VERSION ""

NS_ :

BS_:

BU_: PowertrainControlModule AtmosphericSensor SafetyRestraintSystem2 Aftertreatment_2_GasOutlet Aftertreatment_2_GasIntake DieselParticulateFilterControl Turbocharger SafetyRestraintSystem1 CabDisplay2 Aftertreatment_1_GasOutlet Aftertreatment_1_GasIntake OnBoardDataLogger OffBoardDiagnosticTool2 OffBoardDiagnosticTool1 FileServer ParkingBrakeController SeatController2 FanDriveController SteeringColumnUnit CommunicationUnitRadio CommunicationUnitSatellite CommunicationUnitCellular PropulsionBatteryCharger ChassisController2 ChassisController1 EngineValveControl AuxiliaryHeater2 AuxiliaryHeater1 ClutchUnit RampControl InformationSystem1 SuspensionSystemController2 OilSensor VehicleDynamicStability ExhaustEmissionController TransmissionDisplay2 TransmissionDisplay1 ClimateControl2 WaterPumpController RearAxleSteeringController LightingOperatorControl SeatController1 IgnitionController2 IgnitionController1 TirePressureController CabController2 CabController1 PneumaticSystemController SuspensionSystemController1 HydraulicPumpController EnduranceBrakingSystem RetarderExhaustEngine2 OnBoardDiagnosticUnit HeadwayController RetarderExhaustEngine1 CabDisplay1 ManagementComputer VirtualTerminal OffVehicleGateway PowerTakeOffFront HitchControl AuxiliaryValveControl BodyController TractorTrailerBridge1 StarterSystem ElectricalSystem VehicleSecurity VehicleNavigation AerodynamicControl ElectricalChargingSystem ClimateControl1 TripRecorder InstrumentCluster SuspensionDriveAxle2 SuspensionDriveAxle1 SuspensionSteerAxle SteeringController FuelSystem CruiseControl RetarderDriveline RetarderEngine BrakesDriveAxle2 BrakesDriveAxle1 BrakesSystemController BrakesSteerAxle AxleDrive2 AxleDrive1 AxleSteering PowerTakeOff ShiftConsoleSecondary ShiftConsolePrimary Transmission2 Transmission1 Engine2 Engine1

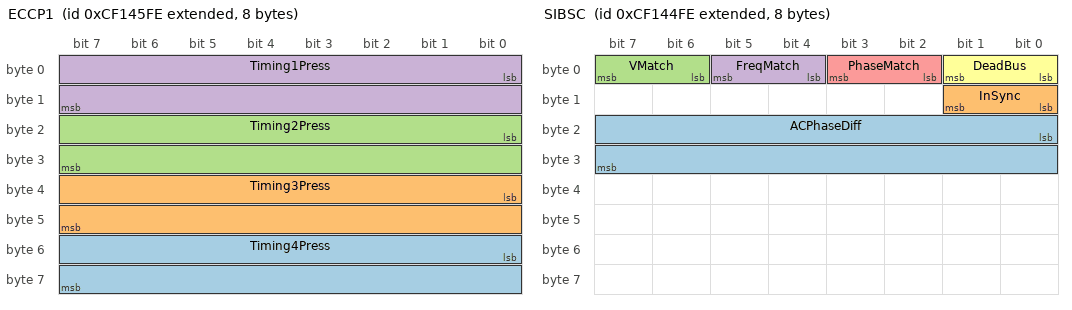
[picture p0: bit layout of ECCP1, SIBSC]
BO_ 2364622334 ECCP1: 8 Vector__XXX
 SG_ Timing4Press : 48|16@1+ (0.0009765625,0) [0|62.7490234375] "MPa" Vector__XXX
 SG_ Timing3Press : 32|16@1+ (0.0009765625,0) [0|62.7490234375] "MPa" Vector__XXX
 SG_ Timing2Press : 16|16@1+ (0.0009765625,0) [0|62.7490234375] "MPa" Vector__XXX
 SG_ Timing1Press : 0|16@1+ (0.0009765625,0) [0|62.7490234375] "MPa" Vector__XXX

BO_ 2364622078 SIBSC: 8 Vector__XXX
 SG_ ACPhaseDiff : 16|16@1+ (0.0078125,-200) [-200|301.9921875] "deg" Vector__XXX
 SG_ InSync : 8|2@1+ (1,0) [0|3] "" Vector__XXX
 SG_ VMatch : 6|2@1+ (1,0) [0|3] "" Vector__XXX
 SG_ FreqMatch : 4|2@1+ (1,0) [0|3] "" Vector__XXX
 SG_ PhaseMatch : 2|2@1+ (1,0) [0|3] "" Vector__XXX
 SG_ DeadBus : 0|2@1+ (1,0) [0|3] "" Vector__XXX

BO_ 2364621822 SIC: 8 Vector__XXX
 SG_ AuxShutdownSw : 2|2@1+ (1,0) [0|3] "" Vector__XXX
 SG_ NotReadyToAutoParallelSt : 0|2@1+ (1,0) [0|3] "" Vector__XXX

BO_ 2364621566 SITACP: 8 Vector__XXX
 SG_ ApparentPwr : 32|32@1+ (1,-2000000000) [-2000000000|2211081215] "VA" Vector__XXX
 SG_ RealPwr : 0|32@1+ (1,-2000000000) [-2000000000|2211081215] "W" Vector__XXX

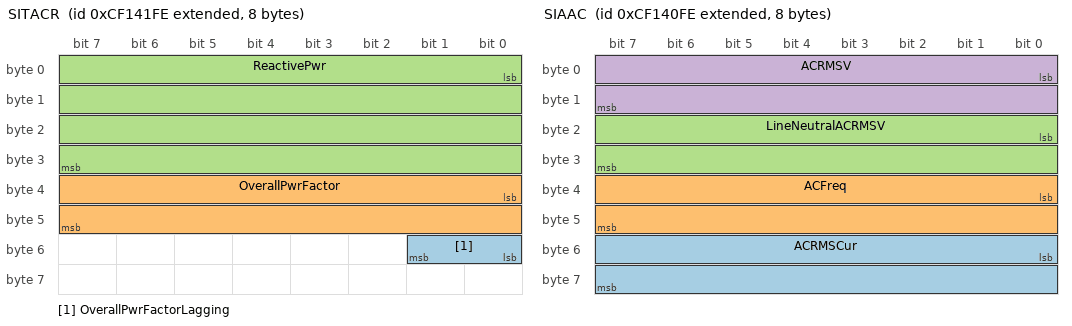
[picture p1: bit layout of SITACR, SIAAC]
BO_ 2364621310 SITACR: 8 Vector__XXX
 SG_ OverallPwrFactorLagging : 48|2@1+ (1,0) [0|3] "" Vector__XXX
 SG_ OverallPwrFactor : 32|16@1+ (6.103515625E-005,-1) [-1|2.92181396484375] "" Vector__XXX
 SG_ ReactivePwr : 0|32@1+ (1,-2000000000) [-2000000000|2211081215] "VAr" Vector__XXX

BO_ 2364621054 SIAAC: 8 Vector__XXX
 SG_ ACRMSCur : 48|16@1+ (1,0) [0|64255] "A" Vector__XXX
 SG_ ACFreq : 32|16@1+ (0.0078125,0) [0|501.9921875] "Hz" Vector__XXX
 SG_ LineNeutralACRMSV : 16|16@1+ (1,0) [0|64255] "V" Vector__XXX
 SG_ ACRMSV : 0|16@1+ (1,0) [0|64255] "V" Vector__XXX

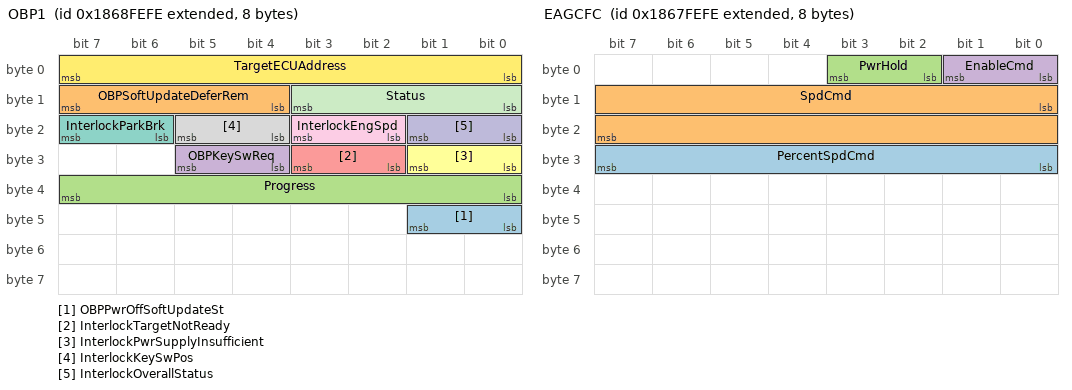
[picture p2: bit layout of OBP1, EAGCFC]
BO_ 2557017854 OBP1: 8 Vector__XXX
 SG_ OBPPwrOffSoftUpdateSt : 40|2@1+ (1,0) [0|3] "" Vector__XXX
 SG_ OBPSoftUpdateDeferRem : 12|4@1+ (1,0) [0|15] "" Vector__XXX
 SG_ Progress : 32|8@1+ (0.5,0) [0|100] "%" Vector__XXX
 SG_ OBPKeySwReq : 28|2@1+ (1,0) [0|3] "" Vector__XXX
 SG_ InterlockTargetNotReady : 26|2@1+ (1,0) [0|3] "" Vector__XXX
 SG_ InterlockPwrSupplyInsufficient : 24|2@1+ (1,0) [0|3] "" Vector__XXX
 SG_ InterlockParkBrk : 22|2@1+ (1,0) [0|3] "" Vector__XXX
 SG_ InterlockKeySwPos : 20|2@1+ (1,0) [0|3] "" Vector__XXX
 SG_ InterlockEngSpd : 18|2@1+ (1,0) [0|3] "" Vector__XXX
 SG_ InterlockOverallStatus : 16|2@1+ (1,0) [0|3] "" Vector__XXX
 SG_ Status : 8|4@1+ (1,0) [0|15] "" Vector__XXX
 SG_ TargetECUAddress : 0|8@1+ (1,0) [0|255] "" Vector__XXX

BO_ 2556952318 EAGCFC: 8 Vector__XXX
 SG_ PercentSpdCmd : 24|8@1+ (0.5,0) [0|100] "%" Vector__XXX
 SG_ SpdCmd : 8|16@1+ (0.5,0) [0|32127.5] "rpm" Vector__XXX
 SG_ PwrHold : 2|2@1+ (1,0) [0|3] "" Vector__XXX
 SG_ EnableCmd : 0|2@1+ (1,0) [0|3] "" Vector__XXX

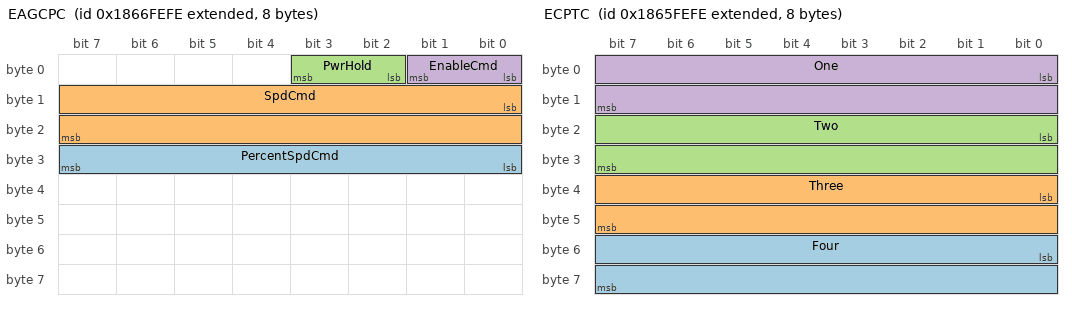
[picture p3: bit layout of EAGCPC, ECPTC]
BO_ 2556886782 EAGCPC: 8 Vector__XXX
 SG_ PercentSpdCmd : 24|8@1+ (0.5,0) [0|100] "%" Vector__XXX
 SG_ SpdCmd : 8|16@1+ (0.5,0) [0|32127.5] "rpm" Vector__XXX
 SG_ PwrHold : 2|2@1+ (1,0) [0|3] "" Vector__XXX
 SG_ EnableCmd : 0|2@1+ (1,0) [0|3] "" Vector__XXX

BO_ 2556821246 ECPTC: 8 Vector__XXX
 SG_ Four : 48|16@1+ (0.0125,-360) [-360|360] "deg" Vector__XXX
 SG_ Three : 32|16@1+ (0.0125,-360) [-360|360] "deg" Vector__XXX
 SG_ Two : 16|16@1+ (0.0125,-360) [-360|360] "deg" Vector__XXX
 SG_ One : 0|16@1+ (0.0125,-360) [-360|360] "deg" Vector__XXX

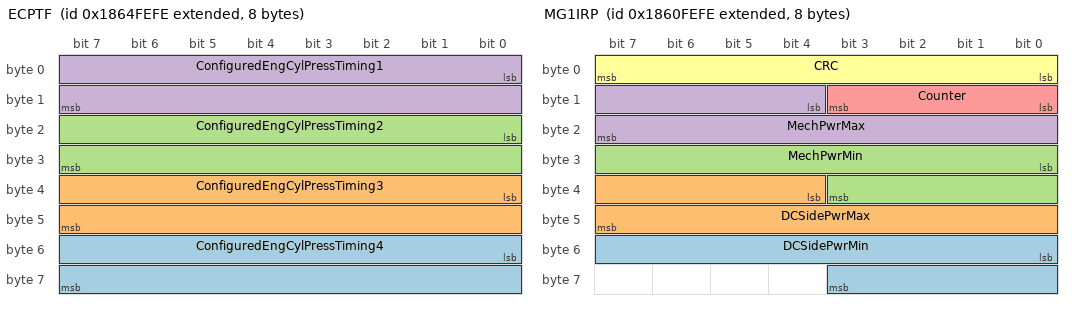
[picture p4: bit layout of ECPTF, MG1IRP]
BO_ 2556755710 ECPTF: 8 Vector__XXX
 SG_ ConfiguredEngCylPressTiming4 : 48|16@1+ (0.0125,-360) [-360|360] "deg" Vector__XXX
 SG_ ConfiguredEngCylPressTiming3 : 32|16@1+ (0.0125,-360) [-360|360] "deg" Vector__XXX
 SG_ ConfiguredEngCylPressTiming2 : 16|16@1+ (0.0125,-360) [-360|360] "deg" Vector__XXX
 SG_ ConfiguredEngCylPressTiming1 : 0|16@1+ (0.0125,-360) [-360|360] "deg" Vector__XXX

BO_ 2556690174 ECCC: 8 Vector__XXX
 SG_ MassFractionBurnedLocation2 : 8|8@1+ (0.4,0) [0|100] "%" Vector__XXX
 SG_ MassFractionBurnedLocation1 : 0|8@1+ (0.4,0) [0|100] "%" Vector__XXX

BO_ 2556624638 ECCCF: 8 Vector__XXX
 SG_ ConfMassFractionBurnedLocation2 : 8|8@1+ (0.4,0) [0|100] "%" Vector__XXX
 SG_ ConfMassFractionBurnedLocation1 : 0|8@1+ (0.4,0) [0|100] "%" Vector__XXX

BO_ 2556559102 PDI: 8 Vector__XXX
 SG_ SequenceCounterEcho : 8|8@1+ (1,0) [0|255] "" Vector__XXX
 SG_ AlarmReceiveStatus : 0|3@1+ (1,0) [0|7] "" Vector__XXX

BO_ 2556493566 MG1IRP: 8 Vector__XXX
 SG_ DCSidePwrMin : 48|12@1+ (0.0625,-125) [-125|125.9375] "%" Vector__XXX
 SG_ DCSidePwrMax : 36|12@1+ (0.0625,-125) [-125|125.9375] "%" Vector__XXX
 SG_ MechPwrMin : 24|12@1+ (0.0625,-125) [-125|125.9375] "%" Vector__XXX
 SG_ MechPwrMax : 12|12@1+ (0.0625,-125) [-125|125.9375] "%" Vector__XXX
 SG_ Counter : 8|4@1+ (1,0) [0|15] "" Vector__XXX
 SG_ CRC : 0|8@1+ (1,0) [0|255] "" Vector__XXX

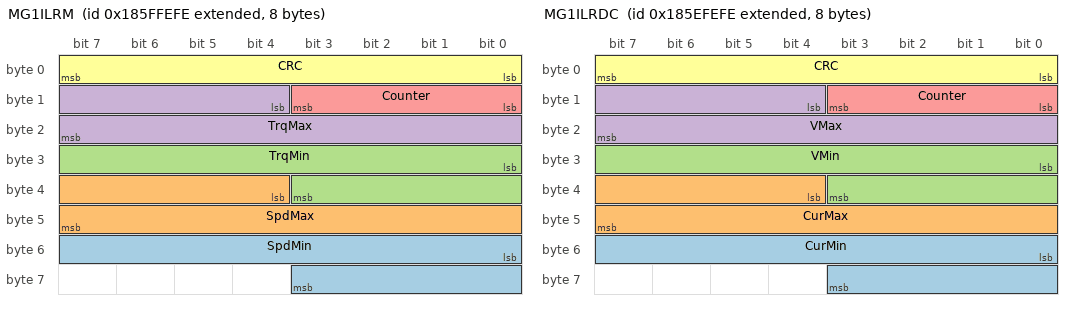
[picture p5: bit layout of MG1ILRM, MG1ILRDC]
BO_ 2556428030 MG1ILRM: 8 Vector__XXX
 SG_ SpdMin : 48|12@1+ (0.0625,-125) [-125|125.9375] "%" Vector__XXX
 SG_ SpdMax : 36|12@1+ (0.0625,-125) [-125|125.9375] "%" Vector__XXX
 SG_ TrqMin : 24|12@1+ (0.0625,-125) [-125|125.9375] "%" Vector__XXX
 SG_ TrqMax : 12|12@1+ (0.0625,-125) [-125|125.9375] "%" Vector__XXX
 SG_ Counter : 8|4@1+ (1,0) [0|15] "" Vector__XXX
 SG_ CRC : 0|8@1+ (1,0) [0|255] "" Vector__XXX

BO_ 2556362494 MG1ILRDC: 8 Vector__XXX
 SG_ CurMin : 48|12@1+ (0.0625,-125) [-125|125.9375] "%" Vector__XXX
 SG_ CurMax : 36|12@1+ (0.0625,-125) [-125|125.9375] "%" Vector__XXX
 SG_ VMin : 24|12@1+ (0.0625,-125) [-125|125.9375] "%" Vector__XXX
 SG_ VMax : 12|12@1+ (0.0625,-125) [-125|125.9375] "%" Vector__XXX
 SG_ Counter : 8|4@1+ (1,0) [0|15] "" Vector__XXX
 SG_ CRC : 0|8@1+ (1,0) [0|255] "" Vector__XXX

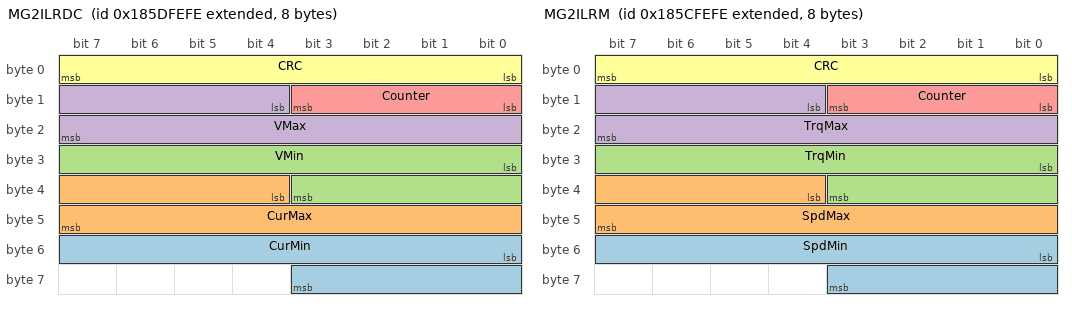
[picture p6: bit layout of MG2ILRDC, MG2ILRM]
BO_ 2556296958 MG2ILRDC: 8 Vector__XXX
 SG_ CurMin : 48|12@1+ (0.0625,-125) [-125|125.9375] "%" Vector__XXX
 SG_ CurMax : 36|12@1+ (0.0625,-125) [-125|125.9375] "%" Vector__XXX
 SG_ VMin : 24|12@1+ (0.0625,-125) [-125|125.9375] "%" Vector__XXX
 SG_ VMax : 12|12@1+ (0.0625,-125) [-125|125.9375] "%" Vector__XXX
 SG_ Counter : 8|4@1+ (1,0) [0|15] "" Vector__XXX
 SG_ CRC : 0|8@1+ (1,0) [0|255] "" Vector__XXX

BO_ 2556231422 MG2ILRM: 8 Vector__XXX
 SG_ SpdMin : 48|12@1+ (0.0625,-125) [-125|125.9375] "%" Vector__XXX
 SG_ SpdMax : 36|12@1+ (0.0625,-125) [-125|125.9375] "%" Vector__XXX
 SG_ TrqMin : 24|12@1+ (0.0625,-125) [-125|125.9375] "%" Vector__XXX
 SG_ TrqMax : 12|12@1+ (0.0625,-125) [-125|125.9375] "%" Vector__XXX
 SG_ Counter : 8|4@1+ (1,0) [0|15] "" Vector__XXX
 SG_ CRC : 0|8@1+ (1,0) [0|255] "" Vector__XXX

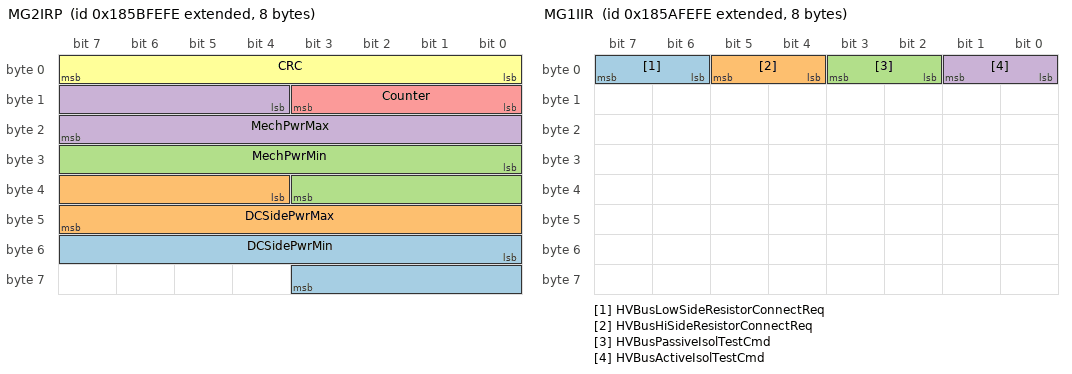
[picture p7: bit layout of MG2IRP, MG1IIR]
BO_ 2556165886 MG2IRP: 8 Vector__XXX
 SG_ DCSidePwrMin : 48|12@1+ (0.0625,-125) [-125|125.9375] "%" Vector__XXX
 SG_ DCSidePwrMax : 36|12@1+ (0.0625,-125) [-125|125.9375] "%" Vector__XXX
 SG_ MechPwrMin : 24|12@1+ (0.0625,-125) [-125|125.9375] "%" Vector__XXX
 SG_ MechPwrMax : 12|12@1+ (0.0625,-125) [-125|125.9375] "%" Vector__XXX
 SG_ Counter : 8|4@1+ (1,0) [0|15] "" Vector__XXX
 SG_ CRC : 0|8@1+ (1,0) [0|255] "" Vector__XXX

BO_ 2556100350 MG1IIR: 8 Vector__XXX
 SG_ HVBusLowSideResistorConnectReq : 6|2@1+ (1,0) [0|3] "" Vector__XXX
 SG_ HVBusHiSideResistorConnectReq : 4|2@1+ (1,0) [0|3] "" Vector__XXX
 SG_ HVBusPassiveIsolTestCmd : 2|2@1+ (1,0) [0|3] "" Vector__XXX
 SG_ HVBusActiveIsolTestCmd : 0|2@1+ (1,0) [0|3] "" Vector__XXX

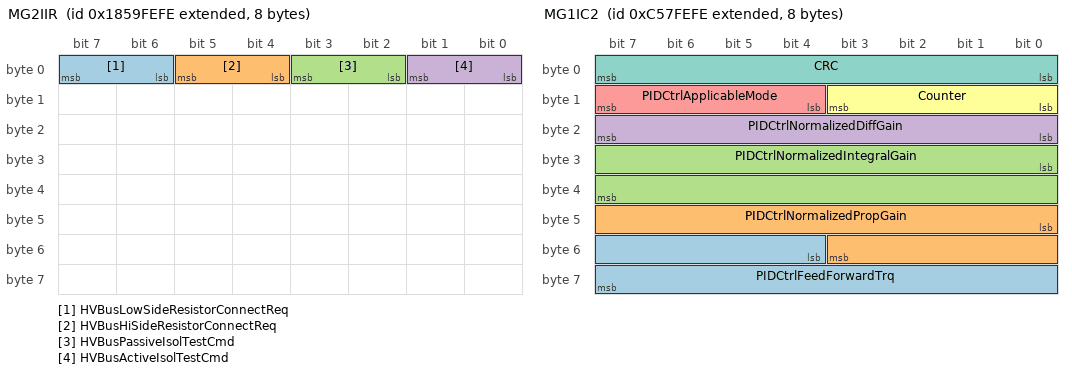
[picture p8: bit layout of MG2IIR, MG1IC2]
BO_ 2556034814 MG2IIR: 8 Vector__XXX
 SG_ HVBusLowSideResistorConnectReq : 6|2@1+ (1,0) [0|3] "" Vector__XXX
 SG_ HVBusHiSideResistorConnectReq : 4|2@1+ (1,0) [0|3] "" Vector__XXX
 SG_ HVBusPassiveIsolTestCmd : 2|2@1+ (1,0) [0|3] "" Vector__XXX
 SG_ HVBusActiveIsolTestCmd : 0|2@1+ (1,0) [0|3] "" Vector__XXX

BO_ 2488860414 HCI2: 8 Vector__XXX
 SG_ DetentStatus : 16|2@1+ (1,0) [0|3] "" Vector__XXX
 SG_ HoistCmd : 0|16@1+ (0.005,-150) [-100|100] "%" Vector__XXX

BO_ 2354577150 MG1IC2: 8 Vector__XXX
 SG_ PIDCtrlFeedForwardTrq : 52|12@1+ (0.0625,-125) [-125|125.9375] "%" Vector__XXX
 SG_ PIDCtrlNormalizedPropGain : 40|12@1+ (0.0625,0) [0|250.9375] "%/%" Vector__XXX
 SG_ PIDCtrlNormalizedIntegralGain : 24|16@1+ (0.015625,0) [0|1003.984375] "%/(%*s)" Vector__XXX
 SG_ PIDCtrlNormalizedDiffGain : 16|8@1+ (0.03125,0) [0|7.8125] "%/(%/s)" Vector__XXX
 SG_ PIDCtrlApplicableMode : 12|4@1+ (1,0) [0|15] "" Vector__XXX
 SG_ Counter : 8|4@1+ (1,0) [0|15] "" Vector__XXX
 SG_ CRC : 0|8@1+ (1,0) [0|255] "" Vector__XXX

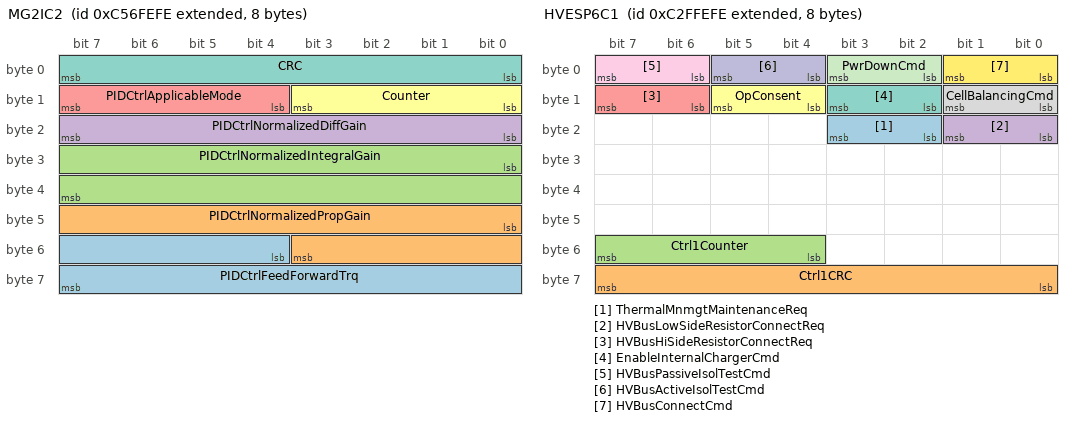
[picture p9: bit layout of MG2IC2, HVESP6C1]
BO_ 2354511614 MG2IC2: 8 Vector__XXX
 SG_ PIDCtrlFeedForwardTrq : 52|12@1+ (0.0625,-125) [-125|125.9375] "%" Vector__XXX
 SG_ PIDCtrlNormalizedPropGain : 40|12@1+ (0.0625,0) [0|250.9375] "%/%" Vector__XXX
 SG_ PIDCtrlNormalizedIntegralGain : 24|16@1+ (0.015625,0) [0|1003.984375] "%/(%*s)" Vector__XXX
 SG_ PIDCtrlNormalizedDiffGain : 16|8@1+ (0.03125,0) [0|7.8125] "%/(%/s)" Vector__XXX
 SG_ PIDCtrlApplicableMode : 12|4@1+ (1,0) [0|15] "" Vector__XXX
 SG_ Counter : 8|4@1+ (1,0) [0|15] "" Vector__XXX
 SG_ CRC : 0|8@1+ (1,0) [0|255] "" Vector__XXX

BO_ 2354446078 ASC8: 8 Vector__XXX
 SG_ LiftAxle3PosCmd : 0|2@1+ (1,0) [0|3] "" Vector__XXX

BO_ 2555707134 WINCH3: 8 Vector__XXX
 SG_ PosReset : 0|2@1+ (1,0) [0|3] "" Vector__XXX

BO_ 2351955710 HVESP6C1: 8 Vector__XXX
 SG_ ThermalMnmgtMaintenanceReq : 18|2@1+ (1,0) [0|3] "" Vector__XXX
 SG_ Ctrl1CRC : 56|8@1+ (1,0) [0|255] "" Vector__XXX
 SG_ Ctrl1Counter : 52|4@1+ (1,0) [0|15] "" Vector__XXX
 SG_ HVBusLowSideResistorConnectReq : 16|2@1+ (1,0) [0|3] "" Vector__XXX
 SG_ HVBusHiSideResistorConnectReq : 14|2@1+ (1,0) [0|3] "" Vector__XXX
 SG_ OpConsent : 12|2@1+ (1,0) [0|3] "" Vector__XXX
 SG_ EnableInternalChargerCmd : 10|2@1+ (1,0) [0|3] "" Vector__XXX
 SG_ CellBalancingCmd : 8|2@1+ (1,0) [0|3] "" Vector__XXX
 SG_ HVBusPassiveIsolTestCmd : 6|2@1+ (1,0) [0|3] "" Vector__XXX
 SG_ HVBusActiveIsolTestCmd : 4|2@1+ (1,0) [0|3] "" Vector__XXX
 SG_ PwrDownCmd : 2|2@1+ (1,0) [0|3] "" Vector__XXX
 SG_ HVBusConnectCmd : 0|2@1+ (1,0) [0|3] "" Vector__XXX

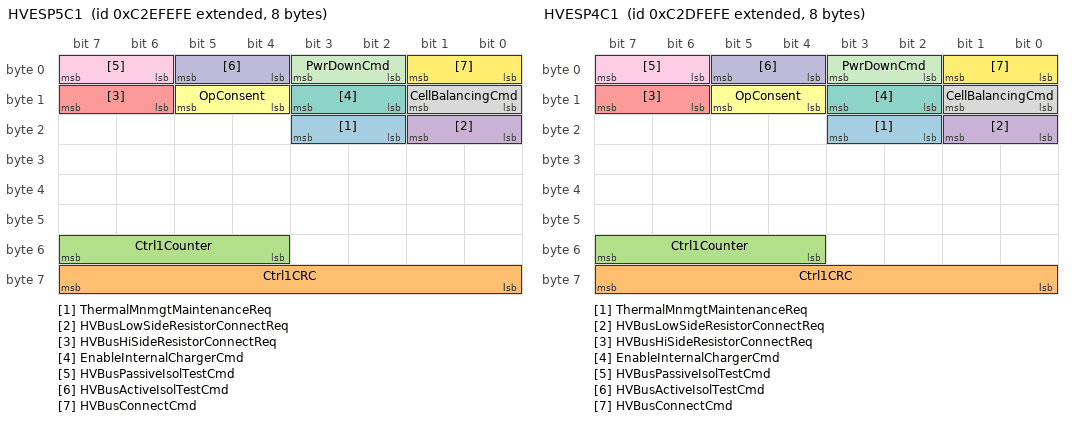
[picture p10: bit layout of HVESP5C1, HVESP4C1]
BO_ 2351890174 HVESP5C1: 8 Vector__XXX
 SG_ ThermalMnmgtMaintenanceReq : 18|2@1+ (1,0) [0|3] "" Vector__XXX
 SG_ Ctrl1CRC : 56|8@1+ (1,0) [0|255] "" Vector__XXX
 SG_ Ctrl1Counter : 52|4@1+ (1,0) [0|15] "" Vector__XXX
 SG_ HVBusLowSideResistorConnectReq : 16|2@1+ (1,0) [0|3] "" Vector__XXX
 SG_ HVBusHiSideResistorConnectReq : 14|2@1+ (1,0) [0|3] "" Vector__XXX
 SG_ OpConsent : 12|2@1+ (1,0) [0|3] "" Vector__XXX
 SG_ EnableInternalChargerCmd : 10|2@1+ (1,0) [0|3] "" Vector__XXX
 SG_ CellBalancingCmd : 8|2@1+ (1,0) [0|3] "" Vector__XXX
 SG_ HVBusPassiveIsolTestCmd : 6|2@1+ (1,0) [0|3] "" Vector__XXX
 SG_ HVBusActiveIsolTestCmd : 4|2@1+ (1,0) [0|3] "" Vector__XXX
 SG_ PwrDownCmd : 2|2@1+ (1,0) [0|3] "" Vector__XXX
 SG_ HVBusConnectCmd : 0|2@1+ (1,0) [0|3] "" Vector__XXX

BO_ 2351824638 HVESP4C1: 8 Vector__XXX
 SG_ ThermalMnmgtMaintenanceReq : 18|2@1+ (1,0) [0|3] "" Vector__XXX
 SG_ Ctrl1CRC : 56|8@1+ (1,0) [0|255] "" Vector__XXX
 SG_ Ctrl1Counter : 52|4@1+ (1,0) [0|15] "" Vector__XXX
 SG_ HVBusLowSideResistorConnectReq : 16|2@1+ (1,0) [0|3] "" Vector__XXX
 SG_ HVBusHiSideResistorConnectReq : 14|2@1+ (1,0) [0|3] "" Vector__XXX
 SG_ OpConsent : 12|2@1+ (1,0) [0|3] "" Vector__XXX
 SG_ EnableInternalChargerCmd : 10|2@1+ (1,0) [0|3] "" Vector__XXX
 SG_ CellBalancingCmd : 8|2@1+ (1,0) [0|3] "" Vector__XXX
 SG_ HVBusPassiveIsolTestCmd : 6|2@1+ (1,0) [0|3] "" Vector__XXX
 SG_ HVBusActiveIsolTestCmd : 4|2@1+ (1,0) [0|3] "" Vector__XXX
 SG_ PwrDownCmd : 2|2@1+ (1,0) [0|3] "" Vector__XXX
 SG_ HVBusConnectCmd : 0|2@1+ (1,0) [0|3] "" Vector__XXX

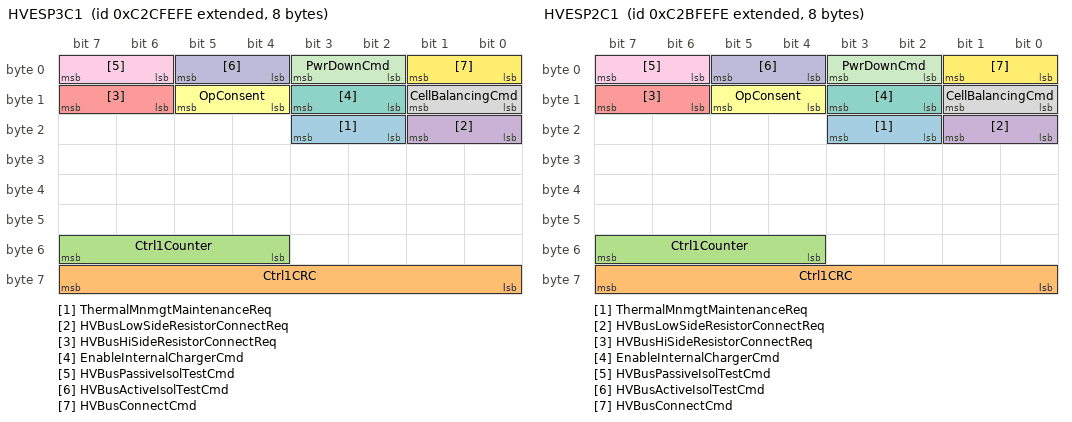
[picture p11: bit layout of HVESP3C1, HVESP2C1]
BO_ 2351759102 HVESP3C1: 8 Vector__XXX
 SG_ ThermalMnmgtMaintenanceReq : 18|2@1+ (1,0) [0|3] "" Vector__XXX
 SG_ Ctrl1CRC : 56|8@1+ (1,0) [0|255] "" Vector__XXX
 SG_ Ctrl1Counter : 52|4@1+ (1,0) [0|15] "" Vector__XXX
 SG_ HVBusLowSideResistorConnectReq : 16|2@1+ (1,0) [0|3] "" Vector__XXX
 SG_ HVBusHiSideResistorConnectReq : 14|2@1+ (1,0) [0|3] "" Vector__XXX
 SG_ OpConsent : 12|2@1+ (1,0) [0|3] "" Vector__XXX
 SG_ EnableInternalChargerCmd : 10|2@1+ (1,0) [0|3] "" Vector__XXX
 SG_ CellBalancingCmd : 8|2@1+ (1,0) [0|3] "" Vector__XXX
 SG_ HVBusPassiveIsolTestCmd : 6|2@1+ (1,0) [0|3] "" Vector__XXX
 SG_ HVBusActiveIsolTestCmd : 4|2@1+ (1,0) [0|3] "" Vector__XXX
 SG_ PwrDownCmd : 2|2@1+ (1,0) [0|3] "" Vector__XXX
 SG_ HVBusConnectCmd : 0|2@1+ (1,0) [0|3] "" Vector__XXX

BO_ 2351693566 HVESP2C1: 8 Vector__XXX
 SG_ ThermalMnmgtMaintenanceReq : 18|2@1+ (1,0) [0|3] "" Vector__XXX
 SG_ Ctrl1CRC : 56|8@1+ (1,0) [0|255] "" Vector__XXX
 SG_ Ctrl1Counter : 52|4@1+ (1,0) [0|15] "" Vector__XXX
 SG_ HVBusLowSideResistorConnectReq : 16|2@1+ (1,0) [0|3] "" Vector__XXX
 SG_ HVBusHiSideResistorConnectReq : 14|2@1+ (1,0) [0|3] "" Vector__XXX
 SG_ OpConsent : 12|2@1+ (1,0) [0|3] "" Vector__XXX
 SG_ EnableInternalChargerCmd : 10|2@1+ (1,0) [0|3] "" Vector__XXX
 SG_ CellBalancingCmd : 8|2@1+ (1,0) [0|3] "" Vector__XXX
 SG_ HVBusPassiveIsolTestCmd : 6|2@1+ (1,0) [0|3] "" Vector__XXX
 SG_ HVBusActiveIsolTestCmd : 4|2@1+ (1,0) [0|3] "" Vector__XXX
 SG_ PwrDownCmd : 2|2@1+ (1,0) [0|3] "" Vector__XXX
 SG_ HVBusConnectCmd : 0|2@1+ (1,0) [0|3] "" Vector__XXX

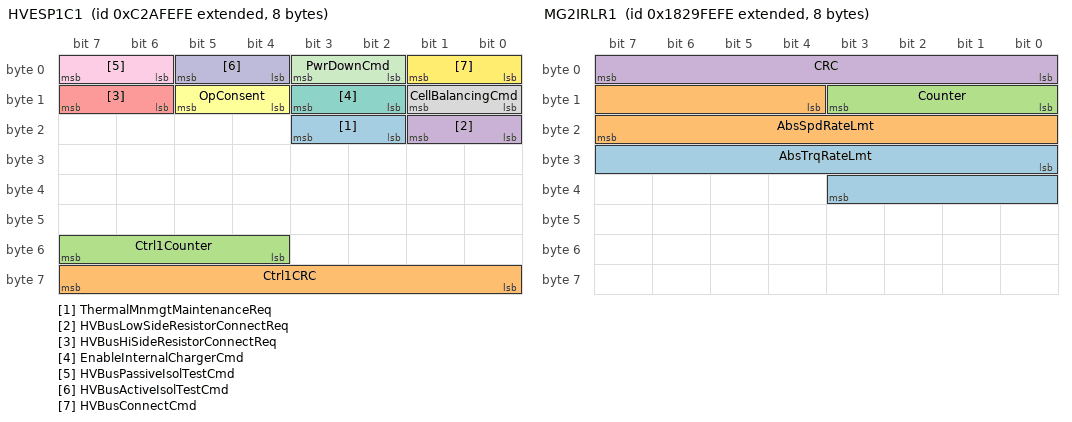
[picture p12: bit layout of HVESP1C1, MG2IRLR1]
BO_ 2351628030 HVESP1C1: 8 Vector__XXX
 SG_ ThermalMnmgtMaintenanceReq : 18|2@1+ (1,0) [0|3] "" Vector__XXX
 SG_ Ctrl1CRC : 56|8@1+ (1,0) [0|255] "" Vector__XXX
 SG_ Ctrl1Counter : 52|4@1+ (1,0) [0|15] "" Vector__XXX
 SG_ HVBusLowSideResistorConnectReq : 16|2@1+ (1,0) [0|3] "" Vector__XXX
 SG_ HVBusHiSideResistorConnectReq : 14|2@1+ (1,0) [0|3] "" Vector__XXX
 SG_ OpConsent : 12|2@1+ (1,0) [0|3] "" Vector__XXX
 SG_ EnableInternalChargerCmd : 10|2@1+ (1,0) [0|3] "" Vector__XXX
 SG_ CellBalancingCmd : 8|2@1+ (1,0) [0|3] "" Vector__XXX
 SG_ HVBusPassiveIsolTestCmd : 6|2@1+ (1,0) [0|3] "" Vector__XXX
 SG_ HVBusActiveIsolTestCmd : 4|2@1+ (1,0) [0|3] "" Vector__XXX
 SG_ PwrDownCmd : 2|2@1+ (1,0) [0|3] "" Vector__XXX
 SG_ HVBusConnectCmd : 0|2@1+ (1,0) [0|3] "" Vector__XXX

BO_ 2552889086 MG2IRLR1: 8 Vector__XXX
 SG_ AbsTrqRateLmt : 24|12@1+ (2,0) [0|8030] "%/s" Vector__XXX
 SG_ AbsSpdRateLmt : 12|12@1+ (0.25,0) [0|1003.75] "%/s" Vector__XXX
 SG_ Counter : 8|4@1+ (1,0) [0|15] "" Vector__XXX
 SG_ CRC : 0|8@1+ (1,0) [0|255] "" Vector__XXX

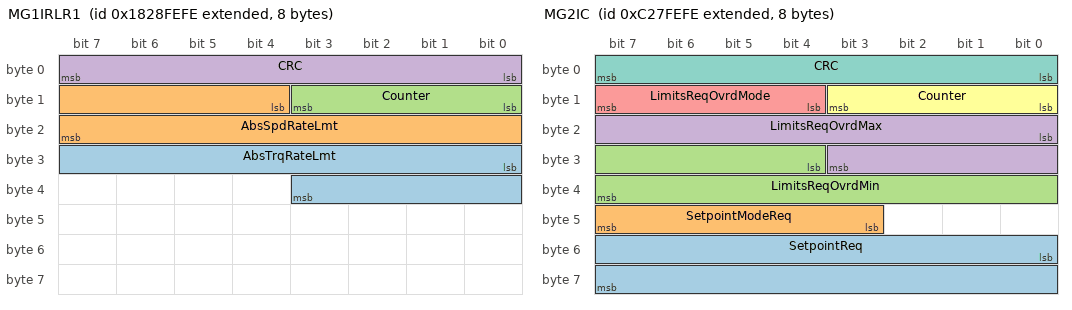
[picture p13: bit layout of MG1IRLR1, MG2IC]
BO_ 2552823550 MG1IRLR1: 8 Vector__XXX
 SG_ AbsTrqRateLmt : 24|12@1+ (2,0) [0|8030] "%/s" Vector__XXX
 SG_ AbsSpdRateLmt : 12|12@1+ (0.25,0) [0|1003.75] "%/s" Vector__XXX
 SG_ Counter : 8|4@1+ (1,0) [0|15] "" Vector__XXX
 SG_ CRC : 0|8@1+ (1,0) [0|255] "" Vector__XXX

BO_ 2351431422 MG2IC: 8 Vector__XXX
 SG_ SetpointReq : 48|16@1+ (0.00390625,-125) [-125|125.99609375] "%" Vector__XXX
 SG_ SetpointModeReq : 43|5@1+ (1,0) [0|31] "" Vector__XXX
 SG_ LimitsReqOvrdMin : 28|12@1+ (0.0625,-125) [-125|125.9375] "%" Vector__XXX
 SG_ LimitsReqOvrdMax : 16|12@1+ (0.0625,-125) [-125|125.9375] "%" Vector__XXX
 SG_ LimitsReqOvrdMode : 12|4@1+ (1,0) [0|15] "" Vector__XXX
 SG_ Counter : 8|4@1+ (1,0) [0|15] "" Vector__XXX
 SG_ CRC : 0|8@1+ (1,0) [0|255] "" Vector__XXX

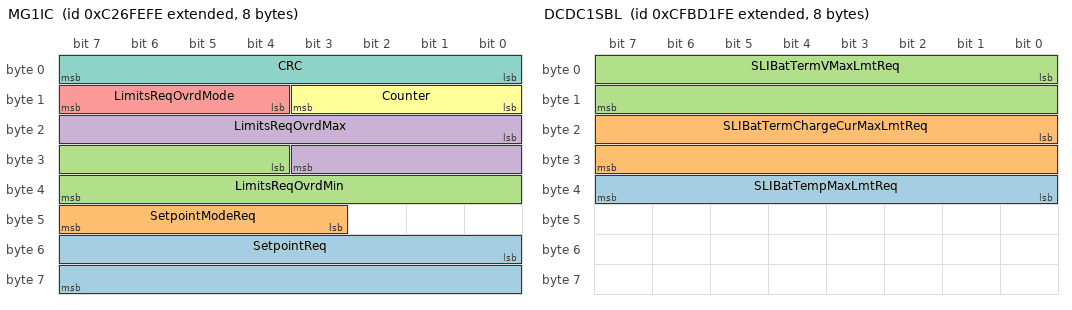
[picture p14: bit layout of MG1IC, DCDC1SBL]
BO_ 2351365886 MG1IC: 8 Vector__XXX
 SG_ SetpointReq : 48|16@1+ (0.00390625,-125) [-125|125.99609375] "%" Vector__XXX
 SG_ SetpointModeReq : 43|5@1+ (1,0) [0|31] "" Vector__XXX
 SG_ LimitsReqOvrdMin : 28|12@1+ (0.0625,-125) [-125|125.9375] "%" Vector__XXX
 SG_ LimitsReqOvrdMax : 16|12@1+ (0.0625,-125) [-125|125.9375] "%" Vector__XXX
 SG_ LimitsReqOvrdMode : 12|4@1+ (1,0) [0|15] "" Vector__XXX
 SG_ Counter : 8|4@1+ (1,0) [0|15] "" Vector__XXX
 SG_ CRC : 0|8@1+ (1,0) [0|255] "" Vector__XXX

BO_ 2365313534 DCDC1SBL: 8 Vector__XXX
 SG_ SLIBatTempMaxLmtReq : 32|8@1+ (1,-40) [-40|210] "°C" Vector__XXX
 SG_ SLIBatTermChargeCurMaxLmtReq : 16|16@1+ (0.05,0) [0|3212.75] "A" Vector__XXX
 SG_ SLIBatTermVMaxLmtReq : 0|16@1+ (0.01,0) [0|642.55] "V" Vector__XXX

BO_ 2566639870 DCDC1CFG1: 19 Vector__XXX
 SG_ OneLowSideVBuckDefaultSetting : 136|16@1+ (0.01,0) [0|642.55] "V" Vector__XXX
 SG_ SLIBatTempMaxLmtSetting : 128|8@1+ (1,-40) [-40|210] "°C" Vector__XXX
 SG_ SLIBatTermChargeCurMaxLmtSetting : 112|16@1+ (0.05,0) [0|3212.75] "A" Vector__XXX
 SG_ SLIBatTermVMaxLmtSetting : 96|16@1+ (0.01,0) [0|642.55] "V" Vector__XXX
 SG_ OneLowSideCurMaxLmtSetting : 80|16@1+ (0.05,0) [0|3212.75] "A" Vector__XXX
 SG_ OneLowSideVMaxLmtSetting : 64|16@1+ (0.01,0) [0|642.55] "V" Vector__XXX
 SG_ OneLowSideVMinLmtSetting : 48|16@1+ (0.01,0) [0|642.55] "V" Vector__XXX
 SG_ OneHiSideCurMaxLmtSetting : 32|16@1+ (0.05,0) [0|3212.75] "A" Vector__XXX
 SG_ OneHiSideVMaxLmtSetting : 16|16@1+ (0.05,0) [0|3212.75] "V" Vector__XXX
 SG_ OneHiSideVMinLmtSetting : 0|16@1+ (0.05,0) [0|3212.75] "V" Vector__XXX

BO_ 2566639614 DCDC1LD: 16 Vector__XXX
 SG_ OneTotalLowSideCharge : 96|32@1+ (100,0) [0|421108121500] "Ah" Vector__XXX
 SG_ OneTotalHiSideCharge : 64|32@1+ (100,0) [0|421108121500] "Ah" Vector__XXX
 SG_ OneTotalLowSideEnergy : 32|32@1+ (100,0) [0|421108121500] "Wh" Vector__XXX
 SG_ OneTotalHiSideEnergy : 0|32@1+ (100,0) [0|421108121500] "Wh" Vector__XXX

BO_ 2633748222 CRSS: 8 Vector__XXX
 SG_ SPNModifiedStatus : 48|2@1+ (1,0) [0|3] "" Vector__XXX
 SG_ SPNSA : 40|8@1+ (1,0) [0|255] "" Vector__XXX
 SG_ SPNDetailedStatus : 32|5@1+ (1,0) [0|31] "" Vector__XXX
 SG_ SPN : 16|19@1+ (1,0) [0|524287] "" Vector__XXX
 SG_ PortCmdStatus : 5|3@1+ (1,0) [0|7] "" Vector__XXX
 SG_ PortPendingChangesStatus : 4|1@1+ (1,0) [0|1] "" Vector__XXX
 SG_ Port : 0|4@1+ (1,0) [0|15] "" Vector__XXX

BO_ 2566639102 WSPT2: 19 Vector__XXX
 SG_ PlungerFiringOrderSetting : 144|4@1+ (1,0) [0|15] "" Vector__XXX
 SG_ RodLoadHiThreshold : 128|16@1+ (5,0) [0|321275] "kN" Vector__XXX
 SG_ CrankshaftSpdHiThreshold : 112|16@1+ (0.125,0) [0|8031.875] "rpm" Vector__XXX
 SG_ CrankshaftSpdLowThreshold : 96|16@1+ (0.125,0) [0|8031.875] "rpm" Vector__XXX
 SG_ DisPressHiThreshold : 80|16@1+ (5,0) [0|321275] "kPa" Vector__XXX
 SG_ SuctionPressHiThreshold : 64|16@1+ (0.1,-3212.7) [-3212.7|3212.8] "kPa" Vector__XXX
 SG_ SuctionPressLowThreshold : 48|16@1+ (0.1,-3212.7) [-3212.7|3212.8] "kPa" Vector__XXX
 SG_ GearBoxOilTempHiThreshold : 40|8@1+ (1,-40) [-40|210] "°C" Vector__XXX
 SG_ GearBoxOilTempLowThreshold : 32|8@1+ (1,-40) [-40|210] "°C" Vector__XXX
 SG_ GearBoxOilPressHiThreshold : 16|16@1+ (0.1,0) [0|6425.5] "kPa" Vector__XXX
 SG_ GearBoxOilPressLowThreshold : 0|16@1+ (0.1,0) [0|6425.5] "kPa" Vector__XXX

BO_ 2566638846 WSPH: 16 Vector__XXX
 SG_ VlvSeatOpHours : 96|32@1+ (1,0) [0|4211081215] "s" Vector__XXX
 SG_ PackingOpHours : 64|32@1+ (1,0) [0|4211081215] "s" Vector__XXX
 SG_ VlvOpHours : 32|32@1+ (1,0) [0|4211081215] "s" Vector__XXX
 SG_ MaintenanceIntervalHours : 0|32@1+ (1,0) [0|4211081215] "s" Vector__XXX

BO_ 2566638590 EEPCSI: 8 Vector__XXX
 SG_ DiagCount : 32|32@1+ (1,0) [0|4211081215] "" Vector__XXX
 SG_ DiagTime : 0|32@1+ (1,0) [0|4211081215] "s" Vector__XXX

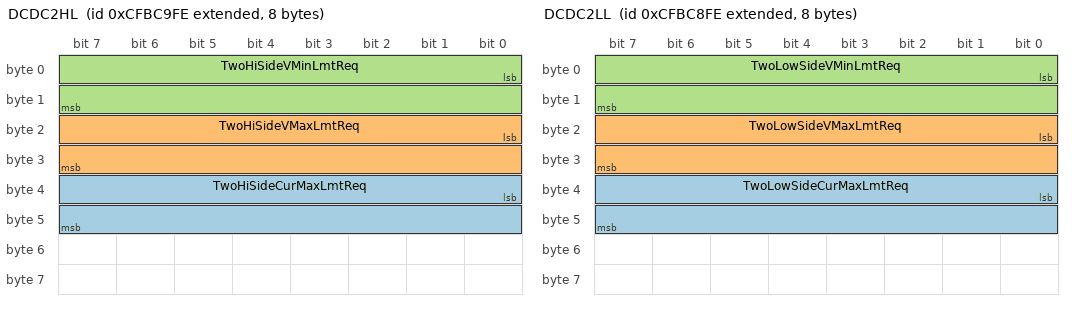
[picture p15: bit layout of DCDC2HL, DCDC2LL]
BO_ 2365311486 DCDC2HL: 8 Vector__XXX
 SG_ TwoHiSideCurMaxLmtReq : 32|16@1+ (0.05,0) [0|3212.75] "A" Vector__XXX
 SG_ TwoHiSideVMaxLmtReq : 16|16@1+ (0.05,0) [0|3212.75] "V" Vector__XXX
 SG_ TwoHiSideVMinLmtReq : 0|16@1+ (0.05,0) [0|3212.75] "V" Vector__XXX

BO_ 2365311230 DCDC2LL: 8 Vector__XXX
 SG_ TwoLowSideCurMaxLmtReq : 32|16@1+ (0.05,0) [0|3212.75] "A" Vector__XXX
 SG_ TwoLowSideVMaxLmtReq : 16|16@1+ (0.01,0) [0|642.55] "V" Vector__XXX
 SG_ TwoLowSideVMinLmtReq : 0|16@1+ (0.01,0) [0|642.55] "V" Vector__XXX

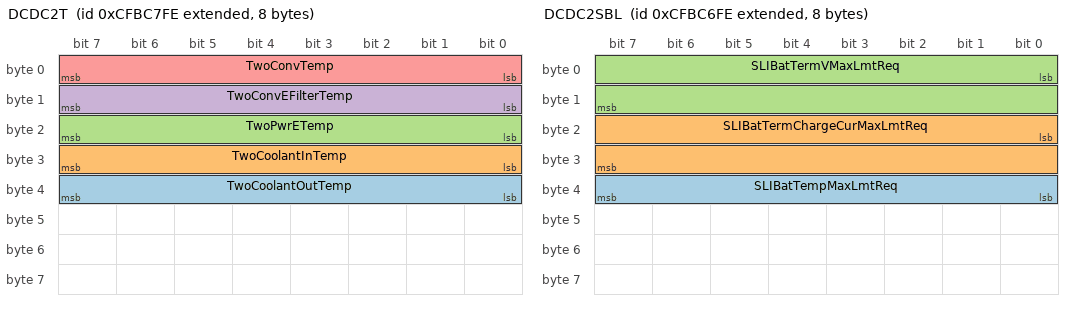
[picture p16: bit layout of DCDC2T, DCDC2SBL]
BO_ 2365310974 DCDC2T: 8 Vector__XXX
 SG_ TwoCoolantOutTemp : 32|8@1+ (1,-40) [-40|210] "°C" Vector__XXX
 SG_ TwoCoolantInTemp : 24|8@1+ (1,-40) [-40|210] "°C" Vector__XXX
 SG_ TwoPwrETemp : 16|8@1+ (1,-40) [-40|210] "°C" Vector__XXX
 SG_ TwoConvEFilterTemp : 8|8@1+ (1,-40) [-40|210] "°C" Vector__XXX
 SG_ TwoConvTemp : 0|8@1+ (1,-40) [-40|210] "°C" Vector__XXX

BO_ 2365310718 DCDC2SBL: 8 Vector__XXX
 SG_ SLIBatTempMaxLmtReq : 32|8@1+ (1,-40) [-40|210] "°C" Vector__XXX
 SG_ SLIBatTermChargeCurMaxLmtReq : 16|16@1+ (0.05,0) [0|3212.75] "A" Vector__XXX
 SG_ SLIBatTermVMaxLmtReq : 0|16@1+ (0.01,0) [0|642.55] "V" Vector__XXX

BO_ 2566637054 DCDC2CFG1: 19 Vector__XXX
 SG_ TwoLowSideVBuckDefaultSetting : 136|16@1+ (0.01,0) [0|642.55] "V" Vector__XXX
 SG_ SLIBatTempMaxLmtSetting : 128|8@1+ (1,-40) [-40|210] "°C" Vector__XXX
 SG_ SLIBatTermChargeCurMaxLmtSetting : 112|16@1+ (0.05,0) [0|3212.75] "A" Vector__XXX
 SG_ SLIBatTermVMaxLmtSetting : 96|16@1+ (0.01,0) [0|642.55] "V" Vector__XXX
 SG_ TwoLowSideCurMaxLmtSetting : 80|16@1+ (0.05,0) [0|3212.75] "A" Vector__XXX
 SG_ TwoLowSideVMaxLmtSetting : 64|16@1+ (0.01,0) [0|642.55] "V" Vector__XXX
 SG_ TwoLowSideVMinLmtSetting : 48|16@1+ (0.01,0) [0|642.55] "V" Vector__XXX
 SG_ TwoHiSideCurMaxLmtSetting : 32|16@1+ (0.05,0) [0|3212.75] "A" Vector__XXX
 SG_ TwoHiSideVMaxLmtSetting : 16|16@1+ (0.05,0) [0|3212.75] "V" Vector__XXX
 SG_ TwoHiSideVMinLmtSetting : 0|16@1+ (0.05,0) [0|3212.75] "V" Vector__XXX

BO_ 2566636798 DCDC2LD: 16 Vector__XXX
 SG_ TwoTotalLowSideCharge : 96|32@1+ (100,0) [0|421108121500] "Ah" Vector__XXX
 SG_ TwoTotalHiSideCharge : 64|32@1+ (100,0) [0|421108121500] "Ah" Vector__XXX
 SG_ TwoTotalLowSideEnergy : 32|32@1+ (100,0) [0|421108121500] "Wh" Vector__XXX
 SG_ TwoTotalHiSideEnergy : 0|32@1+ (100,0) [0|421108121500] "Wh" Vector__XXX

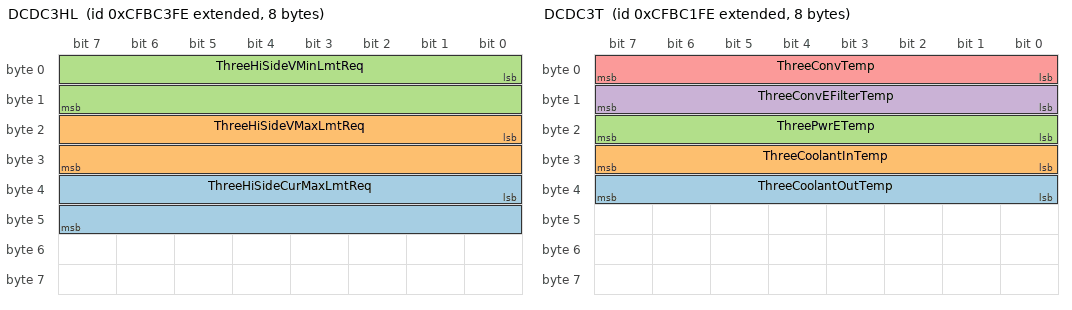
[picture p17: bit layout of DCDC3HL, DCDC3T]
BO_ 2365309950 DCDC3HL: 8 Vector__XXX
 SG_ ThreeHiSideCurMaxLmtReq : 32|16@1+ (0.05,0) [0|3212.75] "A" Vector__XXX
 SG_ ThreeHiSideVMaxLmtReq : 16|16@1+ (0.05,0) [0|3212.75] "V" Vector__XXX
 SG_ ThreeHiSideVMinLmtReq : 0|16@1+ (0.05,0) [0|3212.75] "V" Vector__XXX

BO_ 2365309694 DCDC3LL: 8 Vector__XXX
 SG_ ThreeLowSideCurMaxLmtReq : 32|16@1+ (0.05,0) [0|3212.75] "A" Vector__XXX
 SG_ ThreeLowSideVMaxLmtReq : 16|16@1+ (0.01,0) [0|642.55] "V" Vector__XXX
 SG_ ThreeLowSideVMinLmtReq : 0|16@1+ (0.01,0) [0|642.55] "V" Vector__XXX

BO_ 2365309438 DCDC3T: 8 Vector__XXX
 SG_ ThreeCoolantOutTemp : 32|8@1+ (1,-40) [-40|210] "°C" Vector__XXX
 SG_ ThreeCoolantInTemp : 24|8@1+ (1,-40) [-40|210] "°C" Vector__XXX
 SG_ ThreePwrETemp : 16|8@1+ (1,-40) [-40|210] "°C" Vector__XXX
 SG_ ThreeConvEFilterTemp : 8|8@1+ (1,-40) [-40|210] "°C" Vector__XXX
 SG_ ThreeConvTemp : 0|8@1+ (1,-40) [-40|210] "°C" Vector__XXX

BO_ 2365309182 DCDC3SBL: 8 Vector__XXX
 SG_ SLIBatTempMaxLmtReq : 32|8@1+ (1,-40) [-40|210] "°C" Vector__XXX
 SG_ SLIBatTermChargeCurMaxLmtReq : 16|16@1+ (0.05,0) [0|3212.75] "A" Vector__XXX
 SG_ SLIBatTermVMaxLmtReq : 0|16@1+ (0.01,0) [0|642.55] "V" Vector__XXX

BO_ 2566635518 DCDC3CFG1: 19 Vector__XXX
 SG_ ThreeLowSideVBuckDefaultSetting : 136|16@1+ (0.01,0) [0|642.55] "V" Vector__XXX
 SG_ SLIBatTempMaxLmtSetting : 128|8@1+ (1,-40) [-40|210] "°C" Vector__XXX
 SG_ SLIBatTermChargeCurMaxLmtSetting : 112|16@1+ (0.05,0) [0|3212.75] "A" Vector__XXX
 SG_ SLIBatTermVMaxLmtSetting : 96|16@1+ (0.01,0) [0|642.55] "V" Vector__XXX
 SG_ ThreeLowSideCurMaxLmtSetting : 80|16@1+ (0.05,0) [0|3212.75] "A" Vector__XXX
 SG_ ThreeLowSideVMaxLmtSetting : 64|16@1+ (0.01,0) [0|642.55] "V" Vector__XXX
 SG_ ThreeLowSideVMinLmtSetting : 48|16@1+ (0.01,0) [0|642.55] "V" Vector__XXX
 SG_ ThreeHiSideCurMaxLmtSetting : 32|16@1+ (0.05,0) [0|3212.75] "A" Vector__XXX
 SG_ ThreeHiSideVMaxLmtSetting : 16|16@1+ (0.05,0) [0|3212.75] "V" Vector__XXX
 SG_ ThreeHiSideVMinLmtSetting : 0|16@1+ (0.05,0) [0|3212.75] "V" Vector__XXX

BO_ 2566635262 DCDC3LD: 16 Vector__XXX
 SG_ ThreeTotalLowSideCharge : 96|32@1+ (100,0) [0|421108121500] "Ah" Vector__XXX
 SG_ ThreeTotalHiSideCharge : 64|32@1+ (100,0) [0|421108121500] "Ah" Vector__XXX
 SG_ ThreeTotalLowSideEnergy : 32|32@1+ (100,0) [0|421108121500] "Wh" Vector__XXX
 SG_ ThreeTotalHiSideEnergy : 0|32@1+ (100,0) [0|421108121500] "Wh" Vector__XXX

BO_ 2365308414 DCDC4HL: 8 Vector__XXX
 SG_ FourHiSideCurMaxLmtReq : 32|16@1+ (0.05,0) [0|3212.75] "A" Vector__XXX
 SG_ FourHiSideVMaxLmtReq : 16|16@1+ (0.05,0) [0|3212.75] "V" Vector__XXX
 SG_ FourHiSideVMinLmtReq : 0|16@1+ (0.05,0) [0|3212.75] "V" Vector__XXX

BO_ 2365308158 DCDC4LL: 8 Vector__XXX
 SG_ FourLowSideCurMaxLmtReq : 32|16@1+ (0.05,0) [0|3212.75] "A" Vector__XXX
 SG_ FourLowSideVMaxLmtReq : 16|16@1+ (0.01,0) [0|642.55] "V" Vector__XXX
 SG_ FourLowSideVMinLmtReq : 0|16@1+ (0.01,0) [0|642.55] "V" Vector__XXX

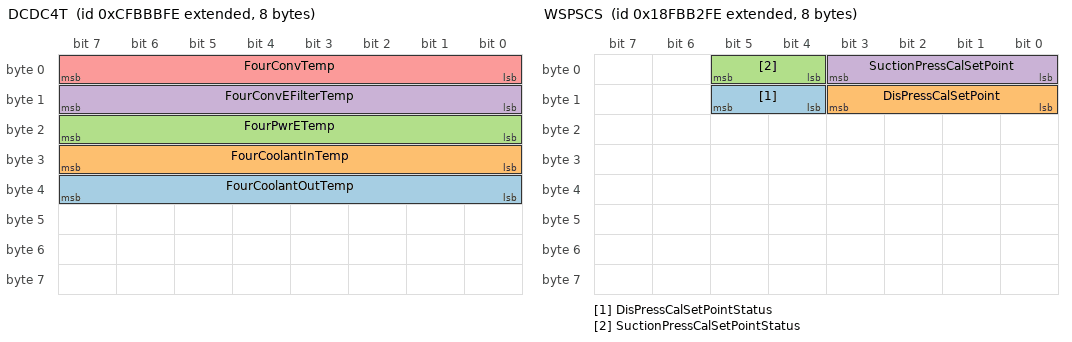
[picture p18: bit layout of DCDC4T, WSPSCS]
BO_ 2365307902 DCDC4T: 8 Vector__XXX
 SG_ FourCoolantOutTemp : 32|8@1+ (1,-40) [-40|210] "°C" Vector__XXX
 SG_ FourCoolantInTemp : 24|8@1+ (1,-40) [-40|210] "°C" Vector__XXX
 SG_ FourPwrETemp : 16|8@1+ (1,-40) [-40|210] "°C" Vector__XXX
 SG_ FourConvEFilterTemp : 8|8@1+ (1,-40) [-40|210] "°C" Vector__XXX
 SG_ FourConvTemp : 0|8@1+ (1,-40) [-40|210] "°C" Vector__XXX

BO_ 2365307646 DCDC4SBL: 8 Vector__XXX
 SG_ SLIBatTempMaxLmtReq : 32|8@1+ (1,-40) [-40|210] "°C" Vector__XXX
 SG_ SLIBatTermChargeCurMaxLmtReq : 16|16@1+ (0.05,0) [0|3212.75] "A" Vector__XXX
 SG_ SLIBatTermVMaxLmtReq : 0|16@1+ (0.01,0) [0|642.55] "V" Vector__XXX

BO_ 2566633982 DCDC4CFG1: 19 Vector__XXX
 SG_ FourLowSideVBuckDefaultSetting : 136|16@1+ (0.01,0) [0|642.55] "V" Vector__XXX
 SG_ SLIBatTempMaxLmtSetting : 128|8@1+ (1,-40) [-40|210] "°C" Vector__XXX
 SG_ SLIBatTermChargeCurMaxLmtSetting : 112|16@1+ (0.05,0) [0|3212.75] "A" Vector__XXX
 SG_ SLIBatTermVMaxLmtSetting : 96|16@1+ (0.01,0) [0|642.55] "V" Vector__XXX
 SG_ FourLowSideCurMaxLmtSetting : 80|16@1+ (0.05,0) [0|3212.75] "A" Vector__XXX
 SG_ FourLowSideVMaxLmtSetting : 64|16@1+ (0.01,0) [0|642.55] "V" Vector__XXX
 SG_ FourLowSideVMinLmtSetting : 48|16@1+ (0.01,0) [0|642.55] "V" Vector__XXX
 SG_ FourHiSideCurMaxLmtSetting : 32|16@1+ (0.05,0) [0|3212.75] "A" Vector__XXX
 SG_ FourHiSideVMaxLmtSetting : 16|16@1+ (0.05,0) [0|3212.75] "V" Vector__XXX
 SG_ FourHiSideVMinLmtSetting : 0|16@1+ (0.05,0) [0|3212.75] "V" Vector__XXX

BO_ 2566633726 DCDC4LD: 16 Vector__XXX
 SG_ FourTotalLowSideCharge : 96|32@1+ (100,0) [0|421108121500] "Ah" Vector__XXX
 SG_ FourTotalHiSideCharge : 64|32@1+ (100,0) [0|421108121500] "Ah" Vector__XXX
 SG_ FourTotalLowSideEnergy : 32|32@1+ (100,0) [0|421108121500] "Wh" Vector__XXX
 SG_ FourTotalHiSideEnergy : 0|32@1+ (100,0) [0|421108121500] "Wh" Vector__XXX

BO_ 2566633470 AT1IG4: 8 Vector__XXX
 SG_ NOxSnsrProtAirPress : 16|16@1+ (0.1,0) [0|6425.5] "kPa" Vector__XXX
 SG_ O2PumpingCur : 0|16@1+ (0.001,-32.127) [-32.127|32.128] "mA" Vector__XXX

BO_ 2566633214 AT1OG4: 8 Vector__XXX
 SG_ NOxSnsrProtAirPress : 16|16@1+ (0.1,0) [0|6425.5] "kPa" Vector__XXX
 SG_ O2PumpingCur : 0|16@1+ (0.001,-32.127) [-32.127|32.128] "mA" Vector__XXX

BO_ 2566632958 WSPH2: 8 Vector__XXX
 SG_ PwrEndTripHours : 32|32@1+ (1,0) [0|4211081215] "s" Vector__XXX
 SG_ FluidEndTripHours : 0|32@1+ (1,0) [0|4211081215] "s" Vector__XXX

BO_ 2566632702 WSPSN: 8 Vector__XXX
 SG_ FluidEndSerialNum : 8|8@1+ (1,0) [0|255] "" Vector__XXX
 SG_ PwrEndSerialNum : 0|8@1+ (1,0) [0|255] "" Vector__XXX

BO_ 2566632446 WSPFV: 8 Vector__XXX
 SG_ TripFluidPumped : 32|32@1+ (0.5,0) [0|2105540607.5] "l" Vector__XXX
 SG_ TotalFluidPumped : 0|32@1+ (0.5,0) [0|2105540607.5] "l" Vector__XXX

BO_ 2566632190 WSPSCS: 8 Vector__XXX
 SG_ DisPressCalSetPointStatus : 12|2@1+ (1,0) [0|3] "" Vector__XXX
 SG_ DisPressCalSetPoint : 8|4@1+ (1,0) [0|15] "" Vector__XXX
 SG_ SuctionPressCalSetPointStatus : 4|2@1+ (1,0) [0|3] "" Vector__XXX
 SG_ SuctionPressCalSetPoint : 0|4@1+ (1,0) [0|15] "" Vector__XXX

BO_ 2566631934 DCAC_AI5_LD: 8 Vector__XXX
 SG_ TotalDCInputEnergy : 32|32@1+ (100,0) [0|421108121500] "Wh" Vector__XXX
 SG_ TotalDCInputCharge : 0|32@1+ (100,0) [0|421108121500] "Ah" Vector__XXX

BO_ 2566631678 DCAC_AI5_CFG1: 13 Vector__XXX
 SG_ ACSideDefaultFreqCmdSetting : 96|8@1+ (1,0) [0|250] "Hz" Vector__XXX
 SG_ DCSideCurMinLmtSetting : 80|16@1+ (0.05,-3212.75) [-3212.75|0] "A" Vector__XXX
 SG_ DCSideVMaxLmtSetting : 64|16@1+ (0.05,0) [0|3212.75] "V" Vector__XXX
 SG_ ACSideRMSCurMaxLmtSetting : 48|16@1+ (0.03125,0) [0|2007.96875] "A" Vector__XXX
 SG_ ACSideRMSVMaxLmtSetting : 32|16@1+ (0.03125,0) [0|2007.96875] "V" Vector__XXX
 SG_ DCSideCurMaxLmtSetting : 16|16@1+ (0.05,0) [0|3212.75] "A" Vector__XXX
 SG_ DCSideVMinLmtSetting : 0|16@1+ (0.05,0) [0|3212.75] "V" Vector__XXX

BO_ 2365304830 DCAC_AI5_ACL: 8 Vector__XXX
 SG_ DefaultFreqReq : 32|8@1+ (1,0) [0|250] "Hz" Vector__XXX
 SG_ RMSCurMaxLmtReq : 16|16@1+ (0.03125,0) [0|2007.96875] "A" Vector__XXX
 SG_ RMSVMaxLmtReq : 0|16@1+ (0.03125,0) [0|2007.96875] "V" Vector__XXX

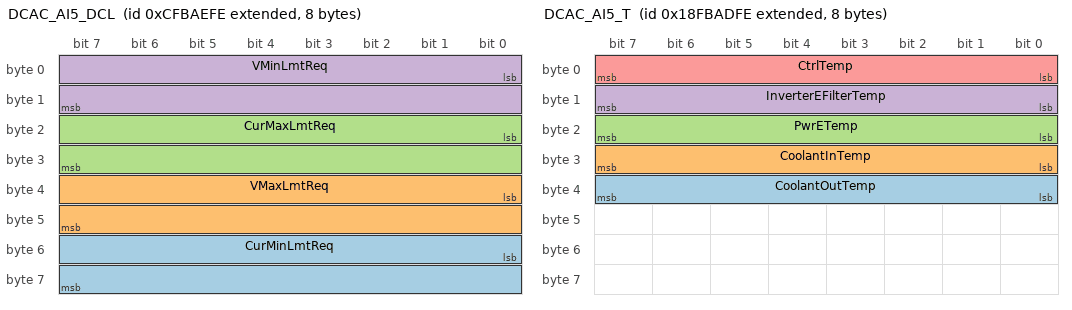
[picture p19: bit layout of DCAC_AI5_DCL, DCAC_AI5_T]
BO_ 2365304574 DCAC_AI5_DCL: 8 Vector__XXX
 SG_ CurMinLmtReq : 48|16@1+ (0.05,-3212.75) [-3212.75|0] "A" Vector__XXX
 SG_ VMaxLmtReq : 32|16@1+ (0.05,0) [0|3212.75] "V" Vector__XXX
 SG_ CurMaxLmtReq : 16|16@1+ (0.05,0) [0|3212.75] "A" Vector__XXX
 SG_ VMinLmtReq : 0|16@1+ (0.05,0) [0|3212.75] "V" Vector__XXX

BO_ 2566630910 DCAC_AI5_T: 8 Vector__XXX
 SG_ CoolantOutTemp : 32|8@1+ (1,-40) [-40|210] "°C" Vector__XXX
 SG_ CoolantInTemp : 24|8@1+ (1,-40) [-40|210] "°C" Vector__XXX
 SG_ PwrETemp : 16|8@1+ (1,-40) [-40|210] "°C" Vector__XXX
 SG_ InverterEFilterTemp : 8|8@1+ (1,-40) [-40|210] "°C" Vector__XXX
 SG_ CtrlTemp : 0|8@1+ (1,-40) [-40|210] "°C" Vector__XXX

CM_ BO_ 2364622334 "Engine Cylinder 1 Combustion Pressures
Used to transmit the combustion pressure at 4 user-defined timing locations for Engine Cylinder 1.";
CM_ SG_ 2364622334 Timing4Press "In-cylinder pressure for Cylinder #1 at user-defined timing location #4 as per SPN 9848.  Will report FB00h (64256) when engine is not running.";
CM_ SG_ 2364622334 Timing3Press "In-cylinder pressure for Cylinder #1 at user-defined timing location #3 as per SPN 9847.  Will report FB00h (64256) when engine is not running.";
CM_ SG_ 2364622334 Timing2Press "In-cylinder pressure for Cylinder #1 at user-defined timing location #2 as per SPN 9846.  Will report FB00h (64256) when engine is not running.";
CM_ SG_ 2364622334 Timing1Press "In-cylinder pressure for Cylinder #1 at user-defined timing location #1 as per SPN 9845.  Will report FB00h (64256) when engine is not running.";
CM_ BO_ 2364622078 "Stationary Inverter to Bus Sync Check Status
Contains parameters allowing a stationary inverter to sync to another bus.
These parameters are intended for stationary Generator/Engine components, not mobile applications.  See \"Motor/Generator\" PGs ...";
CM_ SG_ 2364622078 ACPhaseDiff "The phase difference between the stationary inverter and the bus voltage.  

For stationary non-vehicular applications of inverters.";
CM_ SG_ 2364622078 InSync "Indicator of whether the stationary inverter and the bus are properly synchronized for paralleling.  This indicator will be based on parameters such as Voltage Match, Frequency Match, and Phase Match.
For stationary non-vehicular applications of ...";
CM_ SG_ 2364622078 VMatch "Indicator of whether the voltage difference the stationary inverter and the bus is adequate for paralleling.
For stationary non-vehicular applications of inverters.
00b = Voltages do not match
01b = Voltages match
10b = Error
11b = Not ...";
CM_ SG_ 2364622078 FreqMatch "Indicator of whether the frequency difference between the stationary inverter and the bus is adequate for paralleling.
For stationary non-vehicular applications of inverters.
00b = Frequencies do not match
01b = Frequencies match
10b = Error
 ...";
CM_ SG_ 2364622078 PhaseMatch "Indicator of whether phase difference between the stationary inverter and the bus is adequate for paralleling.
For stationary non-vehicular applications of inverters.
00b = Phases do not match
01b = Phases match
10b = Error
11b = Not Available ...";
CM_ SG_ 2364622078 DeadBus "Indicator of whether the bus is considered dead for closing to the stationary inverter. This indicator will be based on parameters such as bus voltage and dead bus threshold values.
For stationary non-vehicular applications of inverters.
00b = Bus ...";
CM_ BO_ 2364621822 "Stationary Inverter Control
Message for the inverter control to change or report the status of the inverter system.
For stationary non-vehicular applications of inverters.
These parameters are intended for stationary Generator/Engine components, ...";
CM_ SG_ 2364621822 AuxShutdownSw "Switch signal which requests that all inverter functions stop.

For stationary non-vehicular applications of inverters.

00b = Off
01b = On
10b = Error
11b = Not available";
CM_ SG_ 2364621822 NotReadyToAutoParallelSt "This parameter indicates whether or not all systems required to operate the inverter and close to the bus are prepared to operate automatically. If systems are not ready to operate in parallel, the status parameter is reflected as the ACTIVE state.
 ...";
CM_ BO_ 2364621566 "Stationary Inverter Total AC Power
Total Power related Inverter values.
For stationary non-vehicular applications of inverters.
These parameters are intended for stationary Generator/Engine components, not mobile applications.  See ...";
CM_ SG_ 2364621566 ApparentPwr "The total apparent power delivered by the inverter.

For stationary non-vehicular applications of inverters.";
CM_ SG_ 2364621566 RealPwr "Total real power delivered by the inverter.

For stationary non-vehicular applications of inverters.";
CM_ BO_ 2364621310 "Stationary Inverter Total AC Reactive Power
Reactive Power Inverter values.
For stationary non-vehicular applications of inverters.
These parameters are intended for stationary Generator/Engine components, not mobile applications.  See ...";
CM_ SG_ 2364621310 OverallPwrFactorLagging "Lead/lag status for inverter average power factor.

For stationary non-vehicular applications of inverters.

00b = Leading
01b = Lagging
10b = Error
11b = Not Available or Not Installed";
CM_ SG_ 2364621310 OverallPwrFactor "The average power factor of the inverter.

For stationary non-vehicular applications of inverters.";
CM_ SG_ 2364621310 ReactivePwr "The total reactive power delivered by the inverter.

For stationary non-vehicular applications of inverters.";
CM_ BO_ 2364621054 "Stationary Inverter Average Basic AC Quantities
Basic AC quantities.
For stationary non-vehicular applications of inverters.
Note: Not to be used for automotive applications
These parameters are intended for stationary Generator/Engine ...";
CM_ SG_ 2364621054 ACRMSCur "Average AC RMS current measured at the inverter output.

For stationary non-vehicular applications of inverters.";
CM_ SG_ 2364621054 ACFreq "Average AC frequency measured at the inverter output.

For stationary non-vehicular applications of inverters.";
CM_ SG_ 2364621054 LineNeutralACRMSV "Average Line to Neutral AC RMS voltage measured at the inverter output.

For stationary non-vehicular applications of inverters.";
CM_ SG_ 2364621054 ACRMSV "Average Line to Line AC RMS voltage measured at the inverter output.

For stationary non-vehicular applications of inverters.";
CM_ BO_ 2557017854 "On Board Programming 1
Message announcing the availability or status of an over the air software update. If multiple targets are supported, the message will be repeated for each target. In the case that no software updates are available, one ...";
CM_ SG_ 2557017854 OBPPwrOffSoftUpdateSt "Indicates On Board Programming will occur on the next powerdown event when all interlocks indicate it is permitted.

00b - Software will not be updated at power-off
01b - Software will be updated at power-off
10b - Reserved
11b - Not Available";
CM_ SG_ 2557017854 OBPSoftUpdateDeferRem "Indicates the remaining number of times a software update can be deferred. Value is reset to maximum when the software is updated or when new software is available.";
CM_ SG_ 2557017854 Progress "Amount of programming progress completed in relation to the total expected duration of the programming event.";
CM_ SG_ 2557017854 OBPKeySwReq "Request to turn the key switch to the ignition or run position and/or prevent the ignition bus from turning off during on board programming (OBP).
00b = On board programming device is not requesting key switch on.
01b = On board programming device ...";
CM_ SG_ 2557017854 InterlockTargetNotReady "Indicates whether the target is not ready to accept on board programming (OBP).
00b = Off: Target is not inhibiting on board programming
01b = On: Target has indicated that it is currently unable to accept on board programming
10b = Error
11b = ...";
CM_ SG_ 2557017854 InterlockPwrSupplyInsufficient "Power supply (e.g. SLI battery state of charge) is not sufficient to allow initiation of on board programming (OBP).
00b = Off: Power supply is sufficient to permit on board programming
01b = On: On board programming is inhibited due to ...";
CM_ SG_ 2557017854 InterlockParkBrk "Park brake requirement is not met to allow initiation of on board programming (OBP).

00b = Off: Park brake is permitting on board programming
01b = On: On board programming is inhibited due to park brake
10b = Error
11b = Not available";
CM_ SG_ 2557017854 InterlockKeySwPos "Key switch position requirement is not met to allow initiation of on board programming (OBP).
00b = Off: Key switch position is permitting on board programming
01b = On: On board programming is inhibited due to key switch position
10b = Error
 ...";
CM_ SG_ 2557017854 InterlockEngSpd "Engine speed requirement is not met to allow initiation of on board programming (OBP).

00b = Off: Engine speed is permitting on board programming
01b = On: On board programming is inhibited due to engine speed.
10b = Error
11b = Not available";
CM_ SG_ 2557017854 InterlockOverallStatus "Indicates whether all interlocks for on board programming (OBP) have been satisfied. This parameter should be set to On whever any of the other OBP Interlocks are on. This allows a receiving device to know whether programming is permitted without ...";
CM_ SG_ 2557017854 Status "Status of a software update.
0000b = Software Up to Date: no new software is available
0001b = Available for Installation: updated software is available
0010b = In process/Installing: update has been initiated and progressing
0011b = ...";
CM_ SG_ 2557017854 TargetECUAddress "Source address of target device to be programmed, for which the message parameters apply.

When SPN 9767 (On Board Programming Status) parameter indicates no updates are available for all supported targets, this parameter may be set to 255.";
CM_ BO_ 2556952318 "Electrified Accessory Generator Coolant Fan Command 
The command message to the electrified accessory: Generator Coolant Fan.   See PGN 64382 for the corresponding status message.";
CM_ SG_ 2556952318 PercentSpdCmd "Speed command to the Generator Coolant Fan in percentage of maximum speed.
Note: Both Speed Command and Percent Speed Command cannot be used at the same time.  Always set the unused speed command to Not Available.  If both commands are set to Not ...";
CM_ SG_ 2556952318 SpdCmd "Speed command to the Generator Coolant Fan.
Note: Both Speed Command and Percent Speed Command cannot be used at the same time.  Always set the unused speed command to Not Available.  If both commands are set to Not Available, a preprogrammed ...";
CM_ SG_ 2556952318 PwrHold "Command to allow the Generator Coolant Fan to remain alive independently of the electrical enable input to the Accessory Motor.  For example, this could allow continued device operation after the keyswitch has turned off.
00b = Power Hold Disabled
 ...";
CM_ SG_ 2556952318 EnableCmd "Enable and direction command to the Generator Coolant Fan.

00b = Accessory Motor Off
01b = Accessory Motor On Normal/Default Direction
10b = Accessory Motor On Reverse Direction
11b = Don't Care/Take no action";
CM_ BO_ 2556886782 "Electrified Accessory Generator Coolant Pump Command 
The command message to the electrified accessory: Generator Coolant Pump.   See PGN 64381 for the corresponding status message.";
CM_ SG_ 2556886782 PercentSpdCmd "Speed command to the Generator Coolant Pump in percentage of maximum speed.
Note: Both Speed Command and Percent Speed Command cannot be used at the same time.  Always set the unused speed command to Not Available.
If both commands are set to Not ...";
CM_ SG_ 2556886782 SpdCmd "Speed command to the Generator Coolant Pump.
Note: Both Speed Command and Percent Speed Command cannot be used at the same time.  Always set the unused speed command to Not Available.
If both commands are set to Not Available, a preprogrammed ...";
CM_ SG_ 2556886782 PwrHold "Command to allow the Generator Coolant Pump to remain alive independently of the electrical enable input to the Accessory Motor.  For example, this could allow continued device operation after the keyswitch has turned off.
00b = Power Hold Disabled
 ...";
CM_ SG_ 2556886782 EnableCmd "Enable and direction command to the Generator Coolant Pump.

00b = Accessory Motor Off
01b = Accessory Motor On Normal/Default Direction
10b = Accessory Motor On Reverse Direction
11b = Don't Care/Take no action";
CM_ BO_ 2556821246 "Engine Cylinder Pressure Timing Configuration
The values in this PG configure the timing in crank angle degrees used to report engine cylinder pressure in ECCP1-ECCP20";
CM_ SG_ 2556821246 Four "Commanded timing location #4 for in-cylinder pressure reports in ECCP1-20. When the combustion happens after the TDC (Top Dead Center) of this cylinder, the timing is referred in terms of positive angle and if combustion happens before TDC, the ...";
CM_ SG_ 2556821246 Three "Commanded timing location #3 for in-cylinder pressure reports in ECCP1-20. When the combustion happens after the TDC (Top Dead Center) of this cylinder, the timing is referred in terms of positive angle and if combustion happens before TDC, the ...";
CM_ SG_ 2556821246 Two "Commanded timing location #2 for in-cylinder pressure reports in ECCP1-20. When the combustion happens after the TDC (Top Dead Center) of this cylinder, the timing is referred in terms of positive angle and if combustion happens before TDC, the ...";
CM_ SG_ 2556821246 One "Commanded timing location #1 for in-cylinder pressure reports in ECCP1-20.  When the combustion happens after the TDC (Top Dead Center) of this cylinder, the timing is referred in terms of positive angle and if combustion happens before TDC, the ...";
CM_ BO_ 2556755710 "Engine Cylinder Pressure Timing Feedback
The values in this PG represent the timing in crank angle degrees which will be used by the reporting ECU for cylinder pressures in ECCP1-ECCP20";
CM_ SG_ 2556755710 ConfiguredEngCylPressTiming4 "Configured timing location #4 for combustion pressure reporting in ECCP1-20.  When the combustion happens after the TDC (Top Dead Center) of this cylinder, the timing is referred in terms of positive angle and if combustion happens before TDC, the ...";
CM_ SG_ 2556755710 ConfiguredEngCylPressTiming3 "Configured timing location #3 for combustion pressure reporting in ECCP1-20. When the combustion happens after the TDC (Top Dead Center) of this cylinder, the timing is referred in terms of positive angle and if combustion happens before TDC, the ...";
CM_ SG_ 2556755710 ConfiguredEngCylPressTiming2 "Configured timing location #2 for combustion pressure reporting in ECCP1-20.  When the combustion happens after the TDC (Top Dead Center) of this cylinder, the timing is referred in terms of positive angle and if combustion happens before TDC, the ...";
CM_ SG_ 2556755710 ConfiguredEngCylPressTiming1 "Configured timing location #1 for combustion pressure reporting in ECCP1-20.  When the combustion happens after the TDC (Top Dead Center) of this cylinder, the timing is referred in terms of positive angle and if combustion happens before TDC, the ...";
CM_ BO_ 2556690174 "Engine Cylinder Combustion Configuration
The values in this PG configure settings for use in reporting engine cylinder combustion metrics";
CM_ SG_ 2556690174 MassFractionBurnedLocation2 "Commanded value to use for y% mass fraction burned when reporting Engine Cylinder Instantaneous Combustion Timing, Location 2 in ECCT1-20.";
CM_ SG_ 2556690174 MassFractionBurnedLocation1 "Commanded value to use for x% mass fraction burned when reporting Engine Cylinder Instantaneous Combustion Timing, Location 1 in ECCT1-20.";
CM_ BO_ 2556624638 "Engine Cylinder Combustion Configuration Feedback
The values in this PG report the configured settings used in reporting engine cylinder combustion metrics";
CM_ SG_ 2556624638 ConfMassFractionBurnedLocation2 "Configured value in use for y% mass fraction burned when reporting Engine Cylinder Instantaneous Combustion Timing, Location 2 in ECCT1-20.";
CM_ SG_ 2556624638 ConfMassFractionBurnedLocation1 "Configured value in use for x% mass fraction burned when reporting Engine Cylinder Instantaneous Combustion Timing, Location 1 in ECCT1-20.";
CM_ BO_ 2556559102 "Personnel Detect Interlock
Provides ability for personnel detect user interfaces (e.g. displays) to send interlock and other personnel detect related data to personnel detection devices, e.g. senders of the Personnel Detect Status PG (PGN 64374) ...";
CM_ SG_ 2556559102 SequenceCounterEcho "Indicates the sequence counter value of the Personnel Detect Status message or group acknowledged.";
CM_ SG_ 2556559102 AlarmReceiveStatus "Indicates status of receiving the personnel detect alarm status information.
000b = Alarm Status Data Not Received
001b = Alarm Status Data Received
010b = Reserved for SAE assignment
011b = Reserved for SAE assignment
100b = Reserved for SAE ...";
CM_ BO_ 2556493566 "Motor/Generator 1 Inverter Limits Request Power
Sets the electrical and mechanical power limits for the inverter being controlled.  Some examples of use would be for a hybrid or electric vehicle propulsion motor or generator.";
CM_ SG_ 2556493566 DCSidePwrMin "This requests a minimum limit for the DC Side power.
Refer to SPN 10172 [Reference Power] to convert % to kW.
Request a value of FBFh to instruct the inverter to use its default values.
For example, in a typical electric vehicle application, the ...";
CM_ SG_ 2556493566 DCSidePwrMax "This requests a maximum limit for the DC Side power.
Refer to SPN 10172 [Reference Power] to convert % to kW.
Request a value of FBFh to instruct the inverter to use its default values.
For example, in a typical electric vehicle application, the ...";
CM_ SG_ 2556493566 MechPwrMin "This requests a minimum limit for the mechanical power.
Refer to SPN 10172 [Reference Power] to convert % to kW.
Request a value of FBFh to instruct the inverter to use its default values.
For example, in a typical electric vehicle application, ...";
CM_ SG_ 2556493566 MechPwrMax "This requests a maximum limit for the mechanical power.
Refer to SPN 10172 [Reference Power] to convert % to kW.
Request a value of FBFh to instruct the inverter to use its default values.
For example, in a typical electric vehicle application, ...";
CM_ SG_ 2556493566 Counter "The message counter is used to detect situations where the transmitting ECU malfunction repeats the same frame all the time. The receiver of the information may use the counter parameter to detect this situation. The transmitting device will ...";
CM_ SG_ 2556493566 CRC "The CRC is defined as follows:
• Length: 8 bits
• Polynomial: x^8+x^5+x^3+x^2+x+1
• Initial Value: FFh
• Input Data Reflection: Not reflected
• Result Data Reflection: Not reflected
• XOR value: FFh
SAE makes no claim of the functional safety ...";
CM_ BO_ 2556428030 "Motor/Generator 1 Inverter Limits Request Mechanical
Sets the torque and speed limits for the inverter being controlled. Some examples of use would be for a hybrid or electric vehicle propulsion motor or generator.";
CM_ SG_ 2556428030 SpdMin "This is a request to the inverter to set a minimum speed limit for this device.
Refer to SPN 10171 [Reference Speed] to convert % to rpm.
Request a value of FBFh to instruct the inverter to use its default values.
One use of this message is for ...";
CM_ SG_ 2556428030 SpdMax "This is a request to the inverter to set a maximum speed limit for this device.
Refer to SPN 10171 [Reference Speed] to convert % to rpm.
Request a value of FBFh to instruct the inverter to use its default values.
One use of this message is for ...";
CM_ SG_ 2556428030 TrqMin "This requests a minimum torque the inverter should command for this device.
Refer to SPN 10170 [Reference Torque] to convert % to Nm.
Request a value of FBFh to instruct the inverter to use its default values.
For example, in a typical vehicle ...";
CM_ SG_ 2556428030 TrqMax "This requests a maximum torque the inverter should command for this device.
Refer to SPN 10170 [Reference Torque] to convert % to Nm.
Request a value of FBFh to instruct the inverter to use its default values.
For example, in a typical vehicle ...";
CM_ SG_ 2556428030 Counter "The message counter is used to detect situations where the transmitting ECU malfunction repeats the same frame all the time. The receiver of the information may use the counter parameter to detect this situation. The transmitting device will ...";
CM_ SG_ 2556428030 CRC "The CRC is defined as follows:
• Length: 8 bits
• Polynomial: x^8+x^5+x^3+x^2+x+1
• Initial Value: FFh
• Input Data Reflection: Not reflected
• Result Data Reflection: Not reflected
• XOR value: FFh
SAE makes no claim of the functional safety ...";
CM_ BO_ 2556362494 "Motor/Generator 1 Inverter Limits Request DC Side
Sets the DC Side Voltage and Current limits for the inverter being controlled.  Some examples of use would be for a hybrid or electric vehicle propulsion motor or generator.";
CM_ SG_ 2556362494 CurMin "This is a request to the inverter to set a minimum DC Side Current limit for this device instance.
Refer to SPN 10202 [Reference Current] to convert % to Amps.
Request a value of FBFh to instruct the inverter to use its default values.
While ...";
CM_ SG_ 2556362494 CurMax "This is a request to the inverter to set a maximum DC Side Current limit for this device instance.
Refer to SPN 10202 [Reference Current] to convert % to Amps.
Request a value of FBFh to instruct the inverter to use its default values.
While ...";
CM_ SG_ 2556362494 VMin "This is a request to the inverter to set a minimum DC Side Voltage limit for this device instance.
Refer to SPN 10203 [Reference Voltage] to convert % to Volts.
Request a value of FBFh to instruct the inverter to use its default values.
This ...";
CM_ SG_ 2556362494 VMax "This is a request to the inverter to set a maximum DC Side Voltage limit for this device instance.
Refer to SPN 10203 [Reference Voltage] to convert % to Volts.
Request a value of FBFh to instruct the inverter to use its default values.
This ...";
CM_ SG_ 2556362494 Counter "The message counter is used to detect situations where the transmitting ECU malfunction repeats the same frame all the time. The receiver of the information may use the counter parameter to detect this situation. The transmitting device will ...";
CM_ SG_ 2556362494 CRC "The CRC is defined as follows:
• Length: 8 bits
• Polynomial: x^8+x^5+x^3+x^2+x+1
• Initial Value: FFh
• Input Data Reflection: Not reflected
• Result Data Reflection: Not reflected
• XOR value: FFh
SAE makes no claim of the functional safety ...";
CM_ BO_ 2556296958 "Motor/Generator 2 Inverter Limits Request DC Side
Sets the DC Side Voltage and Current limits for the inverter being controlled.  Some examples of use would be for a hybrid or electric vehicle propulsion motor or generator.";
CM_ SG_ 2556296958 CurMin "This is a request to the inverter to set a minimum DC Side Current limit for this device instance.
Refer to SPN 10268 [Reference Current] to convert % to Amps.
Request a value of FBFh to instruct the inverter to use its default values.
While ...";
CM_ SG_ 2556296958 CurMax "This is a request to the inverter to set a maximum DC Side Current limit for this device instance.
Refer to SPN 10268 [Reference Current] to convert % to Amps.
Request a value of FBFh to instruct the inverter to use its default values.
While ...";
CM_ SG_ 2556296958 VMin "This is a request to the inverter to set a minimum DC Side Voltage limit for this device instance.
Refer to SPN 10269 [Reference Voltage] to convert % to Volts.
Request a value of FBFh to instruct the inverter to use its default values.
This ...";
CM_ SG_ 2556296958 VMax "This is a request to the inverter to set a maximum DC Side Voltage limit for this device instance.
Refer to SPN 10269 [Reference Voltage] to convert % to Volts.
Request a value of FBFh to instruct the inverter to use its default values.
This ...";
CM_ SG_ 2556296958 Counter "The message counter is used to detect situations where the transmitting ECU malfunction repeats the same frame all the time. The receiver of the information may use the counter parameter to detect this situation. The transmitting device will ...";
CM_ SG_ 2556296958 CRC "The CRC is defined as follows:
• Length: 8 bits
• Polynomial: x^8+x^5+x^3+x^2+x+1
• Initial Value: FFh
• Input Data Reflection: Not reflected
• Result Data Reflection: Not reflected
• XOR value: FFh
SAE makes no claim of the functional safety ...";
CM_ BO_ 2556231422 "Motor/Generator 2 Inverter Limits Request Mechanical
Sets the torque and speed limits for the inverter being controlled. Some examples of use would be for a hybrid or electric vehicle propulsion motor or generator.";
CM_ SG_ 2556231422 SpdMin "This is a request to the inverter to set a minimum speed limit for this device.
Refer to SPN 10237 [Reference Speed] to convert % to rpm.
Request a value of FBFh to instruct the inverter to use its default values.
One use of this message is for ...";
CM_ SG_ 2556231422 SpdMax "This is a request to the inverter to set a maximum speed limit for this device.
Refer to SPN 10237 [Reference Speed] to convert % to rpm.
Request a value of FBFh to instruct the inverter to use its default values.
One use of this message is for ...";
CM_ SG_ 2556231422 TrqMin "This requests a minimum torque the inverter should command for this device.
Refer to SPN 10236 [Reference Torque] to convert % to Nm.
Request a value of FBFh to instruct the inverter to use its default values.
For example, in a typical vehicle ...";
CM_ SG_ 2556231422 TrqMax "This requests a maximum torque the inverter should command for this device.
Refer to SPN 10236 [Reference Torque] to convert % to Nm.
Request a value of FBFh to instruct the inverter to use its default values.
For example, in a typical vehicle ...";
CM_ SG_ 2556231422 Counter "The message counter is used to detect situations where the transmitting ECU malfunction repeats the same frame all the time. The receiver of the information may use the counter parameter to detect this situation. The transmitting device will ...";
CM_ SG_ 2556231422 CRC "The CRC is defined as follows:
• Length: 8 bits
• Polynomial: x^8+x^5+x^3+x^2+x+1
• Initial Value: FFh
• Input Data Reflection: Not reflected
• Result Data Reflection: Not reflected
• XOR value: FFh
SAE makes no claim of the functional safety ...";
CM_ BO_ 2556165886 "Motor/Generator 2 Inverter Limits Request Power
Sets the electrical and mechanical power limits for the inverter being controlled.  Some examples of use would be for a hybrid or electric vehicle propulsion motor or generator.";
CM_ SG_ 2556165886 DCSidePwrMin "This requests a minimum limit for the DC Side power.
Refer to SPN 10238 [Reference Power] to convert % to kW.
Request a value of FBFh to instruct the inverter to use its default values.
For example, in a typical electric vehicle application, the ...";
CM_ SG_ 2556165886 DCSidePwrMax "This requests a maximum limit for the DC Side power.
Refer to SPN 10238 [Reference Power] to convert % to kW.
Request a value of FBFh to instruct the inverter to use its default values.
For example, in a typical electric vehicle application, the ...";
CM_ SG_ 2556165886 MechPwrMin "This requests a minimum limit for the mechanical power.
Refer to SPN 10238 [Reference Power] to convert % to kW.
Request a value of FBFh to instruct the inverter to use its default values.
For example, in a typical electric vehicle application, ...";
CM_ SG_ 2556165886 MechPwrMax "This requests a maximum limit for the mechanical power.
Refer to SPN 10238 [Reference Power] to convert % to kW.
Request a value of FBFh to instruct the inverter to use its default values.
For example, in a typical electric vehicle application, ...";
CM_ SG_ 2556165886 Counter "The message counter is used to detect situations where the transmitting ECU malfunction repeats the same frame all the time. The receiver of the information may use the counter parameter to detect this situation. The transmitting device will ...";
CM_ SG_ 2556165886 CRC "The CRC is defined as follows:
• Length: 8 bits
• Polynomial: x^8+x^5+x^3+x^2+x+1
• Initial Value: FFh
• Input Data Reflection: Not reflected
• Result Data Reflection: Not reflected
• XOR value: FFh
SAE makes no claim of the functional safety ...";
CM_ BO_ 2556100350 "Motor/Generator 1 Inverter Isolation Integrity Request
Requests the Inverter to perform isolation integrity related tests.";
CM_ SG_ 2556100350 HVBusLowSideResistorConnectReq "This parameter is used to request connection of the inverter High-Voltage bus low side resistor in order to perform an isolation test.  

00b = Connection not Requested
01b = Connection Requested
10b = Reserved
11b = Don’t care/take no action";
CM_ SG_ 2556100350 HVBusHiSideResistorConnectReq "This parameter is used to request connection of the inverter High-Voltage bus high side resistor in order to perform an isolation test. 

00b = Connection not Requested
01b = Connection Requested
10b = Reserved
11b = Don’t care/take no action";
CM_ SG_ 2556100350 HVBusPassiveIsolTestCmd "Command for the inverter to perform a passive electrical isolation test on the high voltage bus.
A passive isolation test uses additional circuitry (e.g. a high impedance network) to monitor the delta between the high voltage connections (e.g ...";
CM_ SG_ 2556100350 HVBusActiveIsolTestCmd "Command for the inverter to perform an active electrical isolation test on the high voltage bus.
An active isolation test might use a generated signal (e.g. an injected AC signal) and then monitor changes in the measurements of the isolated ...";
CM_ BO_ 2556034814 "Motor/Generator 2 Inverter Isolation Integrity Request
Requests the Inverter to perform isolation integrity related tests.";
CM_ SG_ 2556034814 HVBusLowSideResistorConnectReq "This parameter is used to request connection of the inverter High-Voltage bus low side resistor in order to perform an isolation test.

00b = Connection not Requested
01b = Connection Requested
10b = Reserved
11b = Don’t care/take no action";
CM_ SG_ 2556034814 HVBusHiSideResistorConnectReq "This parameter is used to request connection of the inverter High-Voltage bus high side resistor in order to perform an isolation test.

00b = Connection not Requested
01b = Connection Requested
10b = Reserved
11b = Don’t care/take no action";
CM_ SG_ 2556034814 HVBusPassiveIsolTestCmd "Command for the inverter to perform a passive electrical isolation test on the high voltage bus.
A passive isolation test uses additional circuitry (e.g. a high impedance network) to monitor the delta between the high voltage connections (e.g ...";
CM_ SG_ 2556034814 HVBusActiveIsolTestCmd "Command for the inverter to perform an active electrical isolation test on the high voltage bus.
An active isolation test might use a generated signal (e.g. an injected AC signal) and then monitor changes in the measurements of the isolated ...";
CM_ BO_ 2488860414 "Hoist Command Information
Hoist operation commands to the controller that directly controls the hoist.";
CM_ SG_ 2488860414 DetentStatus "Indicates the detent status for the hoist command used for a dump body.

00b = Not in the Detent
01b = In the Detent
10b = Error Indicator
11b = Not Available";
CM_ SG_ 2488860414 HoistCmd "Hoist operation being requested to the control that directly controls the hoist used for a dump body.  The sign of the value indicates mode of operation (raise or lower) and the magnitude of the value indicates the speed as a percentage of maximum ...";
CM_ BO_ 2354577150 "Motor/Generator 1 Inverter Control 2
Secondary control message from this instance of Inverter.  Some examples of use would be for a hybrid or electric vehicle propulsion motor or generator.";
CM_ SG_ 2354577150 PIDCtrlFeedForwardTrq "A PID controller can have a Feed-Forward Torque added to its output. This parameter defines the Feed-Forward Torque Setpoint for control applications in this inverter instance. The Setpoint is in %.
Refer to SPN 10170 [Reference Torque] to convert ...";
CM_ SG_ 2354577150 PIDCtrlNormalizedPropGain "A PID controller can be parametrized by factors Kp, Ki and Kd. This parameter defines the normalized proportional gain (Kpn) for control applications in this inverter instance. The normalization converts absolute physical ranges into normalized ...";
CM_ SG_ 2354577150 PIDCtrlNormalizedIntegralGain "A PID controller can be parametrized by factors Kp, Ki and Kd. This parameter defines the normalized integral gain (Kin) for control applications in this inverter instance. The normalization converts absolute physical ranges into normalized values, ...";
CM_ SG_ 2354577150 PIDCtrlNormalizedDiffGain "A PID controller can be parametrized by factors Kp, Ki and Kd. This parameter defines the normalized differential gain (Kdn) for control applications in this inverter instance. The normalization converts absolute physical ranges into normalized ...";
CM_ SG_ 2354577150 PIDCtrlApplicableMode "Defines the Mode that the PID Gain parameters apply for this instance of the inverter.  See SPN 10167 [Control Setpoint Mode] for a definition of modes for control purposes.
Applicable modes:
0000b = Speed Control Mode
0001b = DC Side Voltage ...";
CM_ SG_ 2354577150 Counter "The message counter is used to detect situations where the transmitting ECU malfunction repeats the same frame all the time. The receiver of the information may use the counter parameter to detect this situation. The transmitting device will ...";
CM_ SG_ 2354577150 CRC "The CRC is defined as follows:
• Length: 8 bits
• Polynomial: x^8+x^5+x^3+x^2+x+1
• Initial Value: FFh
• Input Data Reflection: Not reflected
• Result Data Reflection: Not reflected
• XOR value: FFh
SAE makes no claim of the functional safety ...";
CM_ BO_ 2354511614 "Motor/Generator 2 Inverter Control 2
Secondary control message from this instance of Inverter.  Some examples of use would be for a hybrid or electric vehicle propulsion motor or generator.";
CM_ SG_ 2354511614 PIDCtrlFeedForwardTrq "A PID controller can have a Feed-Forward Torque added to its output. This parameter defines the Feed-Forward Torque Setpoint for control applications in this inverter instance. The Setpoint is in %.
Refer to SPN 10236 [Reference Torque] to convert ...";
CM_ SG_ 2354511614 PIDCtrlNormalizedPropGain "A PID controller can be parametrized by factors Kp, Ki and Kd. This parameter defines the normalized proportional gain (Kpn) for control applications in this inverter instance. The normalization converts absolute physical ranges into normalized ...";
CM_ SG_ 2354511614 PIDCtrlNormalizedIntegralGain "A PID controller can be parametrized by factors Kp, Ki and Kd. This parameter defines the normalized integral gain (Kin) for control applications in this inverter instance. The normalization converts absolute physical ranges into normalized values, ...";
CM_ SG_ 2354511614 PIDCtrlNormalizedDiffGain "A PID controller can be parametrized by factors Kp, Ki and Kd. This parameter defines the normalized differential gain (Kdn) for control applications in this inverter instance. The normalization converts absolute physical ranges into normalized ...";
CM_ SG_ 2354511614 PIDCtrlApplicableMode "Defines the Mode that the PID Gain parameters apply for this instance of the inverter.  See SPN 10233 [Control Setpoint Mode] for a definition of modes for control purposes.
Applicable modes:
0000b = Speed Control Mode
0001b = DC Side Voltage ...";
CM_ SG_ 2354511614 Counter "The message counter is used to detect situations where the transmitting ECU malfunction repeats the same frame all the time. The receiver of the information may use the counter parameter to detect this situation. The transmitting device will ...";
CM_ SG_ 2354511614 CRC "The CRC is defined as follows:
• Length: 8 bits
• Polynomial: x^8+x^5+x^3+x^2+x+1
• Initial Value: FFh
• Input Data Reflection: Not reflected
• Result Data Reflection: Not reflected
• XOR value: FFh
SAE makes no claim of the functional safety ...";
CM_ BO_ 2354446078 "Air Suspension Control 8
Used for suspension control";
CM_ SG_ 2354446078 LiftAxle3PosCmd "Signal to command the position/load condition of lift/tag axle 3. Numbering of lift/tag axles starts at front axle.
00b = Lift axle position down / tag axle laden
01b = Lift axle position up / tag axle unladen
10b = Reserved
11b = Don't ...";
CM_ BO_ 2555707134 "Winch Information 3
Commands to a winch controller.";
CM_ SG_ 2555707134 PosReset "Command to reset or \"zero\" the Winch Motor Encoder Position (SPN 12309) and Winch Revolution Counter (SPN 12310). The Winch Lifetime Revolution Counter (SPN 12311) is not reset.
00b = Reset not requested
01b = Reset requested
10b = Reserved
11b ...";
CM_ BO_ 2351955710 "High Voltage Energy Storage Pack 6 Control 1
Control commands to be sent to High Voltage Energy Storage Pack 6.";
CM_ SG_ 2351955710 ThermalMnmgtMaintenanceReq "Request to engage Thermal Management Maintenance Mode for this High Voltage Energy Storage System Pack instance.
00b = HVESS Thermal Management Maintenance Mode is not requested
01b = HVESS Thermal Management Maintenance Mode is requested
10b = ...";
CM_ SG_ 2351955710 Ctrl1CRC "The CRC is defined as follows:
• Length: 8 bits
• Polynomial: x^8+x^5+x^3+x^2+x+1
• Initial Value: FFh
• Input Data Reflection: Not reflected
• Result Data Reflection: Not reflected
• XOR value: FFh
SAE makes no claim of the functional safety ...";
CM_ SG_ 2351955710 Ctrl1Counter "The message counter is used to detect situations where the transmitting ECU malfunction repeats the same frame all the time. The receiver of the information may use the counter parameter to detect this situation. The transmitting device will ...";
CM_ SG_ 2351955710 HVBusLowSideResistorConnectReq "This parameter is used to request connection of this HVES instance High-Voltage bus low side resistor in order to perform an isolation test.  See also SPN 11616  (HVESP6 High-Voltage Bus High Side Resistor Connect Request).
This parameter is for ...";
CM_ SG_ 2351955710 HVBusHiSideResistorConnectReq "This parameter is used to request connection of this HVES instance High-Voltage bus high side resistor in order to perform an isolation test.  See also SPN 11617  (HVESP6 High-Voltage Bus Low Side Resistor Connect Request).
This parameter is for ...";
CM_ SG_ 2351955710 OpConsent "This parameter provides an indication to this High Voltage Energy Storage Pack instance that an external device is ready for this HVES instance to proceed with normal operation.  In applications which support this parameter, the HVES instance may ...";
CM_ SG_ 2351955710 EnableInternalChargerCmd "When the HVES has an internal charger this parameter will enable it.   External chargers may use the External Energy Source Connection Demand (SPN 7890) and related SPs.
This parameter is for one of multiple packs in an HVESS.  If there is only one ...";
CM_ SG_ 2351955710 CellBalancingCmd "Command for this High Voltage Energy Storage Pack instance to perform cell balancing.
This parameter is for one of multiple packs in an HVESS.  If there is only one pack in the system, the HVESS parameters should be used. If there are multiple ...";
CM_ SG_ 2351955710 HVBusPassiveIsolTestCmd "Command for this High Voltage Energy Storage Pack instance to perform a passive electrical isolation test on the high voltage bus.
A passive isolation test uses additional circuitry (e.g. a high impedance network) to monitor the delta between the ...";
CM_ SG_ 2351955710 HVBusActiveIsolTestCmd "Command for this High Voltage Energy Storage Pack instance to perform an active electrical isolation test on the high voltage bus.
An active isolation test might use a generated signal (e.g. an injected AC signal) and then monitor changes in the ...";
CM_ SG_ 2351955710 PwrDownCmd "Command to shut down this High Voltage Energy Storage Pack instance.  A normal power-down may involve steps that take some period of time (tests, writing of data, etc.).  However, an emergency power-down should shut down the storage system as ...";
CM_ SG_ 2351955710 HVBusConnectCmd "Command to connect this High Voltage Energy Storage Pack instance to the high-voltage bus.  The emergency contactor closure request may be used in situations where one or more faults in the hybrid powertrain prevent normal operation, but the vehicle ...";
CM_ BO_ 2351890174 "High Voltage Energy Storage Pack 5 Control 1
Control commands to be sent to High Voltage Energy Storage Pack 5.";
CM_ SG_ 2351890174 ThermalMnmgtMaintenanceReq "Request to engage Thermal Management Maintenance Mode for this High Voltage Energy Storage System Pack instance.
00b = HVESS Thermal Management Maintenance Mode is not requested
01b = HVESS Thermal Management Maintenance Mode is requested
10b = ...";
CM_ SG_ 2351890174 Ctrl1CRC "The CRC is defined as follows:
• Length: 8 bits
• Polynomial: x^8+x^5+x^3+x^2+x+1
• Initial Value: FFh
• Input Data Reflection: Not reflected
• Result Data Reflection: Not reflected
• XOR value: FFh
SAE makes no claim of the functional safety ...";
CM_ SG_ 2351890174 Ctrl1Counter "The message counter is used to detect situations where the transmitting ECU malfunction repeats the same frame all the time. The receiver of the information may use the counter parameter to detect this situation. The transmitting device will ...";
CM_ SG_ 2351890174 HVBusLowSideResistorConnectReq "This parameter is used to request connection of this HVES instance High-Voltage bus low side resistor in order to perform an isolation test.  See also SPN 11500  (HVESP5 High-Voltage Bus High Side Resistor Connect Request).
This parameter is for ...";
CM_ SG_ 2351890174 HVBusHiSideResistorConnectReq "This parameter is used to request connection of this HVES instance High-Voltage bus high side resistor in order to perform an isolation test.  See also SPN 11501  (HVESP5 High-Voltage Bus Low Side Resistor Connect Request).
This parameter is for ...";
CM_ SG_ 2351890174 OpConsent "This parameter provides an indication to this High Voltage Energy Storage Pack instance that an external device is ready for this HVES instance to proceed with normal operation.  In applications which support this parameter, the HVES instance may ...";
CM_ SG_ 2351890174 EnableInternalChargerCmd "When the HVES has an internal charger this parameter will enable it.   External chargers may use the External Energy Source Connection Demand (SPN 7890) and related SPs.
This parameter is for one of multiple packs in an HVESS.  If there is only one ...";
CM_ SG_ 2351890174 CellBalancingCmd "Command for this High Voltage Energy Storage Pack instance to perform cell balancing.
This parameter is for one of multiple packs in an HVESS.  If there is only one pack in the system, the HVESS parameters should be used. If there are multiple ...";
CM_ SG_ 2351890174 HVBusPassiveIsolTestCmd "Command for this High Voltage Energy Storage Pack instance to perform a passive electrical isolation test on the high voltage bus.
A passive isolation test uses additional circuitry (e.g. a high impedance network) to monitor the delta between the ...";
CM_ SG_ 2351890174 HVBusActiveIsolTestCmd "Command for this High Voltage Energy Storage Pack instance to perform an active electrical isolation test on the high voltage bus.
An active isolation test might use a generated signal (e.g. an injected AC signal) and then monitor changes in the ...";
CM_ SG_ 2351890174 PwrDownCmd "Command to shut down this High Voltage Energy Storage Pack instance.  A normal power-down may involve steps that take some period of time (tests, writing of data, etc.).  However, an emergency power-down should shut down the storage system as ...";
CM_ SG_ 2351890174 HVBusConnectCmd "Command to connect this High Voltage Energy Storage Pack instance to the high-voltage bus.  The emergency contactor closure request may be used in situations where one or more faults in the hybrid powertrain prevent normal operation, but the vehicle ...";
CM_ BO_ 2351824638 "High Voltage Energy Storage Pack 4 Control 1
Control commands to be sent to High Voltage Energy Storage Pack 4.";
CM_ SG_ 2351824638 ThermalMnmgtMaintenanceReq "Request to engage Thermal Management Maintenance Mode for this High Voltage Energy Storage System Pack instance.
00b = HVESS Thermal Management Maintenance Mode is not requested
01b = HVESS Thermal Management Maintenance Mode is requested
10b = ...";
CM_ SG_ 2351824638 Ctrl1CRC "The CRC is defined as follows:
• Length: 8 bits
• Polynomial: x^8+x^5+x^3+x^2+x+1
• Initial Value: FFh
• Input Data Reflection: Not reflected
• Result Data Reflection: Not reflected
• XOR value: FFh
SAE makes no claim of the functional safety ...";
CM_ SG_ 2351824638 Ctrl1Counter "The message counter is used to detect situations where the transmitting ECU malfunction repeats the same frame all the time. The receiver of the information may use the counter parameter to detect this situation. The transmitting device will ...";
CM_ SG_ 2351824638 HVBusLowSideResistorConnectReq "This parameter is used to request connection of this HVES instance High-Voltage bus low side resistor in order to perform an isolation test.  See also SPN 11384  (HVESP4 High-Voltage Bus High Side Resistor Connect Request).
This parameter is for ...";
CM_ SG_ 2351824638 HVBusHiSideResistorConnectReq "This parameter is used to request connection of this HVES instance High-Voltage bus high side resistor in order to perform an isolation test.  See also SPN 11385  (HVESP4 High-Voltage Bus Low Side Resistor Connect Request).
This parameter is for ...";
CM_ SG_ 2351824638 OpConsent "This parameter provides an indication to this High Voltage Energy Storage Pack instance that an external device is ready for this HVES instance to proceed with normal operation.  In applications which support this parameter, the HVES instance may ...";
CM_ SG_ 2351824638 EnableInternalChargerCmd "When the HVES has an internal charger this parameter will enable it.   External chargers may use the External Energy Source Connection Demand (SPN 7890) and related SPs.
This parameter is for one of multiple packs in an HVESS.  If there is only one ...";
CM_ SG_ 2351824638 CellBalancingCmd "Command for this High Voltage Energy Storage Pack instance to perform cell balancing.
This parameter is for one of multiple packs in an HVESS.  If there is only one pack in the system, the HVESS parameters should be used. If there are multiple ...";
CM_ SG_ 2351824638 HVBusPassiveIsolTestCmd "Command for this High Voltage Energy Storage Pack instance to perform a passive electrical isolation test on the high voltage bus.
A passive isolation test uses additional circuitry (e.g. a high impedance network) to monitor the delta between the ...";
CM_ SG_ 2351824638 HVBusActiveIsolTestCmd "Command for this High Voltage Energy Storage Pack instance to perform an active electrical isolation test on the high voltage bus.
An active isolation test might use a generated signal (e.g. an injected AC signal) and then monitor changes in the ...";
CM_ SG_ 2351824638 PwrDownCmd "Command to shut down this High Voltage Energy Storage Pack instance.  A normal power-down may involve steps that take some period of time (tests, writing of data, etc.).  However, an emergency power-down should shut down the storage system as ...";
CM_ SG_ 2351824638 HVBusConnectCmd "Command to connect this High Voltage Energy Storage Pack instance to the high-voltage bus.  The emergency contactor closure request may be used in situations where one or more faults in the hybrid powertrain prevent normal operation, but the vehicle ...";
CM_ BO_ 2351759102 "High Voltage Energy Storage Pack 3 Control 1
Control commands to be sent to High Voltage Energy Storage Pack 3.";
CM_ SG_ 2351759102 ThermalMnmgtMaintenanceReq "Request to engage Thermal Management Maintenance Mode for this High Voltage Energy Storage System Pack instance.
00b = HVESS Thermal Management Maintenance Mode is not requested
01b = HVESS Thermal Management Maintenance Mode is requested
10b = ...";
CM_ SG_ 2351759102 Ctrl1CRC "The CRC is defined as follows:
• Length: 8 bits
• Polynomial: x^8+x^5+x^3+x^2+x+1
• Initial Value: FFh
• Input Data Reflection: Not reflected
• Result Data Reflection: Not reflected
• XOR value: FFh
SAE makes no claim of the functional safety ...";
CM_ SG_ 2351759102 Ctrl1Counter "The message counter is used to detect situations where the transmitting ECU malfunction repeats the same frame all the time. The receiver of the information may use the counter parameter to detect this situation. The transmitting device will ...";
CM_ SG_ 2351759102 HVBusLowSideResistorConnectReq "This parameter is used to request connection of this HVES instance High-Voltage bus low side resistor in order to perform an isolation test.  See also SPN 11268  (HVESP3 High-Voltage Bus High Side Resistor Connect Request).
This parameter is for ...";
CM_ SG_ 2351759102 HVBusHiSideResistorConnectReq "This parameter is used to request connection of this HVES instance High-Voltage bus high side resistor in order to perform an isolation test.  See also SPN 11269  (HVESP3 High-Voltage Bus Low Side Resistor Connect Request).
This parameter is for ...";
CM_ SG_ 2351759102 OpConsent "This parameter provides an indication to this High Voltage Energy Storage Pack instance that an external device is ready for this HVES instance to proceed with normal operation.  In applications which support this parameter, the HVES instance may ...";
CM_ SG_ 2351759102 EnableInternalChargerCmd "When the HVES has an internal charger this parameter will enable it.   External chargers may use the External Energy Source Connection Demand (SPN 7890) and related SPs.
This parameter is for one of multiple packs in an HVESS.  If there is only one ...";
CM_ SG_ 2351759102 CellBalancingCmd "Command for this High Voltage Energy Storage Pack instance to perform cell balancing.
This parameter is for one of multiple packs in an HVESS.  If there is only one pack in the system, the HVESS parameters should be used. If there are multiple ...";
CM_ SG_ 2351759102 HVBusPassiveIsolTestCmd "Command for this High Voltage Energy Storage Pack instance to perform a passive electrical isolation test on the high voltage bus.
A passive isolation test uses additional circuitry (e.g. a high impedance network) to monitor the delta between the ...";
CM_ SG_ 2351759102 HVBusActiveIsolTestCmd "Command for this High Voltage Energy Storage Pack instance to perform an active electrical isolation test on the high voltage bus.
An active isolation test might use a generated signal (e.g. an injected AC signal) and then monitor changes in the ...";
CM_ SG_ 2351759102 PwrDownCmd "Command to shut down this High Voltage Energy Storage Pack instance.  A normal power-down may involve steps that take some period of time (tests, writing of data, etc.).  However, an emergency power-down should shut down the storage system as ...";
CM_ SG_ 2351759102 HVBusConnectCmd "Command to connect this High Voltage Energy Storage Pack instance to the high-voltage bus.  The emergency contactor closure request may be used in situations where one or more faults in the hybrid powertrain prevent normal operation, but the vehicle ...";
CM_ BO_ 2351693566 "High Voltage Energy Storage Pack 2 Control 1
Control commands to be sent to High Voltage Energy Storage Pack 2.";
CM_ SG_ 2351693566 ThermalMnmgtMaintenanceReq "Request to engage Thermal Management Maintenance Mode for this High Voltage Energy Storage System Pack instance.
00b = HVESS Thermal Management Maintenance Mode is not requested
01b = HVESS Thermal Management Maintenance Mode is requested
10b = ...";
CM_ SG_ 2351693566 Ctrl1CRC "The CRC is defined as follows:
• Length: 8 bits
• Polynomial: x^8+x^5+x^3+x^2+x+1
• Initial Value: FFh
• Input Data Reflection: Not reflected
• Result Data Reflection: Not reflected
• XOR value: FFh
SAE makes no claim of the functional safety ...";
CM_ SG_ 2351693566 Ctrl1Counter "The message counter is used to detect situations where the transmitting ECU malfunction repeats the same frame all the time. The receiver of the information may use the counter parameter to detect this situation. The transmitting device will ...";
CM_ SG_ 2351693566 HVBusLowSideResistorConnectReq "This parameter is used to request connection of this HVES instance High-Voltage bus low side resistor in order to perform an isolation test.  See also SPN 11152  (HVESP2 High-Voltage Bus High Side Resistor Connect Request).
This parameter is for ...";
CM_ SG_ 2351693566 HVBusHiSideResistorConnectReq "This parameter is used to request connection of this HVES instance High-Voltage bus high side resistor in order to perform an isolation test.  See also SPN 11153  (HVESP2 High-Voltage Bus Low Side Resistor Connect Request).
This parameter is for ...";
CM_ SG_ 2351693566 OpConsent "This parameter provides an indication to this High Voltage Energy Storage Pack instance that an external device is ready for this HVES instance to proceed with normal operation.  In applications which support this parameter, the HVES instance may ...";
CM_ SG_ 2351693566 EnableInternalChargerCmd "When the HVES has an internal charger this parameter will enable it.   External chargers may use the External Energy Source Connection Demand (SPN 7890) and related SPs.
This parameter is for one of multiple packs in an HVESS.  If there is only one ...";
CM_ SG_ 2351693566 CellBalancingCmd "Command for this High Voltage Energy Storage Pack instance to perform cell balancing.
This parameter is for one of multiple packs in an HVESS.  If there is only one pack in the system, the HVESS parameters should be used. If there are multiple ...";
CM_ SG_ 2351693566 HVBusPassiveIsolTestCmd "Command for this High Voltage Energy Storage Pack instance to perform a passive electrical isolation test on the high voltage bus.
A passive isolation test uses additional circuitry (e.g. a high impedance network) to monitor the delta between the ...";
CM_ SG_ 2351693566 HVBusActiveIsolTestCmd "Command for this High Voltage Energy Storage Pack instance to perform an active electrical isolation test on the high voltage bus.
An active isolation test might use a generated signal (e.g. an injected AC signal) and then monitor changes in the ...";
CM_ SG_ 2351693566 PwrDownCmd "Command to shut down this High Voltage Energy Storage Pack instance.  A normal power-down may involve steps that take some period of time (tests, writing of data, etc.).  However, an emergency power-down should shut down the storage system as ...";
CM_ SG_ 2351693566 HVBusConnectCmd "Command to connect this High Voltage Energy Storage Pack instance to the high-voltage bus.  The emergency contactor closure request may be used in situations where one or more faults in the hybrid powertrain prevent normal operation, but the vehicle ...";
CM_ BO_ 2351628030 "High Voltage Energy Storage Pack 1 Control 1
Control commands to be sent to High Voltage Energy Storage Pack 1.";
CM_ SG_ 2351628030 ThermalMnmgtMaintenanceReq "Request to engage Thermal Management Maintenance Mode for this High Voltage Energy Storage System Pack instance.
00b = HVESS Thermal Management Maintenance Mode is not requested
01b = HVESS Thermal Management Maintenance Mode is requested
10b = ...";
CM_ SG_ 2351628030 Ctrl1CRC "The CRC is defined as follows:
• Length: 8 bits
• Polynomial: x^8+x^5+x^3+x^2+x+1
• Initial Value: FFh
• Input Data Reflection: Not reflected
• Result Data Reflection: Not reflected
• XOR value: FFh
SAE makes no claim of the functional safety ...";
CM_ SG_ 2351628030 Ctrl1Counter "The message counter is used to detect situations where the transmitting ECU malfunction repeats the same frame all the time. The receiver of the information may use the counter parameter to detect this situation. The transmitting device will ...";
CM_ SG_ 2351628030 HVBusLowSideResistorConnectReq "This parameter is used to request connection of this HVES instance High-Voltage bus low side resistor in order to perform an isolation test.  See also SPN 11036  (HVESP1 High-Voltage Bus High Side Resistor Connect Request).
This parameter is for ...";
CM_ SG_ 2351628030 HVBusHiSideResistorConnectReq "This parameter is used to request connection of this HVES instance High-Voltage bus high side resistor in order to perform an isolation test.  See also SPN 11037 (HVESP1 High-Voltage Bus Low Side Resistor Connect Request).
This parameter is for one ...";
CM_ SG_ 2351628030 OpConsent "This parameter provides an indication to this High Voltage Energy Storage Pack instance that an external device is ready for this HVES instance to proceed with normal operation.  In applications which support this parameter, the HVES instance may ...";
CM_ SG_ 2351628030 EnableInternalChargerCmd "When the HVES has an internal charger this parameter will enable it.   External chargers may use the External Energy Source Connection Demand (SPN 7890) and related SPs.
This parameter is for one of multiple packs in an HVESS.  If there is only one ...";
CM_ SG_ 2351628030 CellBalancingCmd "Command for this High Voltage Energy Storage Pack instance to perform cell balancing.
This parameter is for one of multiple packs in an HVESS.  If there is only one pack in the system, the HVESS parameters should be used. If there are multiple ...";
CM_ SG_ 2351628030 HVBusPassiveIsolTestCmd "Command for this High Voltage Energy Storage Pack instance to perform a passive electrical isolation test on the high voltage bus.
A passive isolation test uses additional circuitry (e.g. a high impedance network) to monitor the delta between the ...";
CM_ SG_ 2351628030 HVBusActiveIsolTestCmd "Command for this High Voltage Energy Storage Pack instance to perform an active electrical isolation test on the high voltage bus.
An active isolation test might use a generated signal (e.g. an injected AC signal) and then monitor changes in the ...";
CM_ SG_ 2351628030 PwrDownCmd "Command to shut down this High Voltage Energy Storage Pack instance.  A normal power-down may involve steps that take some period of time (tests, writing of data, etc.).  However, an emergency power-down should shut down the storage system as ...";
CM_ SG_ 2351628030 HVBusConnectCmd "Command to connect this High Voltage Energy Storage Pack instance to the high-voltage bus.  The emergency contactor closure request may be used in situations where one or more faults in the hybrid powertrain prevent normal operation, but the vehicle ...";
CM_ BO_ 2552889086 "Motor/Generator 2 Inverter Rate Limits Request 1
Requests the rate limits for this instance of inverter being controlled. Some examples of use would be for a hybrid or electric vehicle propulsion motor or generator.";
CM_ SG_ 2552889086 AbsTrqRateLmt "The maximum rate of change for the absolute motor torque (i.e. |d(torque)|/dt) in all control modes.
Refer to SPN 10236 [Reference Torque] to convert %/sec to Nm/sec.
Request a value of FBFh to instruct the inverter to use its default values.
 ...";
CM_ SG_ 2552889086 AbsSpdRateLmt "The maximum rate of change for the absolute motor speed (i.e. |d(speed)|/dt) in all control modes.
This limit shall solely lead to reducing the absolute torque, not increasing it nor changing the torque direction. Therefore, when limits are ...";
CM_ SG_ 2552889086 Counter "The message counter is used to detect situations where the transmitting ECU malfunction repeats the same frame all the time. The receiver of the information may use the counter parameter to detect this situation. The transmitting device will ...";
CM_ SG_ 2552889086 CRC "The CRC is defined as follows:
• Length: 8 bits
• Polynomial: x^8+x^5+x^3+x^2+x+1
• Initial Value: FFh
• Input Data Reflection: Not reflected
• Result Data Reflection: Not reflected
• XOR value: FFh
SAE makes no claim of the functional safety ...";
CM_ BO_ 2552823550 "Motor/Generator 1 Inverter Rate Limits Request 1
Requests the rate limits for this instance of inverter being controlled. Some examples of use would be for a hybrid or electric vehicle propulsion motor or generator.";
CM_ SG_ 2552823550 AbsTrqRateLmt "The maximum rate of change for the absolute motor torque (i.e. |d(torque)|/dt) in all control modes.
Refer to SPN 10170 [Reference Torque] to convert %/sec to Nm/sec.
Request a value of FBFh to instruct the inverter to use its default values.
 ...";
CM_ SG_ 2552823550 AbsSpdRateLmt "The maximum rate of change for the absolute motor speed  (i.e. |d(speed)|/dt) in all control modes.
This limit shall solely lead to reducing the absolute torque, not increasing it nor changing the torque direction. Therefore, when limits are ...";
CM_ SG_ 2552823550 Counter "The message counter is used to detect situations where the transmitting ECU malfunction repeats the same frame all the time. The receiver of the information may use the counter parameter to detect this situation. The transmitting device will ...";
CM_ SG_ 2552823550 CRC "The CRC is defined as follows:
• Length: 8 bits
• Polynomial: x^8+x^5+x^3+x^2+x+1
• Initial Value: FFh
• Input Data Reflection: Not reflected
• Result Data Reflection: Not reflected
• XOR value: FFh
SAE makes no claim of the functional safety ...";
CM_ BO_ 2351431422 "Motor/Generator 2 Inverter Control
Primary Control Message from this instance of Inverter.  Some examples of use would be for a hybrid or electric vehicle propulsion motor or generator.";
CM_ SG_ 2351431422 SetpointReq "Requests the set point for this inverter.  The type of set point requested by this parameter depends on the value of SPN 10228 [Control Setpoint Mode Request] as follows:
Passive Modes:
In any Passive Mode, a bit value of FBFFh shall be set.
 ...";
CM_ SG_ 2351431422 SetpointModeReq "Requests the modes for this instance of the inverter.  See SPN 10233 [Control Setpoint Mode] for the feedback to this request.
Passive modes:  Modes where the inverter does not actively control the motor torque, for example.
0 = Power On - the ...";
CM_ SG_ 2351431422 LimitsReqOvrdMin "The Minimum limit requested by this parameter depends on the value of SPN 10225 [Control Limits Request Override Mode].
In normal operating conditions, the inverter operating limits are based on internal settings or Limits Request parameters as ...";
CM_ SG_ 2351431422 LimitsReqOvrdMax "The Maximum limit requested by this parameter depends on the value of SPN 10225 [Control Limits Request Override Mode].
In normal operating conditions, the inverter operating limits are based on internal settings or Limits Request parameters as ...";
CM_ SG_ 2351431422 LimitsReqOvrdMode "This parameter provides a way to temporarily override limits that are being received by the inverter in other messages.  It allows a specific type of limit to be transmitted at a high rate or at the same moment as the set point for synchronization ...";
CM_ SG_ 2351431422 Counter "The message counter is used to detect situations where the transmitting ECU malfunction repeats the same frame all the time. The receiver of the information may use the counter parameter to detect this situation. The transmitting device will ...";
CM_ SG_ 2351431422 CRC "The CRC is defined as follows:
• Length: 8 bits
• Polynomial: x^8+x^5+x^3+x^2+x+1
• Initial Value: FFh
• Input Data Reflection: Not reflected
• Result Data Reflection: Not reflected
• XOR value: FFh
SAE makes no claim of the functional safety ...";
CM_ BO_ 2351365886 "Motor/Generator 1 Inverter Control
Primary Control Message from this instance of Inverter.  Some examples of use would be for a hybrid or electric vehicle propulsion motor or generator.";
CM_ SG_ 2351365886 SetpointReq "Requests the set point for this inverter.  The type of set point requested by this parameter depends on the value of SPN 10162 [Control Setpoint Mode Request] as follows:
Passive Modes:
In any Passive Mode, a bit value of FBFFh shall be set.
 ...";
CM_ SG_ 2351365886 SetpointModeReq "Requests the modes for this instance of the inverter.  See SPN 10167 [Control Setpoint Mode] for the feedback to this request.
Passive modes:  Modes where the inverter does not actively control the motor torque, for example.
0 = Power On - the ...";
CM_ SG_ 2351365886 LimitsReqOvrdMin "The Minimum limit requested by this parameter depends on the value of SPN 10159 [Control Limits Request Override Mode].
In normal operating conditions, the inverter operating limits are based on internal settings or Limits Request parameters as ...";
CM_ SG_ 2351365886 LimitsReqOvrdMax "The Maximum limit requested by this parameter depends on the value of SPN 10159 [Control Limits Request Override Mode].
In normal operating conditions, the inverter operating limits are based on internal settings or Limits Request parameters as ...";
CM_ SG_ 2351365886 LimitsReqOvrdMode "This parameter provides a way to temporarily override limits that are being received by the inverter in other messages.  It allows a specific type of limit to be transmitted at a high rate or at the same moment as the set point for synchronization ...";
CM_ SG_ 2351365886 Counter "The message counter is used to detect situations where the transmitting ECU malfunction repeats the same frame all the time. The receiver of the information may use the counter parameter to detect this situation. The transmitting device will ...";
CM_ SG_ 2351365886 CRC "The CRC is defined as follows:
• Length: 8 bits
• Polynomial: x^8+x^5+x^3+x^2+x+1
• Initial Value: FFh
• Input Data Reflection: Not reflected
• Result Data Reflection: Not reflected
• XOR value: FFh
SAE makes no claim of the functional safety ...";
CM_ BO_ 2365313534 "DC/DC Converter 1 SLI Battery Limits
Sets the SLI Battery limits for the transfer of energy between the high voltage system (i.e. high side) and the SLI battery or low voltage system (i.e. low side) using a DC/DC Converter.
One intended use of ...";
CM_ SG_ 2365313534 SLIBatTempMaxLmtReq "The maximum allowed SLI Battery Temperature requested by a separate device.";
CM_ SG_ 2365313534 SLIBatTermChargeCurMaxLmtReq "The maximum allowed SLI Battery charging current (at the battery terminals) requested by a separate device.";
CM_ SG_ 2365313534 SLIBatTermVMaxLmtReq "The maximum allowed SLI Battery Voltage (at the battery terminals) requested by a separate system device.";
CM_ BO_ 2566639870 "DC/DC Converter 1 Configuration 1
Reports the active configuration setting for a DC/DC Converter.  Settings may be defined by the manufacturer, or set through use of limit PGs (DCDC1HL, DCDC1LL, and DCDC1SBL).
One intended use of this message is ...";
CM_ SG_ 2566639870 OneLowSideVBuckDefaultSetting "Reports the converter active Low Side Voltage Buck Default Setting.  The default may be requested by a separate device (via SPN 9515).

Note: Report Not Available (FFFFh) when no default has been set.";
CM_ SG_ 2566639870 SLIBatTempMaxLmtSetting "Reports the active SLI Battery Temperature maximum limit.  The setting may be requested by a separate device (via SPN 8819) or determined by the DC/DC Controller based on operating conditions.";
CM_ SG_ 2566639870 SLIBatTermChargeCurMaxLmtSetting "Reports the active SLI Battery charging current maximum limit (at the battery terminals).  The setting may be requested by a separate device (via SPN 8818) or determined by the DC/DC Controller based on operating conditions.";
CM_ SG_ 2566639870 SLIBatTermVMaxLmtSetting "Reports the active SLI Battery Voltage maximum limit (at the battery terminals).  The setting may be requested by a separate device (via SPN 8817) or determined by the DC/DC Controller based on operating conditions.";
CM_ SG_ 2566639870 OneLowSideCurMaxLmtSetting "Reports the active maximum limit on the low side current of the DC/DC Converter.  The setting may be requested by a separate device (via SPN 8568) or determined by the DC/DC Controller based on operating conditions.";
CM_ SG_ 2566639870 OneLowSideVMaxLmtSetting "Reports the active maximum limit on the low side voltage of the DC/DC Converter.  The setting may be requested by a separate device (via SPN 8567) or determined by the DC/DC Controller based on operating conditions.";
CM_ SG_ 2566639870 OneLowSideVMinLmtSetting "Reports the active minimum limit on the low side voltage of the DC/DC Converter.  The setting may be requested by a separate device (via SPN 8566) or determined by the DC/DC Controller based on operating conditions.";
CM_ SG_ 2566639870 OneHiSideCurMaxLmtSetting "Reports the active maximum limit on the high side current of the DC/DC Converter.  The setting may be requested by a separate device (via SPN 8565) or determined by the DC/DC Controller based on operating conditions.";
CM_ SG_ 2566639870 OneHiSideVMaxLmtSetting "Reports the active maximum limit on the high side voltage of the DC/DC Converter.  The setting may be requested by a separate device (via SPN 8564) or determined by the DC/DC Controller based on operating conditions.";
CM_ SG_ 2566639870 OneHiSideVMinLmtSetting "Reports the active minimum limit on the high side voltage of the DC/DC Converter.  The setting may be requested by a separate device (via SPN 8563) or determined by the DC/DC Controller based on operating conditions.";
CM_ BO_ 2566639614 "DC/DC Converter 1 Lifetime Data
Contains data accumulated over the lifetime of a DC/DC Converter.";
CM_ SG_ 2566639614 OneTotalLowSideCharge "Indicates the total lifetime charge converted by the DC/DC  from the low side (e.g. SLI battery) during boost mode.";
CM_ SG_ 2566639614 OneTotalHiSideCharge "Indicates the total lifetime charge converted by the DC/DC from the high side (e.g. HVES) during buck mode.";
CM_ SG_ 2566639614 OneTotalLowSideEnergy "Indicates the total lifetime energy converted by the DC/DC  from the low side (e.g. SLI battery) during boost mode.";
CM_ SG_ 2566639614 OneTotalHiSideEnergy "Indicates the total lifetime energy converted by the DC/DC from the high side (e.g. HVES) during buck mode.";
CM_ BO_ 2633748222 "Configurable Receive SPNs Status
PGN 28160 and PGN 64462 are used to manage and report configurable parameters that are received by a Configurable ECU. PGN 64462 is the response to PGN 28160. PGN 64462 includes the SPs and the receive status of the ...";
CM_ SG_ 2633748222 SPNModifiedStatus "Indicates if the Configurable ECU is able to honor the request issued in PGN 28160 for the associated SP identified on SPN 8845 on the port identified in SPN 8842.
00b = SP's receive status could not be modified. Note: This state shall only be used ...";
CM_ SG_ 2633748222 SPNSA "The source address of a device from which the Configurable ECU is to receive the SP identified in SPN 8845.
0 to 253 = Source Address in which this ECU is configured to receive the Configurable Receive SP. Note: If the Configurable Receive SP can ...";
CM_ SG_ 2633748222 SPNDetailedStatus "Bit 5: Source Address Pending Status
1 - The use of the source address in SPN 8846 is pending and will take effect after the next significant trigger (e.g., power cycle).
0 - The source address in SPN 8846 is a source address in which the ...";
CM_ SG_ 2633748222 SPN "Identifies the SP for which the associated SPNs 8846, 8847, & 8848 apply.";
CM_ SG_ 2633748222 PortCmdStatus "Indicates the overall success in performing the commanded transaction in PGN 28160.
000b = Positive Acknowledgment - PGN 28160 command was processed without issue.
001b = Negative Acknowledgment - PGN 28160 command was received but one or more ...";
CM_ SG_ 2633748222 PortPendingChangesStatus "Indicates if there are any pending receive changes for the port identified in SPN 8842.
0b = No pending changes to the receive status for any supported SPs for the port identified in SPN 8842.
1b = Receive changes are pending for one or more ...";
CM_ SG_ 2633748222 Port "Identifies the ECU communications port of the responding Configurable ECU that is in context for this instance of PGN 64462. If changes are accepted by the Configurable ECU, then this is the port affected. The identification of each ECU ...";
CM_ BO_ 2566639102 "Well Stimulation Pump System Configuration Status
Communicates the threshold setting of operating parameters of a well stimulation pump used in oil and gas drilling applications.
See PGN 27904 for the command PG to set the values of the operating ...";
CM_ SG_ 2566639102 PlungerFiringOrderSetting "Well stimulation pump plunger firing order
0000b = Firing order 1-2-3
0001b = Firing order 1-5-2-3-4
0010b = Reserved
0011b = Reserved
0100b = Reserved
0101b = Reserved
0110b = Reserved
0111b = Reserved
1000b = Reserved
1001b = Reserved
 ...";
CM_ SG_ 2566639102 RodLoadHiThreshold "Rod load force at which the rod load is considered at the highest acceptable force.";
CM_ SG_ 2566639102 CrankshaftSpdHiThreshold "Configurable well stimulation pump crankshaft speed that has been considered to be the highest acceptable speed.";
CM_ SG_ 2566639102 CrankshaftSpdLowThreshold "Configurable well stimulation pump crankshaft speed that has been considered to be the lowest acceptable speed.";
CM_ SG_ 2566639102 DisPressHiThreshold "Configurable pressure at which the discharge pressure is considered at the highest acceptable pressure.";
CM_ SG_ 2566639102 SuctionPressHiThreshold "Configurable pressure at which the suction pressure is considered at the highest acceptable pressure.";
CM_ SG_ 2566639102 SuctionPressLowThreshold "Configurable pressure at which the suction pressure is considered at the lowest acceptable pressure.";
CM_ SG_ 2566639102 GearBoxOilTempHiThreshold "Configurable temperature at which the gearbox oil temperature is considered at the highest acceptable temperature.";
CM_ SG_ 2566639102 GearBoxOilTempLowThreshold "Configurable temperature at which the gearbox oil temperature is considered at the lowest acceptable temperature.";
CM_ SG_ 2566639102 GearBoxOilPressHiThreshold "Configurable pressure at which the gearbox oil pressure is considered at the highest acceptable pressure.";
CM_ SG_ 2566639102 GearBoxOilPressLowThreshold "Configurable pressure at which the gearbox oil pressure is considered at the lowest acceptable pressure.";
CM_ BO_ 2566638846 "Well Stimulation Pump Hours
Commuicates operating parameters of a well stimulation pump used in oil and gas drilling applications.";
CM_ SG_ 2566638846 VlvSeatOpHours "The hours accumulated since the last time a valve seat replacement was performed on the well stimulation pump.";
CM_ SG_ 2566638846 PackingOpHours "The hours accumulated since the last time a packing replacement was performed on the well stimulation pump.";
CM_ SG_ 2566638846 VlvOpHours "The hours accumulated since the last time a valve replacement was performed on the well stimulation pump.";
CM_ SG_ 2566638846 MaintenanceIntervalHours "The hours accumulated since the last maintenance interval on the well stimulation pump.";
CM_ BO_ 2566638590 "Engine Exhaust Particulate Control System Info
Contains information which relates to the exhaust particulate control system on the engine.";
CM_ SG_ 2566638590 DiagCount "The total occurrences of diagnostic codes for the exhaust particulate control system that have been active above a predetermined time threshold. A code that has been active less than the predetermined time threshold (for example, 20 hours) will not ...";
CM_ SG_ 2566638590 DiagTime "The total time the exhaust particulate control diagnostic codes have been active. Total time only includes the active time for codes which have been active above a predetermined time threshold. The time for a code that has been active less than the ...";
CM_ BO_ 2365311486 "DC/DC Converter 2 High Side Limits
Sets the HVES or High Voltage system limits for the transfer of energy between the high voltage system (i.e. high side) and the SLI battery or low voltage system (i.e. low side) using a DC/DC converter.
One ...";
CM_ SG_ 2365311486 TwoHiSideCurMaxLmtReq "The maximum allowed high side current requested by a separate device. Under normal conditions this requested limit would be reflected in SPN 8926.";
CM_ SG_ 2365311486 TwoHiSideVMaxLmtReq "The maximum allowed high side voltage requested by a separate device.  Under normal conditions this requested limit would be reflected in SPN 8925.";
CM_ SG_ 2365311486 TwoHiSideVMinLmtReq "The minimum allowed high side voltage requested by a separate device. Under normal conditions this requested limit would be reflected in SPN 8924.";
CM_ BO_ 2365311230 "DC/DC Converter 2 Low Side Limits
Sets the SLI or Low Voltage system limits for the transfer of energy between the HVES or high voltage system (i.e. high side) and the SLI battery or low voltage system (i.e. low side) in a DC/DC Converter.";
CM_ SG_ 2365311230 TwoLowSideCurMaxLmtReq "The maximum allowed low side current requested by a separate device.  Under normal conditions this requested limit would be reflected in SPN 8929.";
CM_ SG_ 2365311230 TwoLowSideVMaxLmtReq "The maximum allowed low side voltage requested by a separate device.  Under normal conditions this requested limit would be reflected in SPN 8928.";
CM_ SG_ 2365311230 TwoLowSideVMinLmtReq "The minimum allowed low side voltage requested by a separate device.  Under normal conditions this requested limit would be reflected in SPN 8927.";
CM_ BO_ 2365310974 "DC/DC Converter 2 Temperatures
DC/DC Converter measured temperature data.

One intended use of this message is for a conventional engine mounted alternator replacement.";
CM_ SG_ 2365310974 TwoCoolantOutTemp "Parameter indicating the temperature of the DC/DC Converter Coolant measured at the output of the converter";
CM_ SG_ 2365310974 TwoCoolantInTemp "Parameter indicating the temperature of the DC/DC Converter Coolant measured at the input of the converter";
CM_ SG_ 2365310974 TwoPwrETemp "Parameter indicating the temperature of the DC/DC Converter power electronics components (e.g, switch or heatsink).";
CM_ SG_ 2365310974 TwoConvEFilterTemp "Parameter indicating the temperature of the electronic components that make up the DC/DC Converter filter.";
CM_ SG_ 2365310974 TwoConvTemp "Parameter indicating the temperature of the DC/DC Converter (e.g, controller, circuit board, enclosure).";
CM_ BO_ 2365310718 "DC/DC Converter 2 SLI Battery Limits
Sets the SLI Battery limits for the transfer of energy between the high voltage system (i.e. high side) and the SLI battery or low voltage system (i.e. low side) using a DC/DC Converter.
One intended use of ...";
CM_ SG_ 2365310718 SLIBatTempMaxLmtReq "The maximum allowed SLI Battery Temperature requested by a separate device.";
CM_ SG_ 2365310718 SLIBatTermChargeCurMaxLmtReq "The maximum allowed SLI Battery charging current (at the battery terminals) requested by a separate device.";
CM_ SG_ 2365310718 SLIBatTermVMaxLmtReq "The maximum allowed SLI Battery Voltage (at the battery terminals) requested by a separate system device.";
CM_ BO_ 2566637054 "DC/DC Converter 2 Configuration 1
Reports the active configuration setting for a DC/DC Converter.  Settings may be defined by the manufacturer, or set through use of limit PGs (DCDC2HL, DCDC2LL, and DCDC2SBL).
One intended use of this message is ...";
CM_ SG_ 2566637054 TwoLowSideVBuckDefaultSetting "Reports the converter active Low Side Voltage Buck Default Setting.  The default may be requested by a separate device (via SPN 9516).

Note: Report Not Available (FFFFh) when no default has been set.";
CM_ SG_ 2566637054 SLIBatTempMaxLmtSetting "Reports the active SLI Battery Temperature maximum limit.  The setting may be requested by a separate device (see SPN 8935) or determined by the DC/DC Controller based on operating conditions.";
CM_ SG_ 2566637054 SLIBatTermChargeCurMaxLmtSetting "Reports the active SLI Battery charging current maximum limit (at the battery terminals).  The setting may be requested by a separate device (see SPN 8934) or determined by the DC/DC Controller based on operating conditions.";
CM_ SG_ 2566637054 SLIBatTermVMaxLmtSetting "Reports the active SLI Battery Voltage maximum limit (at the battery terminals).  The setting may be requested by a separate device (see SPN 8933) or determined by the DC/DC Controller based on operating conditions.";
CM_ SG_ 2566637054 TwoLowSideCurMaxLmtSetting "Reports the active maximum limit on the low side current of the DC/DC Converter.  The setting may be requested by a separate device (see SPN 8943) or determined by the DC/DC Controller based on operating conditions.";
CM_ SG_ 2566637054 TwoLowSideVMaxLmtSetting "Reports the active maximum limit on the low side voltage of the DC/DC Converter.  The setting may be requested by a separate device (see SPN 8942) or determined by the DC/DC Controller based on operating conditions.";
CM_ SG_ 2566637054 TwoLowSideVMinLmtSetting "Reports the active minimum limit on the low side voltage of the DC/DC Converter.  The setting may be requested by a separate device(see SPN 8941) or determined by the DC/DC Controller based on operating conditions.";
CM_ SG_ 2566637054 TwoHiSideCurMaxLmtSetting "Reports the active maximum limit on the high side current of the DC/DC Converter.  The setting may be requested by a separate device (see SPN 8946) or determined by the DC/DC Controller based on operating conditions.";
CM_ SG_ 2566637054 TwoHiSideVMaxLmtSetting "Reports the active maximum limit on the high side voltage of the DC/DC Converter.  The setting may be requested by a separate device (see SPN 8945) or determined by the DC/DC Controller based on operating conditions.";
CM_ SG_ 2566637054 TwoHiSideVMinLmtSetting "Reports the active minimum limit on the high side voltage of the DC/DC Converter.  The setting may be requested by a separate device (see SPN 8944) or determined by the DC/DC Controller based on operating conditions.";
CM_ BO_ 2566636798 "DC/DC Converter 2 Lifetime Data
Contains data accumulated over the lifetime of a DC/DC Converter.";
CM_ SG_ 2566636798 TwoTotalLowSideCharge "Indicates the total lifetime charge converted by the DC/DC  from the low side (e.g. SLI battery) during boost mode.";
CM_ SG_ 2566636798 TwoTotalHiSideCharge "Indicates the total lifetime charge converted by the DC/DC from the high side (e.g. HVES) during buck mode.";
CM_ SG_ 2566636798 TwoTotalLowSideEnergy "Indicates the total lifetime energy converted by the DC/DC  from the low side (e.g. SLI battery) during boost mode.";
CM_ SG_ 2566636798 TwoTotalHiSideEnergy "Indicates the total lifetime energy converted by the DC/DC from the high side (e.g. HVES) during buck mode.";
CM_ BO_ 2365309950 "DC/DC Converter 3 High Side Limits
Sets the HVES or High Voltage system limits for the transfer of energy between the high voltage system (i.e. high side) and the SLI battery or low voltage system (i.e. low side) using a DC/DC converter.
One ...";
CM_ SG_ 2365309950 ThreeHiSideCurMaxLmtReq "The maximum allowed high side current requested by a separate device.   Under normal conditions this requested limit would be reflected in  SPN 8981.";
CM_ SG_ 2365309950 ThreeHiSideVMaxLmtReq "The maximum allowed high side voltage requested by a separate device.   Under normal conditions this requested limit would be reflected in  SPN 8980.";
CM_ SG_ 2365309950 ThreeHiSideVMinLmtReq "The minimum allowed high side voltage requested by a separate device.   Under normal conditions this requested limit would be reflected in  SPN 8979.";
CM_ BO_ 2365309694 "DC/DC Converter 3 Low Side Limits
Sets the SLI or Low Voltage system limits for the transfer of energy between the HVES or high voltage system (i.e. high side) and the SLI battery or low voltage system (i.e. low side) in a DC/DC Converter.";
CM_ SG_ 2365309694 ThreeLowSideCurMaxLmtReq "The maximum allowed low side current requested by a separate device.   Under normal conditions this requested limit would be reflected in SPN 8984.";
CM_ SG_ 2365309694 ThreeLowSideVMaxLmtReq "The maximum allowed low side voltage requested by a separate device.   Under normal conditions this requested limit would be reflected in SPN 8983.";
CM_ SG_ 2365309694 ThreeLowSideVMinLmtReq "The minimum allowed low side voltage requested by a separate device.   Under normal conditions this requested limit would be reflected in SPN 8982.";
CM_ BO_ 2365309438 "DC/DC Converter 3 Temperatures
DC/DC Converter measured temperature data.

One intended use of this message is for a conventional engine mounted alternator replacement.";
CM_ SG_ 2365309438 ThreeCoolantOutTemp "Parameter indicating the temperature of the DC/DC Converter Coolant measured at the output of the converter";
CM_ SG_ 2365309438 ThreeCoolantInTemp "Parameter indicating the temperature of the DC/DC Converter Coolant measured at the input of the converter";
CM_ SG_ 2365309438 ThreePwrETemp "Parameter indicating the temperature of the DC/DC Converter power electronics components (e.g, switch or heatsink).";
CM_ SG_ 2365309438 ThreeConvEFilterTemp "Parameter indicating the temperature of the electronic components that make up the DC/DC Converter filter.";
CM_ SG_ 2365309438 ThreeConvTemp "Parameter indicating the temperature of the DC/DC Converter (e.g, controller, circuit board, enclosure).";
CM_ BO_ 2365309182 "DC/DC Converter 3 SLI Battery Limits
Sets the SLI Battery limits for the transfer of energy between the high voltage system (i.e. high side) and the SLI battery or low voltage system (i.e. low side) using a DC/DC Converter.
One intended use of ...";
CM_ SG_ 2365309182 SLIBatTempMaxLmtReq "The maximum allowed SLI Battery Temperature requested by a separate device.";
CM_ SG_ 2365309182 SLIBatTermChargeCurMaxLmtReq "The maximum allowed SLI Battery charging current (at the battery terminals) requested by a separate device.";
CM_ SG_ 2365309182 SLIBatTermVMaxLmtReq "The maximum allowed SLI Battery Voltage (at the battery terminals) requested by a separate system device.";
CM_ BO_ 2566635518 "DC/DC Converter 3 Configuration 1
Reports the active configuration setting for a DC/DC Converter.  Settings may be defined by the manufacturer, or set through use of limit PGs (DCDC3HL, DCDC3LL, and DCDC3SBL).
One intended use of this message is ...";
CM_ SG_ 2566635518 ThreeLowSideVBuckDefaultSetting "Reports the converter active Low Side Voltage Buck Default Setting.  The default may be requested by a separate device (via SPN 9517).

Note: Report Not Available (FFFFh) when no default has been set.";
CM_ SG_ 2566635518 SLIBatTempMaxLmtSetting "Reports the active SLI Battery Temperature maximum limit.  The setting may be requested by a separate device (see SPN 8990) or determined by the DC/DC Controller based on operating conditions.";
CM_ SG_ 2566635518 SLIBatTermChargeCurMaxLmtSetting "Reports the active SLI Battery charging current maximum limit (at the battery terminals).  The setting may be requested by a separate device (see SPN 8989) or determined by the DC/DC Controller based on operating conditions.";
CM_ SG_ 2566635518 SLIBatTermVMaxLmtSetting "Reports the active SLI Battery Voltage maximum limit (at the battery terminals).  The setting may be requested by a separate device (see SPN 8988) or determined by the DC/DC Controller based on operating conditions.";
CM_ SG_ 2566635518 ThreeLowSideCurMaxLmtSetting "Reports the active maximum limit on the low side current of the DC/DC Converter.  The setting may be requested by a separate device (see SPN 8998) or determined by the DC/DC Controller based on operating conditions.";
CM_ SG_ 2566635518 ThreeLowSideVMaxLmtSetting "Reports the active maximum limit on the low side voltage of the DC/DC Converter.  The setting may be requested by a separate device (see SPN 8997) or determined by the DC/DC Controller based on operating conditions.";
CM_ SG_ 2566635518 ThreeLowSideVMinLmtSetting "Reports the active minimum limit on the low side voltage of the DC/DC Converter.  The setting may be requested by a separate device(see SPN 8996) or determined by the DC/DC Controller based on operating conditions.";
CM_ SG_ 2566635518 ThreeHiSideCurMaxLmtSetting "Reports the active maximum limit on the high side current of the DC/DC Converter.  The setting may be requested by a separate device (see SPN 9001) or determined by the DC/DC Controller based on operating conditions.";
CM_ SG_ 2566635518 ThreeHiSideVMaxLmtSetting "Reports the active maximum limit on the high side voltage of the DC/DC Converter.  The setting may be requested by a separate device (see SPN 9000) or determined by the DC/DC Controller based on operating conditions.";
CM_ SG_ 2566635518 ThreeHiSideVMinLmtSetting "Reports the active minimum limit on the high side voltage of the DC/DC Converter.  The setting may be requested by a separate device (see SPN 8999) or determined by the DC/DC Controller based on operating conditions.";
CM_ BO_ 2566635262 "DC/DC Converter 3 Lifetime Data
Contains data accumulated over the lifetime of a DC/DC Converter.";
CM_ SG_ 2566635262 ThreeTotalLowSideCharge "Indicates the total lifetime charge converted by the DC/DC  from the low side (e.g. SLI battery) during boost mode.";
CM_ SG_ 2566635262 ThreeTotalHiSideCharge "Indicates the total lifetime charge converted by the DC/DC from the high side (e.g. HVES) during buck mode.";
CM_ SG_ 2566635262 ThreeTotalLowSideEnergy "Indicates the total lifetime energy converted by the DC/DC  from the low side (e.g. SLI battery) during boost mode.";
CM_ SG_ 2566635262 ThreeTotalHiSideEnergy "Indicates the total lifetime energy converted by the DC/DC from the high side (e.g. HVES) during buck mode.";
CM_ BO_ 2365308414 "DC/DC Converter 4 High Side Limits
Sets the HVES or High Voltage system limits for the transfer of energy between the high voltage system (i.e. high side) and the SLI battery or low voltage system (i.e. low side) using a DC/DC converter.
One ...";
CM_ SG_ 2365308414 FourHiSideCurMaxLmtReq "The maximum allowed high side current requested by a separate device.   Under normal conditions this requested limit would be reflected in SPN 9036.";
CM_ SG_ 2365308414 FourHiSideVMaxLmtReq "The maximum allowed high side voltage requested by a separate device.  Under normal conditions this requested limit would be reflected in SPN 9035.";
CM_ SG_ 2365308414 FourHiSideVMinLmtReq "The minimum allowed high side voltage requested by a separate device.   Under normal conditions this requested limit would be reflected in SPN 9034.";
CM_ BO_ 2365308158 "DC/DC Converter 4 Low Side Limits
Sets the SLI or Low Voltage system limits for the transfer of energy between the HVES or high voltage system (i.e. high side) and the SLI battery or low voltage system (i.e. low side) in a DC/DC Converter.";
CM_ SG_ 2365308158 FourLowSideCurMaxLmtReq "The maximum allowed low side current requested by a separate device.   Under normal conditions this requested limit would be reflected in SPN 9039.";
CM_ SG_ 2365308158 FourLowSideVMaxLmtReq "The maximum allowed low side voltage requested by a separate device.   Under normal conditions this requested limit would be reflected in SPN 9038.";
CM_ SG_ 2365308158 FourLowSideVMinLmtReq "The minimum allowed low side voltage requested by a separate device.  Under normal conditions this requested limit would be reflected in SPN 9037.";
CM_ BO_ 2365307902 "DC/DC Converter 4 Temperatures
DC/DC Converter measured temperature data.

One intended use of this message is for a conventional engine mounted alternator replacement.";
CM_ SG_ 2365307902 FourCoolantOutTemp "Parameter indicating the temperature of the DC/DC Converter Coolant measured at the output of the converter";
CM_ SG_ 2365307902 FourCoolantInTemp "Parameter indicating the temperature of the DC/DC Converter Coolant measured at the input of the converter";
CM_ SG_ 2365307902 FourPwrETemp "Parameter indicating the temperature of the DC/DC Converter power electronics components (e.g, switch or heatsink).";
CM_ SG_ 2365307902 FourConvEFilterTemp "Parameter indicating the temperature of the electronic components that make up the DC/DC Converter filter.";
CM_ SG_ 2365307902 FourConvTemp "Parameter indicating the temperature of the DC/DC Converter (e.g, controller, circuit board, enclosure).";
CM_ BO_ 2365307646 "DC/DC Converter 4 SLI Battery Limits
Sets the SLI Battery limits for the transfer of energy between the high voltage system (i.e. high side) and the SLI battery or low voltage system (i.e. low side) using a DC/DC Converter.
One intended use of ...";
CM_ SG_ 2365307646 SLIBatTempMaxLmtReq "The maximum allowed SLI Battery Temperature requested by a separate device.";
CM_ SG_ 2365307646 SLIBatTermChargeCurMaxLmtReq "The maximum allowed SLI Battery charging current (at the battery terminals) requested by a separate device.";
CM_ SG_ 2365307646 SLIBatTermVMaxLmtReq "The maximum allowed SLI Battery Voltage (at the battery terminals) requested by a separate system device.";
CM_ BO_ 2566633982 "DC/DC Converter 4 Configuration 1
Reports the active configuration setting for a DC/DC Converter.  Settings may be defined by the manufacturer, or set through use of limit PGs (DCDC4HL, DCDC4LL, and DCDC4SBL).
One intended use of this message is ...";
CM_ SG_ 2566633982 FourLowSideVBuckDefaultSetting "Reports the converter active Low Side Voltage Buck Default Setting.  The default may be requested by a separate device (via SPN 9518).

Note: Report Not Available (FFFFh) when no default has been set.";
CM_ SG_ 2566633982 SLIBatTempMaxLmtSetting "Reports the active SLI Battery Temperature maximum limit.  The setting may be requested by a separate device (see SPN 9045) or determined by the DC/DC Controller based on operating conditions.";
CM_ SG_ 2566633982 SLIBatTermChargeCurMaxLmtSetting "Reports the active SLI Battery charging current maximum limit (at the battery terminals).  The setting may be requested by a separate device (see SPN 9044) or determined by the DC/DC Controller based on operating conditions.";
CM_ SG_ 2566633982 SLIBatTermVMaxLmtSetting "Reports the active SLI Battery Voltage maximum limit (at the battery terminals).  The setting may be requested by a separate device (see SPN 9043) or determined by the DC/DC Controller based on operating conditions.";
CM_ SG_ 2566633982 FourLowSideCurMaxLmtSetting "Reports the active maximum limit on the low side current of the DC/DC Converter.  The setting may be requested by a separate device (see SPN 9053) or determined by the DC/DC Controller based on operating conditions.";
CM_ SG_ 2566633982 FourLowSideVMaxLmtSetting "Reports the active maximum limit on the low side voltage of the DC/DC Converter.  The setting may be requested by a separate device (see SPN 9052) or determined by the DC/DC Controller based on operating conditions.";
CM_ SG_ 2566633982 FourLowSideVMinLmtSetting "Reports the active minimum limit on the low side voltage of the DC/DC Converter.  The setting may be requested by a separate device(see SPN 9051) or determined by the DC/DC Controller based on operating conditions.";
CM_ SG_ 2566633982 FourHiSideCurMaxLmtSetting "Reports the active maximum limit on the high side current of the DC/DC Converter.  The setting may be requested by a separate device (see SPN 9056) or determined by the DC/DC Controller based on operating conditions.";
CM_ SG_ 2566633982 FourHiSideVMaxLmtSetting "Reports the active maximum limit on the high side voltage of the DC/DC Converter.  The setting may be requested by a separate device (see SPN 9055) or determined by the DC/DC Controller based on operating conditions.";
CM_ SG_ 2566633982 FourHiSideVMinLmtSetting "Reports the active minimum limit on the high side voltage of the DC/DC Converter.  The setting may be requested by a separate device (see SPN 9054) or determined by the DC/DC Controller based on operating conditions.";
CM_ BO_ 2566633726 "DC/DC Converter 4 Lifetime Data
Contains data accumulated over the lifetime of a DC/DC Converter.";
CM_ SG_ 2566633726 FourTotalLowSideCharge "Indicates the total lifetime charge converted by the DC/DC  from the low side (e.g. SLI battery) during boost mode.";
CM_ SG_ 2566633726 FourTotalHiSideCharge "Indicates the total lifetime charge converted by the DC/DC from the high side (e.g. HVES) during buck mode.";
CM_ SG_ 2566633726 FourTotalLowSideEnergy "Indicates the total lifetime energy converted by the DC/DC  from the low side (e.g. SLI battery) during boost mode.";
CM_ SG_ 2566633726 FourTotalHiSideEnergy "Indicates the total lifetime energy converted by the DC/DC from the high side (e.g. HVES) during buck mode.";
CM_ BO_ 2566633470 "Aftertreatment 1 Intake Gas 4
The purpose of this PG is to group the aftertreatment intake sensor data for bank 1.  These values include the NOx, %O2, status of the sensors with respect to the power being supplied and the heating element, errors ...";
CM_ SG_ 2566633470 NOxSnsrProtAirPress "The absolute pressure of the air supplied for the intake NOx sensor protection of aftertreatment 1.";
CM_ SG_ 2566633470 O2PumpingCur "Electrical pumping current directly measured from a Lambda sensor for the purpose of calculating an air/fuel ratio.  This sensor is located at the engine exhaust in bank 1 or furthest upstream of the intake of the aftertreatment system in exhaust ...";
CM_ BO_ 2566633214 "Aftertreatment 1 Outlet Gas 4
The purpose of this PG is to group the aftertreatment outlet sensor data for bank 1.  These values include the NOx, %O2, status of the sensors with respect to the power being supplied and the heating element, errors ...";
CM_ SG_ 2566633214 NOxSnsrProtAirPress "The absolute pressure of the air supplied for the outlet NOx sensor protection of aftertreatment 1.";
CM_ SG_ 2566633214 O2PumpingCur "Electrical pumping current directly measured from a Lambda sensor for the purpose of calculating an air/fuel ratio.  This sensor is located closest to the outlet of aftertreatment 1 system.
Negative electrical current values are possible with ...";
CM_ BO_ 2566632958 "Well Stimulation Pump Trip Hours
Communicates operating parameters of a well stimulation pump used in oil and gas drilling applications.";
CM_ SG_ 2566632958 PwrEndTripHours "The hours accumulated since the last power end replacement on the well stimulation pump (since the last reset of the trip meter).

This value will be reset by the user.";
CM_ SG_ 2566632958 FluidEndTripHours "The hours accumulated since the last fluid end replacement on the well stimulation pump (since the last reset of the trip meter).

This value will be reset by the user.";
CM_ BO_ 2566632702 "Well Stimulation Pump Serial Number
Communicates serial number information of a well stimulation pump fluid end and power end used in oil and gas drilling applications.";
CM_ SG_ 2566632702 FluidEndSerialNum "The serial number of the fluid end of a well stimulation pump.";
CM_ SG_ 2566632702 PwrEndSerialNum "The serial number of the power end of a well stimulation pump.";
CM_ BO_ 2566632446 "Well Stimulation Pump Fluid Volume
Communicates fluid information of a well stimulation pump used in oil and gas drilling applications.";
CM_ SG_ 2566632446 TripFluidPumped "Fluid pumped during all or part of a well stimulation operation.";
CM_ SG_ 2566632446 TotalFluidPumped "Accumulated amount of fluid pumped during well stimulation operation.";
CM_ BO_ 2566632190 "Well Stimulation Pump Sensor Calibration Status
Calibration setting status for the Well Stimulation Pump System.
NOTE - In response to a Request (PGN 59904), multiple instances of this message will be required to transmit data for all of the Well ...";
CM_ SG_ 2566632190 DisPressCalSetPointStatus "Indicates the state of the Calibrated Sensor.

00b = Not OK
01b = OK
10b = Error
11b = Not available";
CM_ SG_ 2566632190 DisPressCalSetPoint "Specifies the current discharge pressure whose calibration status is being reported. Multipoint calibration of the discharge pressure system is performed by increasing the pressure with up to 10 known calibration pressures. For each calibration ...";
CM_ SG_ 2566632190 SuctionPressCalSetPointStatus "Indicates the state of the Calibrated Sensor.

00b = Not OK
01b = OK
10b = Error
11b = Not available";
CM_ SG_ 2566632190 SuctionPressCalSetPoint "Specifies the current suction pressure whose calibration status is being reported. Multipoint calibration of the suction pressure system is performed by increasing the pressure with up to 10 known calibration pressures. For each calibration ...";
CM_ BO_ 2566631934 "DC/AC Accessory Inverter 5 Lifetime Data
Contains data accumulated over the lifetime of this DC/AC Accessory Inverter.";
CM_ SG_ 2566631934 TotalDCInputEnergy "Total lifetime energy converted by the DC/AC from the DC Side.";
CM_ SG_ 2566631934 TotalDCInputCharge "Total lifetime charge converted by the DC/AC from the DC Side.";
CM_ BO_ 2566631678 "DC/AC Accessory Inverter 5 Configuration 1
Reports the active configuration settings for this DC/AC Accessory Inverter.  Settings may be defined by the manufacturer, or set through use of limit PGs (DCAC_AI5_DCL and DCAC_AI5_ACL).";
CM_ SG_ 2566631678 ACSideDefaultFreqCmdSetting "Reports the active AC Side Default Frequency Command Setting of the DC/AC Accessory Inverter.  The setting may be requested by a separate device (via SPN 9527).

Note: Report Not Available (FFh) when no default has been set.";
CM_ SG_ 2566631678 DCSideCurMinLmtSetting "Reports the active minimum limit on the DC Side input current of the DC/AC Accessory Inverter.  The setting may be requested by a separate device (via SPN 9554) or determined by the DC/AC Controller based on operating conditions.";
CM_ SG_ 2566631678 DCSideVMaxLmtSetting "Reports the active maximum limit on the DC Side input voltage of the DC/AC Accessory Inverter.  The setting may be requested by a separate device (via SPN 9553) or determined by the DC/AC Controller based on operating conditions.";
CM_ SG_ 2566631678 ACSideRMSCurMaxLmtSetting "Reports the active maximum limit on the AC side output RMS line current of the DC/AC Accessory Inverter.  The setting may be requested by a separate device (via SPN 9360) or determined by the DC/AC Controller based on operating conditions.";
CM_ SG_ 2566631678 ACSideRMSVMaxLmtSetting "Reports the active maximum limit on the AC Side output line to line RMS voltage of the DC/AC Accessory Inverter.  The setting may be requested by a separate device (via SPN 9359) or determined by the DC/AC Controller based on operating conditions.";
CM_ SG_ 2566631678 DCSideCurMaxLmtSetting "Reports the active maximum limit on the DC Side input current of the DC/AC Accessory Inverter.  The setting may be requested by a separate device (via SPN 9358) or determined by the DC/AC Controller based on operating conditions.";
CM_ SG_ 2566631678 DCSideVMinLmtSetting "Reports the active minimum limit on the DC Side input voltage of the DC/AC Accessory Inverter.  The setting may be requested by a separate device (via SPN 9357) or determined by the DC/AC Controller based on operating conditions.";
CM_ BO_ 2365304830 "DC/AC Accessory Inverter 5 AC Side Limits 
Sets the AC Side system limits for the transfer of energy between the HVES or high voltage system (i.e. DC Side) and the accessory loads (i.e. AC Side) in a hybrid or electric vehicle.";
CM_ SG_ 2365304830 DefaultFreqReq "This setting may be used to set a default frequency command for when communication has been lost with the controlling device.  When set to Not Available (FFh), no default setting is provided and the system should disable its output.";
CM_ SG_ 2365304830 RMSCurMaxLmtReq "The maximum allowed AC Side output RMS line current requested by a separate device.   Under normal conditions this requested limit would be reflected in SPN 9364.";
CM_ SG_ 2365304830 RMSVMaxLmtReq "The maximum allowed AC Side line to line RMS voltage requested by a separate device.   Under normal conditions this requested limit would be reflected in SPN 9363.";
CM_ BO_ 2365304574 "DC/AC Accessory Inverter 5 DC Side Limits 
Sets the HVES or High Voltage system limits for the transfer of energy between the high voltage system (i.e. DC side) and the accessory loads (i.e. AC side) in a hybrid or electric vehicle.";
CM_ SG_ 2365304574 CurMinLmtReq "The minimum allowed DC Side input current requested by a separate device.   Under normal conditions this requested limit would be reflected in SPN 9556.";
CM_ SG_ 2365304574 VMaxLmtReq "The maximum allowed DC Side input voltage requested by a separate device.   Under normal conditions this requested limit would be reflected in SPN 9555.";
CM_ SG_ 2365304574 CurMaxLmtReq "The maximum allowed DC Side input current requested by a separate device.   Under normal conditions this requested limit would be reflected in SPN 9362.";
CM_ SG_ 2365304574 VMinLmtReq "The minimum allowed DC Side input voltage requested by a separate device.   Under normal conditions this requested limit would be reflected in SPN 9361.";
CM_ BO_ 2566630910 "DC/AC Accessory Inverter 5 Temperatures
DC/AC Accessory Inverter measured temperature data.";
CM_ SG_ 2566630910 CoolantOutTemp "Temperature of the DC/AC Accessory Inverter Coolant measured at the output of the accessory inverter.";
CM_ SG_ 2566630910 CoolantInTemp "Temperature of the DC/AC Accessory Inverter Coolant measured at the input of the accessory inverter.";
CM_ SG_ 2566630910 PwrETemp "Temperature of the DC/AC Accessory Inverter power electronics components (e.g, switch or heatsink).";
CM_ SG_ 2566630910 InverterEFilterTemp "Temperature of the electronic components that make up the DC/AC Accessory Inverter filter.";
CM_ SG_ 2566630910 CtrlTemp "Temperature of the DC/AC Accessory Inverter (e.g, controller, circuit board, enclosure).";
BA_DEF_ SG_  "GenSigInactiveValue" INT 0 0;
BA_DEF_ SG_  "SigType" ENUM  "Default","Range","RangeSigned","ASCII","Discrete","Control","ReferencePGN","DTC","StringDelimiter","StringLength","StringLengthControl","MessageCounter","MessageChecksum";
BA_DEF_ SG_  "GenSigStartValue" INT 0 2147483647;
BA_DEF_ SG_  "GenSigSendType" ENUM  "Cyclic","OnWrite","OnWriteWithRepetition","OnChange","OnChangeWithRepetition","IfActive","IfActiveWithRepetition","NoSigSendType";
BA_DEF_ SG_  "GenSigILSupport" ENUM  "No","Yes";
BA_DEF_ SG_  "SPN" INT 0 524287;
BA_DEF_ BO_  "J1939CPgSendTimeout" INT -1 3600000;
BA_DEF_ BO_  "J1939CPgTOS" INT 0 7;
BA_DEF_ BO_  "J1939PgAppearanceOnBus" ENUM  "Default","CAN_Extended","CANFD_Extended";
BA_DEF_ BO_  "FsJ1939UseCrcAndCounter" STRING ;
BA_DEF_ BO_  "TpJ1939VarDlc" ENUM  "No","Yes";
BA_DEF_ BO_  "GenMsgNrOfRepetition" INT 0 1000000;
BA_DEF_ BO_  "GenMsgCycleTimeFast" INT 0 3600000;
BA_DEF_ BO_  "GenMsgFastOnStart" INT 0 100000;
BA_DEF_ BO_  "GenMsgStartDelayTime" INT 0 100000;
BA_DEF_ BO_  "GenMsgILSupport" ENUM  "No","Yes";
BA_DEF_ BO_  "GenMsgDelayTime" INT 0 1000;
BA_DEF_ BO_  "GenMsgRequestable" INT 0 1;
BA_DEF_ BO_  "GenMsgSendType" ENUM  "cyclic","NotUsed","NotUsed","NotUsed","NotUsed","NotUsed","NotUsed","IfActive","noMsgSendType";
BA_DEF_ BO_  "VFrameFormat" ENUM  "StandardCAN","ExtendedCAN","reserved","J1939PG","reserved","reserved","reserved","reserved","reserved","reserved","reserved","reserved","reserved","reserved","StandardCAN_FD","ExtendedCAN_FD";
BA_DEF_ BO_  "SingleFrame" INT 0 1;
BA_DEF_ BO_  "GenMsgCycleTime" INT 0 3600000;
BA_DEF_ SG_  "SystemSignalLongSymbol" STRING ;
BA_DEF_DEF_  "GenSigInactiveValue" 0;
BA_DEF_DEF_  "SigType" "Default";
BA_DEF_DEF_  "GenSigStartValue" 0;
BA_DEF_DEF_  "GenSigSendType" "NoSigSendType";
BA_DEF_DEF_  "GenSigILSupport" "Yes";
BA_DEF_DEF_  "SPN" 0;
BA_DEF_DEF_  "J1939CPgSendTimeout" -1;
BA_DEF_DEF_  "J1939CPgTOS" 2;
BA_DEF_DEF_  "J1939PgAppearanceOnBus" "Default";
BA_DEF_DEF_  "FsJ1939UseCrcAndCounter" "";
BA_DEF_DEF_  "TpJ1939VarDlc" "No";
BA_DEF_DEF_  "GenMsgNrOfRepetition" 0;
BA_DEF_DEF_  "GenMsgCycleTimeFast" 0;
BA_DEF_DEF_  "GenMsgFastOnStart" 0;
BA_DEF_DEF_  "GenMsgStartDelayTime" 0;
BA_DEF_DEF_  "GenMsgILSupport" "Yes";
BA_DEF_DEF_  "GenMsgDelayTime" 0;
BA_DEF_DEF_  "GenMsgRequestable" 1;
BA_DEF_DEF_  "GenMsgSendType" "noMsgSendType";
BA_DEF_DEF_  "VFrameFormat" "J1939PG";
BA_DEF_DEF_  "SingleFrame" 1;
BA_DEF_DEF_  "GenMsgCycleTime" 0;
BA_DEF_DEF_  "SystemSignalLongSymbol" "";
BA_ "GenMsgSendType" BO_ 2364622334 0;
BA_ "GenMsgCycleTime" BO_ 2364622334 1000;
BA_ "GenMsgSendType" BO_ 2364622078 0;
BA_ "GenMsgCycleTime" BO_ 2364622078 100;
BA_ "GenMsgSendType" BO_ 2364621822 0;
BA_ "GenMsgCycleTime" BO_ 2364621822 100;
BA_ "GenMsgSendType" BO_ 2364621566 0;
BA_ "GenMsgCycleTime" BO_ 2364621566 100;
BA_ "GenMsgSendType" BO_ 2364621310 0;
BA_ "GenMsgCycleTime" BO_ 2364621310 100;
BA_ "GenMsgSendType" BO_ 2364621054 0;
BA_ "GenMsgCycleTime" BO_ 2364621054 100;
BA_ "GenMsgDelayTime" BO_ 2557017854 100;
BA_ "GenMsgSendType" BO_ 2557017854 0;
BA_ "GenMsgCycleTime" BO_ 2557017854 10000;
BA_ "GenMsgSendType" BO_ 2556952318 0;
BA_ "GenMsgCycleTime" BO_ 2556952318 1000;
BA_ "GenMsgSendType" BO_ 2556886782 0;
BA_ "GenMsgCycleTime" BO_ 2556886782 1000;
BA_ "GenMsgSendType" BO_ 2556559102 0;
BA_ "GenMsgCycleTime" BO_ 2556559102 1000;
BA_ "FsJ1939UseCrcAndCounter" BO_ 2556493566 "Bc";
BA_ "GenMsgSendType" BO_ 2556493566 0;
BA_ "GenMsgCycleTime" BO_ 2556493566 1000;
BA_ "FsJ1939UseCrcAndCounter" BO_ 2556428030 "Bc";
BA_ "GenMsgSendType" BO_ 2556428030 0;
BA_ "GenMsgCycleTime" BO_ 2556428030 1000;
BA_ "FsJ1939UseCrcAndCounter" BO_ 2556362494 "Bc";
BA_ "GenMsgSendType" BO_ 2556362494 0;
BA_ "GenMsgCycleTime" BO_ 2556362494 1000;
BA_ "FsJ1939UseCrcAndCounter" BO_ 2556296958 "Bc";
BA_ "GenMsgSendType" BO_ 2556296958 0;
BA_ "GenMsgCycleTime" BO_ 2556296958 1000;
BA_ "FsJ1939UseCrcAndCounter" BO_ 2556231422 "Bc";
BA_ "GenMsgSendType" BO_ 2556231422 0;
BA_ "GenMsgCycleTime" BO_ 2556231422 1000;
BA_ "FsJ1939UseCrcAndCounter" BO_ 2556165886 "Bc";
BA_ "GenMsgSendType" BO_ 2556165886 0;
BA_ "GenMsgCycleTime" BO_ 2556165886 1000;
BA_ "GenMsgDelayTime" BO_ 2488860414 50;
BA_ "GenMsgSendType" BO_ 2488860414 0;
BA_ "GenMsgCycleTime" BO_ 2488860414 250;
BA_ "FsJ1939UseCrcAndCounter" BO_ 2354577150 "Bc";
BA_ "GenMsgSendType" BO_ 2354577150 0;
BA_ "GenMsgCycleTime" BO_ 2354577150 100;
BA_ "FsJ1939UseCrcAndCounter" BO_ 2354511614 "Bc";
BA_ "GenMsgSendType" BO_ 2354511614 0;
BA_ "GenMsgCycleTime" BO_ 2354511614 100;
BA_ "GenMsgSendType" BO_ 2354446078 0;
BA_ "GenMsgCycleTime" BO_ 2354446078 100;
BA_ "GenMsgDelayTime" BO_ 2555707134 20;
BA_ "GenMsgSendType" BO_ 2555707134 0;
BA_ "GenMsgCycleTime" BO_ 2555707134 1000;
BA_ "FsJ1939UseCrcAndCounter" BO_ 2351955710 "Aa";
BA_ "GenMsgSendType" BO_ 2351955710 0;
BA_ "GenMsgCycleTime" BO_ 2351955710 20;
BA_ "FsJ1939UseCrcAndCounter" BO_ 2351890174 "Aa";
BA_ "GenMsgSendType" BO_ 2351890174 0;
BA_ "GenMsgCycleTime" BO_ 2351890174 20;
BA_ "FsJ1939UseCrcAndCounter" BO_ 2351824638 "Aa";
BA_ "GenMsgSendType" BO_ 2351824638 0;
BA_ "GenMsgCycleTime" BO_ 2351824638 20;
BA_ "FsJ1939UseCrcAndCounter" BO_ 2351759102 "Aa";
BA_ "GenMsgSendType" BO_ 2351759102 0;
BA_ "GenMsgCycleTime" BO_ 2351759102 20;
BA_ "FsJ1939UseCrcAndCounter" BO_ 2351693566 "Aa";
BA_ "GenMsgSendType" BO_ 2351693566 0;
BA_ "GenMsgCycleTime" BO_ 2351693566 20;
BA_ "FsJ1939UseCrcAndCounter" BO_ 2351628030 "Aa";
BA_ "GenMsgSendType" BO_ 2351628030 0;
BA_ "GenMsgCycleTime" BO_ 2351628030 20;
BA_ "FsJ1939UseCrcAndCounter" BO_ 2552889086 "Bc";
BA_ "GenMsgSendType" BO_ 2552889086 0;
BA_ "GenMsgCycleTime" BO_ 2552889086 100;
BA_ "FsJ1939UseCrcAndCounter" BO_ 2552823550 "Bc";
BA_ "GenMsgSendType" BO_ 2552823550 0;
BA_ "GenMsgCycleTime" BO_ 2552823550 100;
BA_ "FsJ1939UseCrcAndCounter" BO_ 2351431422 "Bc";
BA_ "GenMsgSendType" BO_ 2351431422 0;
BA_ "GenMsgCycleTime" BO_ 2351431422 10;
BA_ "FsJ1939UseCrcAndCounter" BO_ 2351365886 "Bc";
BA_ "GenMsgSendType" BO_ 2351365886 0;
BA_ "GenMsgCycleTime" BO_ 2351365886 10;
BA_ "GenMsgSendType" BO_ 2365313534 0;
BA_ "GenMsgCycleTime" BO_ 2365313534 1000;
BA_ "GenMsgSendType" BO_ 2566639870 0;
BA_ "GenMsgCycleTime" BO_ 2566639870 5000;
BA_ "TpJ1939VarDlc" BO_ 2633748222 1;
BA_ "GenMsgDelayTime" BO_ 2566638590 1000;
BA_ "GenMsgSendType" BO_ 2566638590 0;
BA_ "GenMsgCycleTime" BO_ 2566638590 10000;
BA_ "GenMsgSendType" BO_ 2365311486 0;
BA_ "GenMsgCycleTime" BO_ 2365311486 1000;
BA_ "GenMsgSendType" BO_ 2365311230 0;
BA_ "GenMsgCycleTime" BO_ 2365311230 1000;
BA_ "GenMsgSendType" BO_ 2365310974 0;
BA_ "GenMsgCycleTime" BO_ 2365310974 1000;
BA_ "GenMsgSendType" BO_ 2365310718 0;
BA_ "GenMsgCycleTime" BO_ 2365310718 1000;
BA_ "GenMsgSendType" BO_ 2566637054 0;
BA_ "GenMsgCycleTime" BO_ 2566637054 5000;
BA_ "GenMsgSendType" BO_ 2365309950 0;
BA_ "GenMsgCycleTime" BO_ 2365309950 1000;
BA_ "GenMsgSendType" BO_ 2365309694 0;
BA_ "GenMsgCycleTime" BO_ 2365309694 1000;
BA_ "GenMsgSendType" BO_ 2365309438 0;
BA_ "GenMsgCycleTime" BO_ 2365309438 1000;
BA_ "GenMsgSendType" BO_ 2365309182 0;
BA_ "GenMsgCycleTime" BO_ 2365309182 1000;
BA_ "GenMsgSendType" BO_ 2566635518 0;
BA_ "GenMsgCycleTime" BO_ 2566635518 5000;
BA_ "GenMsgSendType" BO_ 2365308414 0;
BA_ "GenMsgCycleTime" BO_ 2365308414 1000;
BA_ "GenMsgSendType" BO_ 2365308158 0;
BA_ "GenMsgCycleTime" BO_ 2365308158 1000;
BA_ "GenMsgSendType" BO_ 2365307902 0;
BA_ "GenMsgCycleTime" BO_ 2365307902 1000;
BA_ "GenMsgSendType" BO_ 2365307646 0;
BA_ "GenMsgCycleTime" BO_ 2365307646 1000;
BA_ "GenMsgSendType" BO_ 2566633982 0;
BA_ "GenMsgCycleTime" BO_ 2566633982 5000;
BA_ "GenMsgSendType" BO_ 2566633470 0;
BA_ "GenMsgCycleTime" BO_ 2566633470 100;
BA_ "GenMsgSendType" BO_ 2566633214 0;
BA_ "GenMsgCycleTime" BO_ 2566633214 100;
BA_ "TpJ1939VarDlc" BO_ 2566632702 1;
BA_ "GenMsgSendType" BO_ 2566631678 0;
BA_ "GenMsgCycleTime" BO_ 2566631678 5000;
BA_ "GenMsgSendType" BO_ 2365304830 0;
BA_ "GenMsgCycleTime" BO_ 2365304830 1000;
BA_ "GenMsgSendType" BO_ 2365304574 0;
BA_ "GenMsgCycleTime" BO_ 2365304574 1000;
BA_ "GenMsgSendType" BO_ 2566630910 0;
BA_ "GenMsgCycleTime" BO_ 2566630910 1000;
BA_ "SigType" SG_ 2364622334 Timing4Press 1;
BA_ "SPN" SG_ 2364622334 Timing4Press 9856;
BA_ "SigType" SG_ 2364622334 Timing3Press 1;
BA_ "SPN" SG_ 2364622334 Timing3Press 9855;
BA_ "SigType" SG_ 2364622334 Timing2Press 1;
BA_ "SPN" SG_ 2364622334 Timing2Press 9854;
BA_ "SigType" SG_ 2364622334 Timing1Press 1;
BA_ "SPN" SG_ 2364622334 Timing1Press 9853;
BA_ "SigType" SG_ 2364622078 ACPhaseDiff 1;
BA_ "SPN" SG_ 2364622078 ACPhaseDiff 9811;
BA_ "SigType" SG_ 2364622078 InSync 5;
BA_ "SPN" SG_ 2364622078 InSync 9810;
BA_ "SigType" SG_ 2364622078 VMatch 5;
BA_ "SPN" SG_ 2364622078 VMatch 9809;
BA_ "SigType" SG_ 2364622078 FreqMatch 5;
BA_ "SPN" SG_ 2364622078 FreqMatch 9808;
BA_ "SigType" SG_ 2364622078 PhaseMatch 5;
BA_ "SPN" SG_ 2364622078 PhaseMatch 9807;
BA_ "SigType" SG_ 2364622078 DeadBus 5;
BA_ "SPN" SG_ 2364622078 DeadBus 9806;
BA_ "SigType" SG_ 2364621822 AuxShutdownSw 5;
BA_ "SPN" SG_ 2364621822 AuxShutdownSw 9804;
BA_ "SigType" SG_ 2364621822 NotReadyToAutoParallelSt 5;
BA_ "SPN" SG_ 2364621822 NotReadyToAutoParallelSt 9803;
BA_ "SigType" SG_ 2364621566 ApparentPwr 1;
BA_ "SPN" SG_ 2364621566 ApparentPwr 9802;
BA_ "SigType" SG_ 2364621566 RealPwr 1;
BA_ "SPN" SG_ 2364621566 RealPwr 9801;
BA_ "SigType" SG_ 2364621310 OverallPwrFactorLagging 5;
BA_ "SPN" SG_ 2364621310 OverallPwrFactorLagging 9800;
BA_ "SigType" SG_ 2364621310 OverallPwrFactor 1;
BA_ "SPN" SG_ 2364621310 OverallPwrFactor 9799;
BA_ "SigType" SG_ 2364621310 ReactivePwr 1;
BA_ "SPN" SG_ 2364621310 ReactivePwr 9798;
BA_ "SigType" SG_ 2364621054 ACRMSCur 1;
BA_ "SPN" SG_ 2364621054 ACRMSCur 9797;
BA_ "SigType" SG_ 2364621054 ACFreq 1;
BA_ "SPN" SG_ 2364621054 ACFreq 9796;
BA_ "SigType" SG_ 2364621054 LineNeutralACRMSV 1;
BA_ "SPN" SG_ 2364621054 LineNeutralACRMSV 9795;
BA_ "SigType" SG_ 2364621054 ACRMSV 1;
BA_ "SPN" SG_ 2364621054 ACRMSV 9794;
BA_ "SigType" SG_ 2557017854 OBPPwrOffSoftUpdateSt 4;
BA_ "SPN" SG_ 2557017854 OBPPwrOffSoftUpdateSt 22934;
BA_ "SPN" SG_ 2557017854 OBPSoftUpdateDeferRem 22933;
BA_ "SigType" SG_ 2557017854 Progress 1;
BA_ "SPN" SG_ 2557017854 Progress 9774;
BA_ "SigType" SG_ 2557017854 OBPKeySwReq 5;
BA_ "SPN" SG_ 2557017854 OBPKeySwReq 9775;
BA_ "SigType" SG_ 2557017854 InterlockTargetNotReady 4;
BA_ "SPN" SG_ 2557017854 InterlockTargetNotReady 9773;
BA_ "SigType" SG_ 2557017854 InterlockPwrSupplyInsufficient 5;
BA_ "SPN" SG_ 2557017854 InterlockPwrSupplyInsufficient 9772;
BA_ "SigType" SG_ 2557017854 InterlockParkBrk 4;
BA_ "SPN" SG_ 2557017854 InterlockParkBrk 9771;
BA_ "SigType" SG_ 2557017854 InterlockKeySwPos 4;
BA_ "SPN" SG_ 2557017854 InterlockKeySwPos 9770;
BA_ "SigType" SG_ 2557017854 InterlockEngSpd 4;
BA_ "SPN" SG_ 2557017854 InterlockEngSpd 9769;
BA_ "SigType" SG_ 2557017854 InterlockOverallStatus 4;
BA_ "SPN" SG_ 2557017854 InterlockOverallStatus 9768;
BA_ "SPN" SG_ 2557017854 Status 9767;
BA_ "SPN" SG_ 2557017854 TargetECUAddress 9766;
BA_ "SigType" SG_ 2556952318 PercentSpdCmd 1;
BA_ "SPN" SG_ 2556952318 PercentSpdCmd 9819;
BA_ "SigType" SG_ 2556952318 SpdCmd 1;
BA_ "SPN" SG_ 2556952318 SpdCmd 9818;
BA_ "SigType" SG_ 2556952318 PwrHold 4;
BA_ "SPN" SG_ 2556952318 PwrHold 9817;
BA_ "SigType" SG_ 2556952318 EnableCmd 4;
BA_ "SPN" SG_ 2556952318 EnableCmd 9816;
BA_ "SigType" SG_ 2556886782 PercentSpdCmd 1;
BA_ "SPN" SG_ 2556886782 PercentSpdCmd 9832;
BA_ "SigType" SG_ 2556886782 SpdCmd 1;
BA_ "SPN" SG_ 2556886782 SpdCmd 9831;
BA_ "SigType" SG_ 2556886782 PwrHold 4;
BA_ "SPN" SG_ 2556886782 PwrHold 9830;
BA_ "SigType" SG_ 2556886782 EnableCmd 4;
BA_ "SPN" SG_ 2556886782 EnableCmd 9829;
BA_ "SigType" SG_ 2556821246 Four 1;
BA_ "SPN" SG_ 2556821246 Four 9852;
BA_ "SigType" SG_ 2556821246 Three 1;
BA_ "SPN" SG_ 2556821246 Three 9851;
BA_ "SigType" SG_ 2556821246 Two 1;
BA_ "SPN" SG_ 2556821246 Two 9850;
BA_ "SigType" SG_ 2556821246 One 1;
BA_ "SPN" SG_ 2556821246 One 9849;
BA_ "SigType" SG_ 2556755710 ConfiguredEngCylPressTiming4 1;
BA_ "SPN" SG_ 2556755710 ConfiguredEngCylPressTiming4 9848;
BA_ "SigType" SG_ 2556755710 ConfiguredEngCylPressTiming3 1;
BA_ "SPN" SG_ 2556755710 ConfiguredEngCylPressTiming3 9847;
BA_ "SigType" SG_ 2556755710 ConfiguredEngCylPressTiming2 1;
BA_ "SPN" SG_ 2556755710 ConfiguredEngCylPressTiming2 9846;
BA_ "SigType" SG_ 2556755710 ConfiguredEngCylPressTiming1 1;
BA_ "SPN" SG_ 2556755710 ConfiguredEngCylPressTiming1 9845;
BA_ "SigType" SG_ 2556690174 MassFractionBurnedLocation2 1;
BA_ "SPN" SG_ 2556690174 MassFractionBurnedLocation2 9934;
BA_ "SigType" SG_ 2556690174 MassFractionBurnedLocation1 1;
BA_ "SPN" SG_ 2556690174 MassFractionBurnedLocation1 9933;
BA_ "SigType" SG_ 2556624638 ConfMassFractionBurnedLocation2 1;
BA_ "SPN" SG_ 2556624638 ConfMassFractionBurnedLocation2 9936;
BA_ "SigType" SG_ 2556624638 ConfMassFractionBurnedLocation1 1;
BA_ "SPN" SG_ 2556624638 ConfMassFractionBurnedLocation1 9935;
BA_ "SPN" SG_ 2556559102 SequenceCounterEcho 10143;
BA_ "SPN" SG_ 2556559102 AlarmReceiveStatus 10142;
BA_ "SPN" SG_ 2556493566 DCSidePwrMin 10181;
BA_ "SPN" SG_ 2556493566 DCSidePwrMax 10180;
BA_ "SPN" SG_ 2556493566 MechPwrMin 10179;
BA_ "SPN" SG_ 2556493566 MechPwrMax 10178;
BA_ "SigType" SG_ 2556493566 Counter 11;
BA_ "SPN" SG_ 2556493566 Counter 10177;
BA_ "SigType" SG_ 2556493566 CRC 12;
BA_ "SPN" SG_ 2556493566 CRC 10176;
BA_ "SPN" SG_ 2556428030 SpdMin 10193;
BA_ "SPN" SG_ 2556428030 SpdMax 10192;
BA_ "SPN" SG_ 2556428030 TrqMin 10191;
BA_ "SPN" SG_ 2556428030 TrqMax 10190;
BA_ "SigType" SG_ 2556428030 Counter 11;
BA_ "SPN" SG_ 2556428030 Counter 10189;
BA_ "SigType" SG_ 2556428030 CRC 12;
BA_ "SPN" SG_ 2556428030 CRC 10188;
BA_ "SPN" SG_ 2556362494 CurMin 10209;
BA_ "SPN" SG_ 2556362494 CurMax 10208;
BA_ "SPN" SG_ 2556362494 VMin 10207;
BA_ "SPN" SG_ 2556362494 VMax 10206;
BA_ "SigType" SG_ 2556362494 Counter 11;
BA_ "SPN" SG_ 2556362494 Counter 10205;
BA_ "SigType" SG_ 2556362494 CRC 12;
BA_ "SPN" SG_ 2556362494 CRC 10204;
BA_ "SPN" SG_ 2556296958 CurMin 10275;
BA_ "SPN" SG_ 2556296958 CurMax 10274;
BA_ "SPN" SG_ 2556296958 VMin 10273;
BA_ "SPN" SG_ 2556296958 VMax 10272;
BA_ "SigType" SG_ 2556296958 Counter 11;
BA_ "SPN" SG_ 2556296958 Counter 10271;
BA_ "SigType" SG_ 2556296958 CRC 12;
BA_ "SPN" SG_ 2556296958 CRC 10270;
BA_ "SPN" SG_ 2556231422 SpdMin 10259;
BA_ "SPN" SG_ 2556231422 SpdMax 10258;
BA_ "SPN" SG_ 2556231422 TrqMin 10257;
BA_ "SPN" SG_ 2556231422 TrqMax 10256;
BA_ "SigType" SG_ 2556231422 Counter 11;
BA_ "SPN" SG_ 2556231422 Counter 10255;
BA_ "SigType" SG_ 2556231422 CRC 12;
BA_ "SPN" SG_ 2556231422 CRC 10254;
BA_ "SPN" SG_ 2556165886 DCSidePwrMin 10247;
BA_ "SPN" SG_ 2556165886 DCSidePwrMax 10246;
BA_ "SPN" SG_ 2556165886 MechPwrMin 10245;
BA_ "SPN" SG_ 2556165886 MechPwrMax 10244;
BA_ "SigType" SG_ 2556165886 Counter 11;
BA_ "SPN" SG_ 2556165886 Counter 10243;
BA_ "SigType" SG_ 2556165886 CRC 12;
BA_ "SPN" SG_ 2556165886 CRC 10242;
BA_ "SigType" SG_ 2556100350 HVBusLowSideResistorConnectReq 5;
BA_ "SPN" SG_ 2556100350 HVBusLowSideResistorConnectReq 10771;
BA_ "SigType" SG_ 2556100350 HVBusHiSideResistorConnectReq 5;
BA_ "SPN" SG_ 2556100350 HVBusHiSideResistorConnectReq 10770;
BA_ "SigType" SG_ 2556100350 HVBusPassiveIsolTestCmd 5;
BA_ "SPN" SG_ 2556100350 HVBusPassiveIsolTestCmd 10769;
BA_ "SigType" SG_ 2556100350 HVBusActiveIsolTestCmd 5;
BA_ "SPN" SG_ 2556100350 HVBusActiveIsolTestCmd 10768;
BA_ "SigType" SG_ 2556034814 HVBusLowSideResistorConnectReq 5;
BA_ "SPN" SG_ 2556034814 HVBusLowSideResistorConnectReq 10809;
BA_ "SigType" SG_ 2556034814 HVBusHiSideResistorConnectReq 5;
BA_ "SPN" SG_ 2556034814 HVBusHiSideResistorConnectReq 10808;
BA_ "SigType" SG_ 2556034814 HVBusPassiveIsolTestCmd 4;
BA_ "SPN" SG_ 2556034814 HVBusPassiveIsolTestCmd 10807;
BA_ "SigType" SG_ 2556034814 HVBusActiveIsolTestCmd 4;
BA_ "SPN" SG_ 2556034814 HVBusActiveIsolTestCmd 10806;
BA_ "SigType" SG_ 2488860414 DetentStatus 5;
BA_ "SPN" SG_ 2488860414 DetentStatus 11730;
BA_ "SigType" SG_ 2488860414 HoistCmd 1;
BA_ "GenSigStartValue" SG_ 2488860414 HoistCmd 10000;
BA_ "SPN" SG_ 2488860414 HoistCmd 11729;
BA_ "SPN" SG_ 2354577150 PIDCtrlFeedForwardTrq 12294;
BA_ "SPN" SG_ 2354577150 PIDCtrlNormalizedPropGain 11763;
BA_ "SigType" SG_ 2354577150 PIDCtrlNormalizedIntegralGain 1;
BA_ "SPN" SG_ 2354577150 PIDCtrlNormalizedIntegralGain 11762;
BA_ "SigType" SG_ 2354577150 PIDCtrlNormalizedDiffGain 1;
BA_ "SPN" SG_ 2354577150 PIDCtrlNormalizedDiffGain 11761;
BA_ "SPN" SG_ 2354577150 PIDCtrlApplicableMode 11760;
BA_ "SigType" SG_ 2354577150 Counter 11;
BA_ "SPN" SG_ 2354577150 Counter 11759;
BA_ "SigType" SG_ 2354577150 CRC 12;
BA_ "SPN" SG_ 2354577150 CRC 11758;
BA_ "SPN" SG_ 2354511614 PIDCtrlFeedForwardTrq 12295;
BA_ "SPN" SG_ 2354511614 PIDCtrlNormalizedPropGain 11769;
BA_ "SigType" SG_ 2354511614 PIDCtrlNormalizedIntegralGain 1;
BA_ "SPN" SG_ 2354511614 PIDCtrlNormalizedIntegralGain 11768;
BA_ "SigType" SG_ 2354511614 PIDCtrlNormalizedDiffGain 1;
BA_ "SPN" SG_ 2354511614 PIDCtrlNormalizedDiffGain 11767;
BA_ "SPN" SG_ 2354511614 PIDCtrlApplicableMode 11766;
BA_ "SigType" SG_ 2354511614 Counter 11;
BA_ "SPN" SG_ 2354511614 Counter 11765;
BA_ "SigType" SG_ 2354511614 CRC 12;
BA_ "SPN" SG_ 2354511614 CRC 11764;
BA_ "SigType" SG_ 2354446078 LiftAxle3PosCmd 5;
BA_ "SPN" SG_ 2354446078 LiftAxle3PosCmd 12300;
BA_ "SigType" SG_ 2555707134 PosReset 5;
BA_ "SPN" SG_ 2555707134 PosReset 12312;
BA_ "SigType" SG_ 2351955710 ThermalMnmgtMaintenanceReq 5;
BA_ "SPN" SG_ 2351955710 ThermalMnmgtMaintenanceReq 20884;
BA_ "SigType" SG_ 2351955710 Ctrl1CRC 12;
BA_ "SPN" SG_ 2351955710 Ctrl1CRC 13040;
BA_ "SigType" SG_ 2351955710 Ctrl1Counter 11;
BA_ "SPN" SG_ 2351955710 Ctrl1Counter 13039;
BA_ "SigType" SG_ 2351955710 HVBusLowSideResistorConnectReq 5;
BA_ "SPN" SG_ 2351955710 HVBusLowSideResistorConnectReq 11617;
BA_ "SigType" SG_ 2351955710 HVBusHiSideResistorConnectReq 5;
BA_ "SPN" SG_ 2351955710 HVBusHiSideResistorConnectReq 11616;
BA_ "SigType" SG_ 2351955710 OpConsent 4;
BA_ "SPN" SG_ 2351955710 OpConsent 11615;
BA_ "SigType" SG_ 2351955710 EnableInternalChargerCmd 5;
BA_ "SPN" SG_ 2351955710 EnableInternalChargerCmd 11614;
BA_ "SigType" SG_ 2351955710 CellBalancingCmd 5;
BA_ "SPN" SG_ 2351955710 CellBalancingCmd 11613;
BA_ "SigType" SG_ 2351955710 HVBusPassiveIsolTestCmd 5;
BA_ "SPN" SG_ 2351955710 HVBusPassiveIsolTestCmd 11612;
BA_ "SigType" SG_ 2351955710 HVBusActiveIsolTestCmd 5;
BA_ "SPN" SG_ 2351955710 HVBusActiveIsolTestCmd 11611;
BA_ "SigType" SG_ 2351955710 PwrDownCmd 5;
BA_ "SPN" SG_ 2351955710 PwrDownCmd 11610;
BA_ "SigType" SG_ 2351955710 HVBusConnectCmd 5;
BA_ "SPN" SG_ 2351955710 HVBusConnectCmd 11609;
BA_ "SigType" SG_ 2351890174 ThermalMnmgtMaintenanceReq 5;
BA_ "SPN" SG_ 2351890174 ThermalMnmgtMaintenanceReq 20883;
BA_ "SigType" SG_ 2351890174 Ctrl1CRC 12;
BA_ "SPN" SG_ 2351890174 Ctrl1CRC 13038;
BA_ "SigType" SG_ 2351890174 Ctrl1Counter 11;
BA_ "SPN" SG_ 2351890174 Ctrl1Counter 13037;
BA_ "SigType" SG_ 2351890174 HVBusLowSideResistorConnectReq 5;
BA_ "SPN" SG_ 2351890174 HVBusLowSideResistorConnectReq 11501;
BA_ "SigType" SG_ 2351890174 HVBusHiSideResistorConnectReq 5;
BA_ "SPN" SG_ 2351890174 HVBusHiSideResistorConnectReq 11500;
BA_ "SigType" SG_ 2351890174 OpConsent 4;
BA_ "SPN" SG_ 2351890174 OpConsent 11499;
BA_ "SigType" SG_ 2351890174 EnableInternalChargerCmd 5;
BA_ "SPN" SG_ 2351890174 EnableInternalChargerCmd 11498;
BA_ "SigType" SG_ 2351890174 CellBalancingCmd 5;
BA_ "SPN" SG_ 2351890174 CellBalancingCmd 11497;
BA_ "SigType" SG_ 2351890174 HVBusPassiveIsolTestCmd 5;
BA_ "SPN" SG_ 2351890174 HVBusPassiveIsolTestCmd 11496;
BA_ "SigType" SG_ 2351890174 HVBusActiveIsolTestCmd 5;
BA_ "SPN" SG_ 2351890174 HVBusActiveIsolTestCmd 11495;
BA_ "SigType" SG_ 2351890174 PwrDownCmd 5;
BA_ "SPN" SG_ 2351890174 PwrDownCmd 11494;
BA_ "SigType" SG_ 2351890174 HVBusConnectCmd 5;
BA_ "SPN" SG_ 2351890174 HVBusConnectCmd 11493;
BA_ "SigType" SG_ 2351824638 ThermalMnmgtMaintenanceReq 5;
BA_ "SPN" SG_ 2351824638 ThermalMnmgtMaintenanceReq 20882;
BA_ "SigType" SG_ 2351824638 Ctrl1CRC 12;
BA_ "SPN" SG_ 2351824638 Ctrl1CRC 13036;
BA_ "SigType" SG_ 2351824638 Ctrl1Counter 11;
BA_ "SPN" SG_ 2351824638 Ctrl1Counter 13035;
BA_ "SigType" SG_ 2351824638 HVBusLowSideResistorConnectReq 5;
BA_ "SPN" SG_ 2351824638 HVBusLowSideResistorConnectReq 11385;
BA_ "SigType" SG_ 2351824638 HVBusHiSideResistorConnectReq 5;
BA_ "SPN" SG_ 2351824638 HVBusHiSideResistorConnectReq 11384;
BA_ "SigType" SG_ 2351824638 OpConsent 4;
BA_ "SPN" SG_ 2351824638 OpConsent 11383;
BA_ "SigType" SG_ 2351824638 EnableInternalChargerCmd 5;
BA_ "SPN" SG_ 2351824638 EnableInternalChargerCmd 11382;
BA_ "SigType" SG_ 2351824638 CellBalancingCmd 5;
BA_ "SPN" SG_ 2351824638 CellBalancingCmd 11381;
BA_ "SigType" SG_ 2351824638 HVBusPassiveIsolTestCmd 5;
BA_ "SPN" SG_ 2351824638 HVBusPassiveIsolTestCmd 11380;
BA_ "SigType" SG_ 2351824638 HVBusActiveIsolTestCmd 5;
BA_ "SPN" SG_ 2351824638 HVBusActiveIsolTestCmd 11379;
BA_ "SigType" SG_ 2351824638 PwrDownCmd 5;
BA_ "SPN" SG_ 2351824638 PwrDownCmd 11378;
BA_ "SigType" SG_ 2351824638 HVBusConnectCmd 5;
BA_ "SPN" SG_ 2351824638 HVBusConnectCmd 11377;
BA_ "SigType" SG_ 2351759102 ThermalMnmgtMaintenanceReq 5;
BA_ "SPN" SG_ 2351759102 ThermalMnmgtMaintenanceReq 20881;
BA_ "SigType" SG_ 2351759102 Ctrl1CRC 12;
BA_ "SPN" SG_ 2351759102 Ctrl1CRC 13034;
BA_ "SigType" SG_ 2351759102 Ctrl1Counter 11;
BA_ "SPN" SG_ 2351759102 Ctrl1Counter 13033;
BA_ "SigType" SG_ 2351759102 HVBusLowSideResistorConnectReq 5;
BA_ "SPN" SG_ 2351759102 HVBusLowSideResistorConnectReq 11269;
BA_ "SigType" SG_ 2351759102 HVBusHiSideResistorConnectReq 5;
BA_ "SPN" SG_ 2351759102 HVBusHiSideResistorConnectReq 11268;
BA_ "SigType" SG_ 2351759102 OpConsent 4;
BA_ "SPN" SG_ 2351759102 OpConsent 11267;
BA_ "SigType" SG_ 2351759102 EnableInternalChargerCmd 5;
BA_ "SPN" SG_ 2351759102 EnableInternalChargerCmd 11266;
BA_ "SigType" SG_ 2351759102 CellBalancingCmd 5;
BA_ "SPN" SG_ 2351759102 CellBalancingCmd 11265;
BA_ "SigType" SG_ 2351759102 HVBusPassiveIsolTestCmd 5;
BA_ "SPN" SG_ 2351759102 HVBusPassiveIsolTestCmd 11264;
BA_ "SigType" SG_ 2351759102 HVBusActiveIsolTestCmd 5;
BA_ "SPN" SG_ 2351759102 HVBusActiveIsolTestCmd 11263;
BA_ "SigType" SG_ 2351759102 PwrDownCmd 5;
BA_ "SPN" SG_ 2351759102 PwrDownCmd 11262;
BA_ "SigType" SG_ 2351759102 HVBusConnectCmd 5;
BA_ "SPN" SG_ 2351759102 HVBusConnectCmd 11261;
BA_ "SigType" SG_ 2351693566 ThermalMnmgtMaintenanceReq 5;
BA_ "SPN" SG_ 2351693566 ThermalMnmgtMaintenanceReq 20880;
BA_ "SigType" SG_ 2351693566 Ctrl1CRC 12;
BA_ "SPN" SG_ 2351693566 Ctrl1CRC 13032;
BA_ "SigType" SG_ 2351693566 Ctrl1Counter 11;
BA_ "SPN" SG_ 2351693566 Ctrl1Counter 13031;
BA_ "SigType" SG_ 2351693566 HVBusLowSideResistorConnectReq 5;
BA_ "SPN" SG_ 2351693566 HVBusLowSideResistorConnectReq 11153;
BA_ "SigType" SG_ 2351693566 HVBusHiSideResistorConnectReq 5;
BA_ "SPN" SG_ 2351693566 HVBusHiSideResistorConnectReq 11152;
BA_ "SigType" SG_ 2351693566 OpConsent 4;
BA_ "SPN" SG_ 2351693566 OpConsent 11151;
BA_ "SigType" SG_ 2351693566 EnableInternalChargerCmd 5;
BA_ "SPN" SG_ 2351693566 EnableInternalChargerCmd 11150;
BA_ "SigType" SG_ 2351693566 CellBalancingCmd 5;
BA_ "SPN" SG_ 2351693566 CellBalancingCmd 11149;
BA_ "SigType" SG_ 2351693566 HVBusPassiveIsolTestCmd 5;
BA_ "SPN" SG_ 2351693566 HVBusPassiveIsolTestCmd 11148;
BA_ "SigType" SG_ 2351693566 HVBusActiveIsolTestCmd 5;
BA_ "SPN" SG_ 2351693566 HVBusActiveIsolTestCmd 11147;
BA_ "SigType" SG_ 2351693566 PwrDownCmd 5;
BA_ "SPN" SG_ 2351693566 PwrDownCmd 11146;
BA_ "SigType" SG_ 2351693566 HVBusConnectCmd 5;
BA_ "SPN" SG_ 2351693566 HVBusConnectCmd 11145;
BA_ "SigType" SG_ 2351628030 ThermalMnmgtMaintenanceReq 5;
BA_ "SPN" SG_ 2351628030 ThermalMnmgtMaintenanceReq 20879;
BA_ "SigType" SG_ 2351628030 Ctrl1CRC 12;
BA_ "SPN" SG_ 2351628030 Ctrl1CRC 13030;
BA_ "SigType" SG_ 2351628030 Ctrl1Counter 11;
BA_ "SPN" SG_ 2351628030 Ctrl1Counter 13029;
BA_ "SigType" SG_ 2351628030 HVBusLowSideResistorConnectReq 5;
BA_ "SPN" SG_ 2351628030 HVBusLowSideResistorConnectReq 11037;
BA_ "SigType" SG_ 2351628030 HVBusHiSideResistorConnectReq 5;
BA_ "SPN" SG_ 2351628030 HVBusHiSideResistorConnectReq 11036;
BA_ "SigType" SG_ 2351628030 OpConsent 4;
BA_ "SPN" SG_ 2351628030 OpConsent 11035;
BA_ "SigType" SG_ 2351628030 EnableInternalChargerCmd 5;
BA_ "SPN" SG_ 2351628030 EnableInternalChargerCmd 11034;
BA_ "SigType" SG_ 2351628030 CellBalancingCmd 5;
BA_ "SPN" SG_ 2351628030 CellBalancingCmd 11033;
BA_ "SigType" SG_ 2351628030 HVBusPassiveIsolTestCmd 5;
BA_ "SPN" SG_ 2351628030 HVBusPassiveIsolTestCmd 11032;
BA_ "SigType" SG_ 2351628030 HVBusActiveIsolTestCmd 5;
BA_ "SPN" SG_ 2351628030 HVBusActiveIsolTestCmd 11031;
BA_ "SigType" SG_ 2351628030 PwrDownCmd 5;
BA_ "SPN" SG_ 2351628030 PwrDownCmd 11030;
BA_ "SigType" SG_ 2351628030 HVBusConnectCmd 5;
BA_ "SPN" SG_ 2351628030 HVBusConnectCmd 11029;
BA_ "SPN" SG_ 2552889086 AbsTrqRateLmt 10835;
BA_ "SPN" SG_ 2552889086 AbsSpdRateLmt 10834;
BA_ "SigType" SG_ 2552889086 Counter 11;
BA_ "SPN" SG_ 2552889086 Counter 10833;
BA_ "SigType" SG_ 2552889086 CRC 12;
BA_ "SPN" SG_ 2552889086 CRC 10832;
BA_ "SPN" SG_ 2552823550 AbsTrqRateLmt 10797;
BA_ "SPN" SG_ 2552823550 AbsSpdRateLmt 10796;
BA_ "SigType" SG_ 2552823550 Counter 11;
BA_ "SPN" SG_ 2552823550 Counter 10795;
BA_ "SigType" SG_ 2552823550 CRC 12;
BA_ "SPN" SG_ 2552823550 CRC 10794;
BA_ "SigType" SG_ 2351431422 SetpointReq 1;
BA_ "SPN" SG_ 2351431422 SetpointReq 10229;
BA_ "SPN" SG_ 2351431422 SetpointModeReq 10228;
BA_ "SPN" SG_ 2351431422 LimitsReqOvrdMin 10227;
BA_ "SPN" SG_ 2351431422 LimitsReqOvrdMax 10226;
BA_ "SPN" SG_ 2351431422 LimitsReqOvrdMode 10225;
BA_ "SigType" SG_ 2351431422 Counter 11;
BA_ "SPN" SG_ 2351431422 Counter 10224;
BA_ "SigType" SG_ 2351431422 CRC 12;
BA_ "SPN" SG_ 2351431422 CRC 10223;
BA_ "SigType" SG_ 2351365886 SetpointReq 1;
BA_ "SPN" SG_ 2351365886 SetpointReq 10163;
BA_ "SPN" SG_ 2351365886 SetpointModeReq 10162;
BA_ "SPN" SG_ 2351365886 LimitsReqOvrdMin 10161;
BA_ "SPN" SG_ 2351365886 LimitsReqOvrdMax 10160;
BA_ "SPN" SG_ 2351365886 LimitsReqOvrdMode 10159;
BA_ "SigType" SG_ 2351365886 Counter 11;
BA_ "SPN" SG_ 2351365886 Counter 10158;
BA_ "SigType" SG_ 2351365886 CRC 12;
BA_ "SPN" SG_ 2351365886 CRC 10157;
BA_ "SigType" SG_ 2365313534 SLIBatTempMaxLmtReq 1;
BA_ "SPN" SG_ 2365313534 SLIBatTempMaxLmtReq 8819;
BA_ "SigType" SG_ 2365313534 SLIBatTermChargeCurMaxLmtReq 1;
BA_ "SPN" SG_ 2365313534 SLIBatTermChargeCurMaxLmtReq 8818;
BA_ "SigType" SG_ 2365313534 SLIBatTermVMaxLmtReq 1;
BA_ "SPN" SG_ 2365313534 SLIBatTermVMaxLmtReq 8817;
BA_ "SigType" SG_ 2566639870 OneLowSideVBuckDefaultSetting 1;
BA_ "SPN" SG_ 2566639870 OneLowSideVBuckDefaultSetting 9519;
BA_ "SigType" SG_ 2566639870 SLIBatTempMaxLmtSetting 1;
BA_ "SPN" SG_ 2566639870 SLIBatTempMaxLmtSetting 8832;
BA_ "SigType" SG_ 2566639870 SLIBatTermChargeCurMaxLmtSetting 1;
BA_ "SPN" SG_ 2566639870 SLIBatTermChargeCurMaxLmtSetting 8831;
BA_ "SigType" SG_ 2566639870 SLIBatTermVMaxLmtSetting 1;
BA_ "SPN" SG_ 2566639870 SLIBatTermVMaxLmtSetting 8830;
BA_ "SigType" SG_ 2566639870 OneLowSideCurMaxLmtSetting 1;
BA_ "SPN" SG_ 2566639870 OneLowSideCurMaxLmtSetting 8829;
BA_ "SigType" SG_ 2566639870 OneLowSideVMaxLmtSetting 1;
BA_ "SPN" SG_ 2566639870 OneLowSideVMaxLmtSetting 8828;
BA_ "SigType" SG_ 2566639870 OneLowSideVMinLmtSetting 1;
BA_ "SPN" SG_ 2566639870 OneLowSideVMinLmtSetting 8827;
BA_ "SigType" SG_ 2566639870 OneHiSideCurMaxLmtSetting 1;
BA_ "SPN" SG_ 2566639870 OneHiSideCurMaxLmtSetting 8826;
BA_ "SigType" SG_ 2566639870 OneHiSideVMaxLmtSetting 1;
BA_ "SPN" SG_ 2566639870 OneHiSideVMaxLmtSetting 8825;
BA_ "SigType" SG_ 2566639870 OneHiSideVMinLmtSetting 1;
BA_ "SPN" SG_ 2566639870 OneHiSideVMinLmtSetting 8824;
BA_ "SigType" SG_ 2566639614 OneTotalLowSideCharge 1;
BA_ "SPN" SG_ 2566639614 OneTotalLowSideCharge 8836;
BA_ "SigType" SG_ 2566639614 OneTotalHiSideCharge 1;
BA_ "SPN" SG_ 2566639614 OneTotalHiSideCharge 8835;
BA_ "SigType" SG_ 2566639614 OneTotalLowSideEnergy 1;
BA_ "SPN" SG_ 2566639614 OneTotalLowSideEnergy 8834;
BA_ "SigType" SG_ 2566639614 OneTotalHiSideEnergy 1;
BA_ "SPN" SG_ 2566639614 OneTotalHiSideEnergy 8833;
BA_ "SigType" SG_ 2633748222 SPNModifiedStatus 5;
BA_ "SPN" SG_ 2633748222 SPNModifiedStatus 8847;
BA_ "SPN" SG_ 2633748222 SPNSA 8846;
BA_ "SPN" SG_ 2633748222 SPNDetailedStatus 8848;
BA_ "SPN" SG_ 2633748222 SPN 8845;
BA_ "SPN" SG_ 2633748222 PortCmdStatus 8844;
BA_ "SPN" SG_ 2633748222 PortPendingChangesStatus 8843;
BA_ "SPN" SG_ 2633748222 Port 8842;
BA_ "SPN" SG_ 2566639102 PlungerFiringOrderSetting 8881;
BA_ "SigType" SG_ 2566639102 RodLoadHiThreshold 1;
BA_ "SPN" SG_ 2566639102 RodLoadHiThreshold 8880;
BA_ "SigType" SG_ 2566639102 CrankshaftSpdHiThreshold 1;
BA_ "SPN" SG_ 2566639102 CrankshaftSpdHiThreshold 8879;
BA_ "SigType" SG_ 2566639102 CrankshaftSpdLowThreshold 1;
BA_ "SPN" SG_ 2566639102 CrankshaftSpdLowThreshold 8878;
BA_ "SigType" SG_ 2566639102 DisPressHiThreshold 1;
BA_ "SPN" SG_ 2566639102 DisPressHiThreshold 8877;
BA_ "SigType" SG_ 2566639102 SuctionPressHiThreshold 1;
BA_ "SPN" SG_ 2566639102 SuctionPressHiThreshold 8876;
BA_ "SigType" SG_ 2566639102 SuctionPressLowThreshold 1;
BA_ "SPN" SG_ 2566639102 SuctionPressLowThreshold 8875;
BA_ "SigType" SG_ 2566639102 GearBoxOilTempHiThreshold 1;
BA_ "SPN" SG_ 2566639102 GearBoxOilTempHiThreshold 8874;
BA_ "SigType" SG_ 2566639102 GearBoxOilTempLowThreshold 1;
BA_ "SPN" SG_ 2566639102 GearBoxOilTempLowThreshold 8873;
BA_ "SigType" SG_ 2566639102 GearBoxOilPressHiThreshold 1;
BA_ "SPN" SG_ 2566639102 GearBoxOilPressHiThreshold 8872;
BA_ "SigType" SG_ 2566639102 GearBoxOilPressLowThreshold 1;
BA_ "SPN" SG_ 2566639102 GearBoxOilPressLowThreshold 8871;
BA_ "SigType" SG_ 2566638846 VlvSeatOpHours 1;
BA_ "SPN" SG_ 2566638846 VlvSeatOpHours 8885;
BA_ "SigType" SG_ 2566638846 PackingOpHours 1;
BA_ "SPN" SG_ 2566638846 PackingOpHours 8884;
BA_ "SigType" SG_ 2566638846 VlvOpHours 1;
BA_ "SPN" SG_ 2566638846 VlvOpHours 8883;
BA_ "SigType" SG_ 2566638846 MaintenanceIntervalHours 1;
BA_ "SPN" SG_ 2566638846 MaintenanceIntervalHours 8882;
BA_ "SigType" SG_ 2566638590 DiagCount 1;
BA_ "SPN" SG_ 2566638590 DiagCount 8888;
BA_ "SigType" SG_ 2566638590 DiagTime 1;
BA_ "SPN" SG_ 2566638590 DiagTime 8887;
BA_ "SigType" SG_ 2365311486 TwoHiSideCurMaxLmtReq 1;
BA_ "SPN" SG_ 2365311486 TwoHiSideCurMaxLmtReq 8946;
BA_ "SigType" SG_ 2365311486 TwoHiSideVMaxLmtReq 1;
BA_ "SPN" SG_ 2365311486 TwoHiSideVMaxLmtReq 8945;
BA_ "SigType" SG_ 2365311486 TwoHiSideVMinLmtReq 1;
BA_ "SPN" SG_ 2365311486 TwoHiSideVMinLmtReq 8944;
BA_ "SigType" SG_ 2365311230 TwoLowSideCurMaxLmtReq 1;
BA_ "SPN" SG_ 2365311230 TwoLowSideCurMaxLmtReq 8943;
BA_ "SigType" SG_ 2365311230 TwoLowSideVMaxLmtReq 1;
BA_ "SPN" SG_ 2365311230 TwoLowSideVMaxLmtReq 8942;
BA_ "SigType" SG_ 2365311230 TwoLowSideVMinLmtReq 1;
BA_ "SPN" SG_ 2365311230 TwoLowSideVMinLmtReq 8941;
BA_ "SigType" SG_ 2365310974 TwoCoolantOutTemp 1;
BA_ "SPN" SG_ 2365310974 TwoCoolantOutTemp 8940;
BA_ "SigType" SG_ 2365310974 TwoCoolantInTemp 1;
BA_ "SPN" SG_ 2365310974 TwoCoolantInTemp 8939;
BA_ "SigType" SG_ 2365310974 TwoPwrETemp 1;
BA_ "SPN" SG_ 2365310974 TwoPwrETemp 8938;
BA_ "SigType" SG_ 2365310974 TwoConvEFilterTemp 1;
BA_ "SPN" SG_ 2365310974 TwoConvEFilterTemp 8937;
BA_ "SigType" SG_ 2365310974 TwoConvTemp 1;
BA_ "SPN" SG_ 2365310974 TwoConvTemp 8936;
BA_ "SigType" SG_ 2365310718 SLIBatTempMaxLmtReq 1;
BA_ "SPN" SG_ 2365310718 SLIBatTempMaxLmtReq 8935;
BA_ "SigType" SG_ 2365310718 SLIBatTermChargeCurMaxLmtReq 1;
BA_ "SPN" SG_ 2365310718 SLIBatTermChargeCurMaxLmtReq 8934;
BA_ "SigType" SG_ 2365310718 SLIBatTermVMaxLmtReq 1;
BA_ "SPN" SG_ 2365310718 SLIBatTermVMaxLmtReq 8933;
BA_ "SigType" SG_ 2566637054 TwoLowSideVBuckDefaultSetting 1;
BA_ "SPN" SG_ 2566637054 TwoLowSideVBuckDefaultSetting 9520;
BA_ "SigType" SG_ 2566637054 SLIBatTempMaxLmtSetting 1;
BA_ "SPN" SG_ 2566637054 SLIBatTempMaxLmtSetting 8932;
BA_ "SigType" SG_ 2566637054 SLIBatTermChargeCurMaxLmtSetting 1;
BA_ "SPN" SG_ 2566637054 SLIBatTermChargeCurMaxLmtSetting 8931;
BA_ "SigType" SG_ 2566637054 SLIBatTermVMaxLmtSetting 1;
BA_ "SPN" SG_ 2566637054 SLIBatTermVMaxLmtSetting 8930;
BA_ "SigType" SG_ 2566637054 TwoLowSideCurMaxLmtSetting 1;
BA_ "SPN" SG_ 2566637054 TwoLowSideCurMaxLmtSetting 8929;
BA_ "SigType" SG_ 2566637054 TwoLowSideVMaxLmtSetting 1;
BA_ "SPN" SG_ 2566637054 TwoLowSideVMaxLmtSetting 8928;
BA_ "SigType" SG_ 2566637054 TwoLowSideVMinLmtSetting 1;
BA_ "SPN" SG_ 2566637054 TwoLowSideVMinLmtSetting 8927;
BA_ "SigType" SG_ 2566637054 TwoHiSideCurMaxLmtSetting 1;
BA_ "SPN" SG_ 2566637054 TwoHiSideCurMaxLmtSetting 8926;
BA_ "SigType" SG_ 2566637054 TwoHiSideVMaxLmtSetting 1;
BA_ "SPN" SG_ 2566637054 TwoHiSideVMaxLmtSetting 8925;
BA_ "SigType" SG_ 2566637054 TwoHiSideVMinLmtSetting 1;
BA_ "SPN" SG_ 2566637054 TwoHiSideVMinLmtSetting 8924;
BA_ "SigType" SG_ 2566636798 TwoTotalLowSideCharge 1;
BA_ "SPN" SG_ 2566636798 TwoTotalLowSideCharge 8923;
BA_ "SigType" SG_ 2566636798 TwoTotalHiSideCharge 1;
BA_ "SPN" SG_ 2566636798 TwoTotalHiSideCharge 8922;
BA_ "SigType" SG_ 2566636798 TwoTotalLowSideEnergy 1;
BA_ "SPN" SG_ 2566636798 TwoTotalLowSideEnergy 8921;
BA_ "SigType" SG_ 2566636798 TwoTotalHiSideEnergy 1;
BA_ "SPN" SG_ 2566636798 TwoTotalHiSideEnergy 8920;
BA_ "SigType" SG_ 2365309950 ThreeHiSideCurMaxLmtReq 1;
BA_ "SPN" SG_ 2365309950 ThreeHiSideCurMaxLmtReq 9001;
BA_ "SigType" SG_ 2365309950 ThreeHiSideVMaxLmtReq 1;
BA_ "SPN" SG_ 2365309950 ThreeHiSideVMaxLmtReq 9000;
BA_ "SigType" SG_ 2365309950 ThreeHiSideVMinLmtReq 1;
BA_ "SPN" SG_ 2365309950 ThreeHiSideVMinLmtReq 8999;
BA_ "SigType" SG_ 2365309694 ThreeLowSideCurMaxLmtReq 1;
BA_ "SPN" SG_ 2365309694 ThreeLowSideCurMaxLmtReq 8998;
BA_ "SigType" SG_ 2365309694 ThreeLowSideVMaxLmtReq 1;
BA_ "SPN" SG_ 2365309694 ThreeLowSideVMaxLmtReq 8997;
BA_ "SigType" SG_ 2365309694 ThreeLowSideVMinLmtReq 1;
BA_ "SPN" SG_ 2365309694 ThreeLowSideVMinLmtReq 8996;
BA_ "SigType" SG_ 2365309438 ThreeCoolantOutTemp 1;
BA_ "SPN" SG_ 2365309438 ThreeCoolantOutTemp 8995;
BA_ "SigType" SG_ 2365309438 ThreeCoolantInTemp 1;
BA_ "SPN" SG_ 2365309438 ThreeCoolantInTemp 8994;
BA_ "SigType" SG_ 2365309438 ThreePwrETemp 1;
BA_ "SPN" SG_ 2365309438 ThreePwrETemp 8993;
BA_ "SigType" SG_ 2365309438 ThreeConvEFilterTemp 1;
BA_ "SPN" SG_ 2365309438 ThreeConvEFilterTemp 8992;
BA_ "SigType" SG_ 2365309438 ThreeConvTemp 1;
BA_ "SPN" SG_ 2365309438 ThreeConvTemp 8991;
BA_ "SigType" SG_ 2365309182 SLIBatTempMaxLmtReq 1;
BA_ "SPN" SG_ 2365309182 SLIBatTempMaxLmtReq 8990;
BA_ "SigType" SG_ 2365309182 SLIBatTermChargeCurMaxLmtReq 1;
BA_ "SPN" SG_ 2365309182 SLIBatTermChargeCurMaxLmtReq 8989;
BA_ "SigType" SG_ 2365309182 SLIBatTermVMaxLmtReq 1;
BA_ "SPN" SG_ 2365309182 SLIBatTermVMaxLmtReq 8988;
BA_ "SigType" SG_ 2566635518 ThreeLowSideVBuckDefaultSetting 1;
BA_ "SPN" SG_ 2566635518 ThreeLowSideVBuckDefaultSetting 9521;
BA_ "SigType" SG_ 2566635518 SLIBatTempMaxLmtSetting 1;
BA_ "SPN" SG_ 2566635518 SLIBatTempMaxLmtSetting 8987;
BA_ "SigType" SG_ 2566635518 SLIBatTermChargeCurMaxLmtSetting 1;
BA_ "SPN" SG_ 2566635518 SLIBatTermChargeCurMaxLmtSetting 8986;
BA_ "SigType" SG_ 2566635518 SLIBatTermVMaxLmtSetting 1;
BA_ "SPN" SG_ 2566635518 SLIBatTermVMaxLmtSetting 8985;
BA_ "SigType" SG_ 2566635518 ThreeLowSideCurMaxLmtSetting 1;
BA_ "SPN" SG_ 2566635518 ThreeLowSideCurMaxLmtSetting 8984;
BA_ "SigType" SG_ 2566635518 ThreeLowSideVMaxLmtSetting 1;
BA_ "SPN" SG_ 2566635518 ThreeLowSideVMaxLmtSetting 8983;
BA_ "SigType" SG_ 2566635518 ThreeLowSideVMinLmtSetting 1;
BA_ "SPN" SG_ 2566635518 ThreeLowSideVMinLmtSetting 8982;
BA_ "SigType" SG_ 2566635518 ThreeHiSideCurMaxLmtSetting 1;
BA_ "SPN" SG_ 2566635518 ThreeHiSideCurMaxLmtSetting 8981;
BA_ "SigType" SG_ 2566635518 ThreeHiSideVMaxLmtSetting 1;
BA_ "SPN" SG_ 2566635518 ThreeHiSideVMaxLmtSetting 8980;
BA_ "SigType" SG_ 2566635518 ThreeHiSideVMinLmtSetting 1;
BA_ "SPN" SG_ 2566635518 ThreeHiSideVMinLmtSetting 8979;
BA_ "SigType" SG_ 2566635262 ThreeTotalLowSideCharge 1;
BA_ "SPN" SG_ 2566635262 ThreeTotalLowSideCharge 8978;
BA_ "SigType" SG_ 2566635262 ThreeTotalHiSideCharge 1;
BA_ "SPN" SG_ 2566635262 ThreeTotalHiSideCharge 8977;
BA_ "SigType" SG_ 2566635262 ThreeTotalLowSideEnergy 1;
BA_ "SPN" SG_ 2566635262 ThreeTotalLowSideEnergy 8976;
BA_ "SigType" SG_ 2566635262 ThreeTotalHiSideEnergy 1;
BA_ "SPN" SG_ 2566635262 ThreeTotalHiSideEnergy 8975;
BA_ "SigType" SG_ 2365308414 FourHiSideCurMaxLmtReq 1;
BA_ "SPN" SG_ 2365308414 FourHiSideCurMaxLmtReq 9056;
BA_ "SigType" SG_ 2365308414 FourHiSideVMaxLmtReq 1;
BA_ "SPN" SG_ 2365308414 FourHiSideVMaxLmtReq 9055;
BA_ "SigType" SG_ 2365308414 FourHiSideVMinLmtReq 1;
BA_ "SPN" SG_ 2365308414 FourHiSideVMinLmtReq 9054;
BA_ "SigType" SG_ 2365308158 FourLowSideCurMaxLmtReq 1;
BA_ "SPN" SG_ 2365308158 FourLowSideCurMaxLmtReq 9053;
BA_ "SigType" SG_ 2365308158 FourLowSideVMaxLmtReq 1;
BA_ "SPN" SG_ 2365308158 FourLowSideVMaxLmtReq 9052;
BA_ "SigType" SG_ 2365308158 FourLowSideVMinLmtReq 1;
BA_ "SPN" SG_ 2365308158 FourLowSideVMinLmtReq 9051;
BA_ "SigType" SG_ 2365307902 FourCoolantOutTemp 1;
BA_ "SPN" SG_ 2365307902 FourCoolantOutTemp 9050;
BA_ "SigType" SG_ 2365307902 FourCoolantInTemp 1;
BA_ "SPN" SG_ 2365307902 FourCoolantInTemp 9049;
BA_ "SigType" SG_ 2365307902 FourPwrETemp 1;
BA_ "SPN" SG_ 2365307902 FourPwrETemp 9048;
BA_ "SigType" SG_ 2365307902 FourConvEFilterTemp 1;
BA_ "SPN" SG_ 2365307902 FourConvEFilterTemp 9047;
BA_ "SigType" SG_ 2365307902 FourConvTemp 1;
BA_ "SPN" SG_ 2365307902 FourConvTemp 9046;
BA_ "SigType" SG_ 2365307646 SLIBatTempMaxLmtReq 1;
BA_ "SPN" SG_ 2365307646 SLIBatTempMaxLmtReq 9045;
BA_ "SigType" SG_ 2365307646 SLIBatTermChargeCurMaxLmtReq 1;
BA_ "SPN" SG_ 2365307646 SLIBatTermChargeCurMaxLmtReq 9044;
BA_ "SigType" SG_ 2365307646 SLIBatTermVMaxLmtReq 1;
BA_ "SPN" SG_ 2365307646 SLIBatTermVMaxLmtReq 9043;
BA_ "SigType" SG_ 2566633982 FourLowSideVBuckDefaultSetting 1;
BA_ "SPN" SG_ 2566633982 FourLowSideVBuckDefaultSetting 9522;
BA_ "SigType" SG_ 2566633982 SLIBatTempMaxLmtSetting 1;
BA_ "SPN" SG_ 2566633982 SLIBatTempMaxLmtSetting 9042;
BA_ "SigType" SG_ 2566633982 SLIBatTermChargeCurMaxLmtSetting 1;
BA_ "SPN" SG_ 2566633982 SLIBatTermChargeCurMaxLmtSetting 9041;
BA_ "SigType" SG_ 2566633982 SLIBatTermVMaxLmtSetting 1;
BA_ "SPN" SG_ 2566633982 SLIBatTermVMaxLmtSetting 9040;
BA_ "SigType" SG_ 2566633982 FourLowSideCurMaxLmtSetting 1;
BA_ "SPN" SG_ 2566633982 FourLowSideCurMaxLmtSetting 9039;
BA_ "SigType" SG_ 2566633982 FourLowSideVMaxLmtSetting 1;
BA_ "SPN" SG_ 2566633982 FourLowSideVMaxLmtSetting 9038;
BA_ "SigType" SG_ 2566633982 FourLowSideVMinLmtSetting 1;
BA_ "SPN" SG_ 2566633982 FourLowSideVMinLmtSetting 9037;
BA_ "SigType" SG_ 2566633982 FourHiSideCurMaxLmtSetting 1;
BA_ "SPN" SG_ 2566633982 FourHiSideCurMaxLmtSetting 9036;
BA_ "SigType" SG_ 2566633982 FourHiSideVMaxLmtSetting 1;
BA_ "SPN" SG_ 2566633982 FourHiSideVMaxLmtSetting 9035;
BA_ "SigType" SG_ 2566633982 FourHiSideVMinLmtSetting 1;
BA_ "SPN" SG_ 2566633982 FourHiSideVMinLmtSetting 9034;
BA_ "SigType" SG_ 2566633726 FourTotalLowSideCharge 1;
BA_ "SPN" SG_ 2566633726 FourTotalLowSideCharge 9033;
BA_ "SigType" SG_ 2566633726 FourTotalHiSideCharge 1;
BA_ "SPN" SG_ 2566633726 FourTotalHiSideCharge 9032;
BA_ "SigType" SG_ 2566633726 FourTotalLowSideEnergy 1;
BA_ "SPN" SG_ 2566633726 FourTotalLowSideEnergy 9031;
BA_ "SigType" SG_ 2566633726 FourTotalHiSideEnergy 1;
BA_ "SPN" SG_ 2566633726 FourTotalHiSideEnergy 9030;
BA_ "SigType" SG_ 2566633470 NOxSnsrProtAirPress 1;
BA_ "SPN" SG_ 2566633470 NOxSnsrProtAirPress 12907;
BA_ "SigType" SG_ 2566633470 O2PumpingCur 1;
BA_ "SPN" SG_ 2566633470 O2PumpingCur 9177;
BA_ "SigType" SG_ 2566633214 NOxSnsrProtAirPress 1;
BA_ "SPN" SG_ 2566633214 NOxSnsrProtAirPress 12908;
BA_ "SigType" SG_ 2566633214 O2PumpingCur 1;
BA_ "SPN" SG_ 2566633214 O2PumpingCur 9178;
BA_ "SigType" SG_ 2566632958 PwrEndTripHours 1;
BA_ "SPN" SG_ 2566632958 PwrEndTripHours 9188;
BA_ "SigType" SG_ 2566632958 FluidEndTripHours 1;
BA_ "SPN" SG_ 2566632958 FluidEndTripHours 9187;
BA_ "SigType" SG_ 2566632702 FluidEndSerialNum 8;
BA_ "SPN" SG_ 2566632702 FluidEndSerialNum 9190;
BA_ "SigType" SG_ 2566632702 PwrEndSerialNum 8;
BA_ "SPN" SG_ 2566632702 PwrEndSerialNum 9189;
BA_ "SigType" SG_ 2566632446 TripFluidPumped 1;
BA_ "SPN" SG_ 2566632446 TripFluidPumped 9192;
BA_ "SigType" SG_ 2566632446 TotalFluidPumped 1;
BA_ "SPN" SG_ 2566632446 TotalFluidPumped 9191;
BA_ "SigType" SG_ 2566632190 DisPressCalSetPointStatus 4;
BA_ "SPN" SG_ 2566632190 DisPressCalSetPointStatus 9196;
BA_ "SPN" SG_ 2566632190 DisPressCalSetPoint 9195;
BA_ "SigType" SG_ 2566632190 SuctionPressCalSetPointStatus 4;
BA_ "SPN" SG_ 2566632190 SuctionPressCalSetPointStatus 9194;
BA_ "SPN" SG_ 2566632190 SuctionPressCalSetPoint 9193;
BA_ "SigType" SG_ 2566631934 TotalDCInputEnergy 1;
BA_ "SPN" SG_ 2566631934 TotalDCInputEnergy 9366;
BA_ "SigType" SG_ 2566631934 TotalDCInputCharge 1;
BA_ "SPN" SG_ 2566631934 TotalDCInputCharge 9365;
BA_ "SigType" SG_ 2566631678 ACSideDefaultFreqCmdSetting 1;
BA_ "SPN" SG_ 2566631678 ACSideDefaultFreqCmdSetting 9557;
BA_ "SigType" SG_ 2566631678 DCSideCurMinLmtSetting 1;
BA_ "SPN" SG_ 2566631678 DCSideCurMinLmtSetting 9556;
BA_ "SigType" SG_ 2566631678 DCSideVMaxLmtSetting 1;
BA_ "SPN" SG_ 2566631678 DCSideVMaxLmtSetting 9555;
BA_ "SigType" SG_ 2566631678 ACSideRMSCurMaxLmtSetting 1;
BA_ "SPN" SG_ 2566631678 ACSideRMSCurMaxLmtSetting 9364;
BA_ "SigType" SG_ 2566631678 ACSideRMSVMaxLmtSetting 1;
BA_ "SPN" SG_ 2566631678 ACSideRMSVMaxLmtSetting 9363;
BA_ "SigType" SG_ 2566631678 DCSideCurMaxLmtSetting 1;
BA_ "SPN" SG_ 2566631678 DCSideCurMaxLmtSetting 9362;
BA_ "SigType" SG_ 2566631678 DCSideVMinLmtSetting 1;
BA_ "SPN" SG_ 2566631678 DCSideVMinLmtSetting 9361;
BA_ "SigType" SG_ 2365304830 DefaultFreqReq 1;
BA_ "SPN" SG_ 2365304830 DefaultFreqReq 9527;
BA_ "SigType" SG_ 2365304830 RMSCurMaxLmtReq 1;
BA_ "SPN" SG_ 2365304830 RMSCurMaxLmtReq 9360;
BA_ "SigType" SG_ 2365304830 RMSVMaxLmtReq 1;
BA_ "SPN" SG_ 2365304830 RMSVMaxLmtReq 9359;
BA_ "SigType" SG_ 2365304574 CurMinLmtReq 1;
BA_ "SPN" SG_ 2365304574 CurMinLmtReq 9554;
BA_ "SigType" SG_ 2365304574 VMaxLmtReq 1;
BA_ "SPN" SG_ 2365304574 VMaxLmtReq 9553;
BA_ "SigType" SG_ 2365304574 CurMaxLmtReq 1;
BA_ "SPN" SG_ 2365304574 CurMaxLmtReq 9358;
BA_ "SigType" SG_ 2365304574 VMinLmtReq 1;
BA_ "SPN" SG_ 2365304574 VMinLmtReq 9357;
BA_ "SigType" SG_ 2566630910 CoolantOutTemp 1;
BA_ "SPN" SG_ 2566630910 CoolantOutTemp 9341;
BA_ "SigType" SG_ 2566630910 CoolantInTemp 1;
BA_ "SPN" SG_ 2566630910 CoolantInTemp 9340;
BA_ "SigType" SG_ 2566630910 PwrETemp 1;
BA_ "SPN" SG_ 2566630910 PwrETemp 9339;
BA_ "SigType" SG_ 2566630910 InverterEFilterTemp 1;
BA_ "SPN" SG_ 2566630910 InverterEFilterTemp 9338;
BA_ "SigType" SG_ 2566630910 CtrlTemp 1;
BA_ "SPN" SG_ 2566630910 CtrlTemp 9337;
VAL_ 2364622078 InSync 3 "Not Available or Not Installed" 2 "Error" 1 "Synchronized" 0 "Not synchronized" ;
VAL_ 2364622078 VMatch 3 "Not Available or Not Installed" 2 "Error" 1 "Voltages match" 0 "Voltages do not match" ;
VAL_ 2364622078 FreqMatch 3 "Not Available or Not Installed" 2 "Error" 1 "Frequencies match" 0 "Frequencies do not match" ;
VAL_ 2364622078 PhaseMatch 3 "Not Available or Not Installed" 2 "Error" 1 "Phases match" 0 "Phases do not match" ;
VAL_ 2364622078 DeadBus 3 "Not Available or Not Installed" 2 "Error" 1 "Bus is dead" 0 "Bus is not dead" ;
VAL_ 2364621822 AuxShutdownSw 3 "Not available" 2 "Error" 1 "On" 0 "Off" ;
VAL_ 2364621822 NotReadyToAutoParallelSt 3 "Not available" 2 "Error" 1 "Active" 0 "Inactive" ;
VAL_ 2364621310 OverallPwrFactorLagging 3 "Not Available or Not Installed" 2 "Error" 1 "Lagging" 0 "Leading" ;
VAL_ 2557017854 OBPKeySwReq 3 "Don't care/take no action" 2 "Reserved" 1 "On board programming device is requesting key switch on." 0 "On board programming device is not requesting key switch on." ;
VAL_ 2557017854 InterlockTargetNotReady 3 "Not available" 2 "Error" 1 "On: Target has indicated that it is currently unable to accept on board programming" 0 "Off: Target is not inhibiting on board programming" ;
VAL_ 2557017854 InterlockPwrSupplyInsufficient 3 "Not available" 2 "Error" 1 "On: On board programming is inhibited due to insufficient power supply" 0 "Off: Power supply is sufficient to permit on board programming" ;
VAL_ 2557017854 InterlockParkBrk 3 "Not available" 2 "Error" 1 "On: On board programming is inhibited due to park brake" 0 "Off: Park brake is permitting on board programming" ;
VAL_ 2557017854 InterlockKeySwPos 3 "Not available" 2 "Error" 1 "On: On board programming is inhibited due to key switch position" 0 "Off: Key switch position is permitting on board programming" ;
VAL_ 2557017854 InterlockEngSpd 3 "Not available" 2 "Error" 1 "On: On board programming is inhibited due to engine speed." 0 "Off: Engine speed is permitting on board programming" ;
VAL_ 2557017854 InterlockOverallStatus 3 "Not available" 2 "Error" 1 "On: Programming is inhibited" 0 "Off: Programming is premitted" ;
VAL_ 2557017854 Status 15 "Not Available" 14 "Error" 13 "Reserved" 12 "Reserved" 11 "Reserved" 10 "Reserved" 9 "Reserved" 8 "Reserved" 7 "In process/Reverting: update is unsuccessful or aborted and previous version is being restored" 6 "Declined or aborted by target device" 5 "Declined or aborted by operator" 4 "Unsuccessful, Operational: software update was unsuccessful and target ECU is restored to operation." 3 "Unsuccessful, Non-Operational: software update was unsuccessful and target ECU is not functional." 2 "In process/Installing: update has been initiated and progressing" 1 "Available for Installation: updated software is available" 0 "Software Up to Date: no new software is available" ;
VAL_ 2556952318 PwrHold 3 "Don't Care/Take no action" 2 "Reserved" 1 "Power Hold Enabled" 0 "Power Hold Disabled" ;
VAL_ 2556952318 EnableCmd 3 "Don't Care/Take no action" 2 "Accessory Motor On Reverse Direction" 1 "Accessory Motor On Normal/Default Direction" 0 "Accessory Motor Off" ;
VAL_ 2556886782 PwrHold 3 "Don't Care/Take no action" 2 "Reserved" 1 "Power Hold Enabled" 0 "Power Hold Disabled" ;
VAL_ 2556886782 EnableCmd 3 "Don't Care/Take no action" 2 "Accessory Motor On Reverse Direction" 1 "Accessory Motor On Normal/Default Direction" 0 "Accessory Motor Off" ;
VAL_ 2556559102 AlarmReceiveStatus 7 "Not Available or Not Installed" 6 "Reserved for SAE assignment" 5 "Reserved for SAE assignment" 4 "Reserved for SAE assignment" 3 "Reserved for SAE assignment" 2 "Reserved for SAE assignment" 1 "Alarm Status Data Received" 0 "Alarm Status Data Not Received" ;
VAL_ 2556100350 HVBusLowSideResistorConnectReq 3 "Don't care/take no action" 2 "Reserved" 1 "Connection Requested" 0 "Connection not Requested" ;
VAL_ 2556100350 HVBusHiSideResistorConnectReq 3 "Don't care/take no action" 2 "Reserved" 1 "Connection Requested" 0 "Connection not Requested" ;
VAL_ 2556100350 HVBusPassiveIsolTestCmd 3 "Don't care/Take no action" 2 "Inhibit Passive Isolation Test" 1 "Passive Isolation Test request" 0 "Passive Isolation Test not requested" ;
VAL_ 2556100350 HVBusActiveIsolTestCmd 3 "Don't care/Take no action" 2 "Inhibit Active Isolation Test" 1 "Active Isolation Test request" 0 "Active Isolation Test not requested" ;
VAL_ 2556034814 HVBusLowSideResistorConnectReq 3 "Don't care/take no action" 2 "Reserved" 1 "Connection Requested" 0 "Connection not Requested" ;
VAL_ 2556034814 HVBusHiSideResistorConnectReq 3 "Don't care/take no action" 2 "Reserved" 1 "Connection Requested" 0 "Connection not Requested" ;
VAL_ 2556034814 HVBusPassiveIsolTestCmd 3 "Don't care/Take no action" 2 "Inhibit Passive Isolation Test" 1 "Passive Isolation Test request" 0 "Passive Isolation Test not requested" ;
VAL_ 2556034814 HVBusActiveIsolTestCmd 3 "Don't care/Take no action" 2 "Inhibit Active Isolation Test" 1 "Active Isolation Test request" 0 "Active Isolation Test not requested" ;
VAL_ 2488860414 DetentStatus 3 "Not Available" 2 "Error Indicator" 1 "In the Detent" 0 "Not in the Detent" ;
VAL_ 2354577150 PIDCtrlApplicableMode 15 "Don't Care/Take No Action" 14 "SAE Reserved" 13 "SAE Reserved" 12 "SAE Reserved" 11 "SAE Reserved" 10 "SAE Reserved" 9 "SAE Reserved" 8 "SAE Reserved" 7 "SAE Reserved" 6 "SAE Reserved" 5 "SAE Reserved" 4 "Mechanical Power Control Mode" 3 "DC Power Control Mode" 2 "DC Side Current Mode" 1 "DC Side Voltage Mode" 0 "Speed Control Mode" ;
VAL_ 2354511614 PIDCtrlApplicableMode 15 "Don't Care/Take No Action" 14 "SAE Reserved" 13 "SAE Reserved" 12 "SAE Reserved" 11 "SAE Reserved" 10 "SAE Reserved" 9 "SAE Reserved" 8 "SAE Reserved" 7 "SAE Reserved" 6 "SAE Reserved" 5 "SAE Reserved" 4 "Mechanical Power Control Mode" 3 "DC Power Control Mode" 2 "DC Side Current Mode" 1 "DC Side Voltage Mode" 0 "Speed Control Mode" ;
VAL_ 2354446078 LiftAxle3PosCmd 3 "Don't care/take no action" 2 "Reserved" 1 "Lift axle position up / tag axle unladen" 0 "Lift axle position down / tag axle laden" ;
VAL_ 2555707134 PosReset 3 "Take no action" 2 "Reserved" 1 "Reset requested" 0 "Reset not requested" ;
VAL_ 2351955710 ThermalMnmgtMaintenanceReq 3 "Don't care/take no action" 2 "Reserved" 1 "HVESS Thermal Management Maintenance Mode is requested" 0 "HVESS Thermal Management Maintenance Mode is not requested" ;
VAL_ 2351955710 HVBusLowSideResistorConnectReq 3 "Don't care/take no action" 2 "Reserved" 1 "Connection Requested" 0 "Connection not Requested" ;
VAL_ 2351955710 HVBusHiSideResistorConnectReq 3 "Don't care/take no action" 2 "Reserved" 1 "Connection Requested" 0 "Connection not Requested" ;
VAL_ 2351955710 OpConsent 3 "Don't care/Take no action" 2 "Error" 1 "Consent given" 0 "Consent revoked" ;
VAL_ 2351955710 EnableInternalChargerCmd 3 "Don't care/Take no action" 2 "Reserved" 1 "Enable charging" 0 "Disable charging" ;
VAL_ 2351955710 CellBalancingCmd 3 "Don't care/Take no action" 2 "Reserved" 1 "Cell Balancing requested" 0 "Cell Balancing not requested" ;
VAL_ 2351955710 HVBusPassiveIsolTestCmd 3 "Don't care/Take no action" 2 "Reserved" 1 "Passive Isolation Test request" 0 "Passive Isolation Test not requested" ;
VAL_ 2351955710 HVBusActiveIsolTestCmd 3 "Don't care/Take no action" 2 "Reserved" 1 "Active Isolation Test request" 0 "Active Isolation Test not requested" ;
VAL_ 2351955710 PwrDownCmd 3 "Don't care/Take no action" 2 "Execute emergency power-down" 1 "Execute normal power-down" 0 "Power-down not requested" ;
VAL_ 2351955710 HVBusConnectCmd 3 "Don't care/Take no action" 2 "Emergency contactor closure request" 1 "Close Contactor" 0 "Open Contactor" ;
VAL_ 2351890174 ThermalMnmgtMaintenanceReq 3 "Don't care/take no action" 2 "Reserved" 1 "HVESS Thermal Management Maintenance Mode is requested" 0 "HVESS Thermal Management Maintenance Mode is not requested" ;
VAL_ 2351890174 HVBusLowSideResistorConnectReq 3 "Don't care/take no action" 2 "Reserved" 1 "Connection Requested" 0 "Connection not Requested" ;
VAL_ 2351890174 HVBusHiSideResistorConnectReq 3 "Don't care/take no action" 2 "Reserved" 1 "Connection Requested" 0 "Connection not Requested" ;
VAL_ 2351890174 OpConsent 3 "Don't care/Take no action" 2 "Error" 1 "Consent given" 0 "Consent revoked" ;
VAL_ 2351890174 EnableInternalChargerCmd 3 "Don't care/Take no action" 2 "Reserved" 1 "Enable charging" 0 "Disable charging" ;
VAL_ 2351890174 CellBalancingCmd 3 "Don't care/Take no action" 2 "Reserved" 1 "Cell Balancing requested" 0 "Cell Balancing not requested" ;
VAL_ 2351890174 HVBusPassiveIsolTestCmd 3 "Don't care/Take no action" 2 "Reserved" 1 "Passive Isolation Test request" 0 "Passive Isolation Test not requested" ;
VAL_ 2351890174 HVBusActiveIsolTestCmd 3 "Don't care/Take no action" 2 "Reserved" 1 "Active Isolation Test request" 0 "Active Isolation Test not requested" ;
VAL_ 2351890174 PwrDownCmd 3 "Don't care/Take no action" 2 "Execute emergency power-down" 1 "Execute normal power-down" 0 "Power-down not requested" ;
VAL_ 2351890174 HVBusConnectCmd 3 "Don't care/Take no action" 2 "Emergency contactor closure request" 1 "Close Contactor" 0 "Open Contactor" ;
VAL_ 2351824638 ThermalMnmgtMaintenanceReq 3 "Don't care/take no action" 2 "Reserved" 1 "HVESS Thermal Management Maintenance Mode is requested" 0 "HVESS Thermal Management Maintenance Mode is not requested" ;
VAL_ 2351824638 HVBusLowSideResistorConnectReq 3 "Don't care/take no action" 2 "Reserved" 1 "Connection Requested" 0 "Connection not Requested" ;
VAL_ 2351824638 HVBusHiSideResistorConnectReq 3 "Don't care/take no action" 2 "Reserved" 1 "Connection Requested" 0 "Connection not Requested" ;
VAL_ 2351824638 OpConsent 3 "Don't care/Take no action" 2 "Error" 1 "Consent given" 0 "Consent revoked" ;
VAL_ 2351824638 EnableInternalChargerCmd 3 "Don't care/Take no action" 2 "Reserved" 1 "Enable charging" 0 "Disable charging" ;
VAL_ 2351824638 CellBalancingCmd 3 "Don't care/Take no action" 2 "Reserved" 1 "Cell Balancing requested" 0 "Cell Balancing not requested" ;
VAL_ 2351824638 HVBusPassiveIsolTestCmd 3 "Don't care/Take no action" 2 "Reserved" 1 "Passive Isolation Test request" 0 "Passive Isolation Test not requested" ;
VAL_ 2351824638 HVBusActiveIsolTestCmd 3 "Don't care/Take no action" 2 "Reserved" 1 "Active Isolation Test request" 0 "Active Isolation Test not requested" ;
VAL_ 2351824638 PwrDownCmd 3 "Don't care/Take no action" 2 "Execute emergency power-down" 1 "Execute normal power-down" 0 "Power-down not requested" ;
VAL_ 2351824638 HVBusConnectCmd 3 "Don't care/Take no action" 2 "Emergency contactor closure request" 1 "Close Contactor" 0 "Open Contactor" ;
VAL_ 2351759102 ThermalMnmgtMaintenanceReq 3 "Don't care/take no action" 2 "Reserved" 1 "HVESS Thermal Management Maintenance Mode is requested" 0 "HVESS Thermal Management Maintenance Mode is not requested" ;
VAL_ 2351759102 HVBusLowSideResistorConnectReq 3 "Don't care/take no action" 2 "Reserved" 1 "Connection Requested" 0 "Connection not Requested" ;
VAL_ 2351759102 HVBusHiSideResistorConnectReq 3 "Don't care/take no action" 2 "Reserved" 1 "Connection Requested" 0 "Connection not Requested" ;
VAL_ 2351759102 OpConsent 3 "Don't care/Take no action" 2 "Error" 1 "Consent given" 0 "Consent revoked" ;
VAL_ 2351759102 EnableInternalChargerCmd 3 "Don't care/Take no action" 2 "Reserved" 1 "Enable charging" 0 "Disable charging" ;
VAL_ 2351759102 CellBalancingCmd 3 "Don't care/Take no action" 2 "Reserved" 1 "Cell Balancing requested" 0 "Cell Balancing not requested" ;
VAL_ 2351759102 HVBusPassiveIsolTestCmd 3 "Don't care/Take no action" 2 "Reserved" 1 "Passive Isolation Test request" 0 "Passive Isolation Test not requested" ;
VAL_ 2351759102 HVBusActiveIsolTestCmd 3 "Don't care/Take no action" 2 "Reserved" 1 "Active Isolation Test request" 0 "Active Isolation Test not requested" ;
VAL_ 2351759102 PwrDownCmd 3 "Don't care/Take no action" 2 "Execute emergency power-down" 1 "Execute normal power-down" 0 "Power-down not requested" ;
VAL_ 2351759102 HVBusConnectCmd 3 "Don't care/Take no action" 2 "Emergency contactor closure request" 1 "Close Contactor" 0 "Open Contactor" ;
VAL_ 2351693566 ThermalMnmgtMaintenanceReq 3 "Don't care/take no action" 2 "Reserved" 1 "HVESS Thermal Management Maintenance Mode is requested" 0 "HVESS Thermal Management Maintenance Mode is not requested" ;
VAL_ 2351693566 HVBusLowSideResistorConnectReq 3 "Don't care/take no action" 2 "Reserved" 1 "Connection Requested" 0 "Connection not Requested" ;
VAL_ 2351693566 HVBusHiSideResistorConnectReq 3 "Don't care/take no action" 2 "Reserved" 1 "Connection Requested" 0 "Connection not Requested" ;
VAL_ 2351693566 OpConsent 3 "Don't care/Take no action" 2 "Error" 1 "Consent given" 0 "Consent revoked" ;
VAL_ 2351693566 EnableInternalChargerCmd 3 "Don't care/Take no action" 2 "Reserved" 1 "Enable charging" 0 "Disable charging" ;
VAL_ 2351693566 CellBalancingCmd 3 "Don't care/Take no action" 2 "Reserved" 1 "Cell Balancing requested" 0 "Cell Balancing not requested" ;
VAL_ 2351693566 HVBusPassiveIsolTestCmd 3 "Don't care/Take no action" 2 "Reserved" 1 "Passive Isolation Test request" 0 "Passive Isolation Test not requested" ;
VAL_ 2351693566 HVBusActiveIsolTestCmd 3 "Don't care/Take no action" 2 "Reserved" 1 "Active Isolation Test request" 0 "Active Isolation Test not requested" ;
VAL_ 2351693566 PwrDownCmd 3 "Don't care/Take no action" 2 "Execute emergency power-down" 1 "Execute normal power-down" 0 "Power-down not requested" ;
VAL_ 2351693566 HVBusConnectCmd 3 "Don't care/Take no action" 2 "Emergency contactor closure request" 1 "Close Contactor" 0 "Open Contactor" ;
VAL_ 2351628030 ThermalMnmgtMaintenanceReq 3 "Don't care/take no action" 2 "Reserved" 1 "HVESS Thermal Management Maintenance Mode is requested" 0 "HVESS Thermal Management Maintenance Mode is not requested" ;
VAL_ 2351628030 HVBusLowSideResistorConnectReq 3 "Don't care/take no action" 2 "Reserved" 1 "Connection Requested" 0 "Connection not Requested" ;
VAL_ 2351628030 HVBusHiSideResistorConnectReq 3 "Don't care/take no action" 2 "Reserved" 1 "Connection Requested" 0 "Connection not Requested" ;
VAL_ 2351628030 OpConsent 3 "Don't care/Take no action" 2 "Error" 1 "Consent given" 0 "Consent revoked" ;
VAL_ 2351628030 EnableInternalChargerCmd 3 "Don't care/Take no action" 2 "Reserved" 1 "Enable charging" 0 "Disable charging" ;
VAL_ 2351628030 CellBalancingCmd 3 "Don't care/Take no action" 2 "Reserved" 1 "Cell Balancing requested" 0 "Cell Balancing not requested" ;
VAL_ 2351628030 HVBusPassiveIsolTestCmd 3 "Don't care/Take no action" 2 "Reserved" 1 "Passive Isolation Test request" 0 "Passive Isolation Test not requested" ;
VAL_ 2351628030 HVBusActiveIsolTestCmd 3 "Don't care/Take no action" 2 "Reserved" 1 "Active Isolation Test request" 0 "Active Isolation Test not requested" ;
VAL_ 2351628030 PwrDownCmd 3 "Don't care/Take no action" 2 "Execute emergency power-down" 1 "Execute normal power-down" 0 "Power-down not requested" ;
VAL_ 2351628030 HVBusConnectCmd 3 "Don't care/Take no action" 2 "Emergency contactor closure request" 1 "Close Contactor" 0 "Open Contactor" ;
VAL_ 2351431422 SetpointModeReq 31 "Don't Care/Take No Action" 30 "SAE Reserved" 29 "Manufacturer specific special mode 2" 28 "Manufacturer specific special mode 1" 27 "Manufacturer specific special mode 4" 26 "Manufacturer specific special mode 3" 25 "SAE Reserved" 24 "SAE Reserved" 23 "SAE Reserved" 22 "SAE Reserved" 21 "Inverter power down command mode" 20 "Inverter active discharge mode e.g" 19 "Manufacturer specific active mode 2" 18 "Manufacturer specific active mode 1" 17 "SAE Reserved" 16 "SAE Reserved" 15 "SAE Reserved" 14 "SAE Reserved" 13 "SAE Reserved" 12 "Enable Mechanical Power Control Mode" 11 "Enable DC Power Control Mode" 10 "Enable DC Side Current Mode" 9 "Enable DC Side Voltage Mode" 8 "Enable Speed Control Mode" 7 "Enable Torque Control Mode" 6 "Manufacturer specific passive mode 2" 5 "Manufacturer specific passive mode 1" 4 "SAE Reserved" 3 "SAE Reserved" 2 "Standby" 1 "SAE Reserved" 0 "Power On" ;
VAL_ 2351365886 SetpointModeReq 16 "SAE Reserved" 15 "SAE Reserved" 14 "SAE Reserved" 13 "SAE Reserved" 12 "Enable Mechanical Power Control Mode" 31 "Don't Care/Take No Action" 30 "SAE Reserved" 29 "Manufacturer specific special mode 2" 28 "Manufacturer specific special mode 1" 27 "Manufacturer specific special mode 4" 26 "Manufacturer specific special mode 3" 25 "SAE Reserved" 24 "SAE Reserved" 23 "SAE Reserved" 22 "SAE Reserved" 21 "Inverter power down command mode" 20 "Inverter active discharge mode e.g" 19 "Manufacturer specific active mode 2" 18 "Manufacturer specific active mode 1" 17 "SAE Reserved" 11 "Enable DC Power Control Mode" 10 "Enable DC Side Current Mode" 9 "Enable DC Side Voltage Mode" 8 "Enable Speed Control Mode" 7 "Enable Torque Control Mode" 6 "Manufacturer specific passive mode 2" 5 "Manufacturer specific passive mode 1" 4 "SAE Reserved" 3 "SAE Reserved" 2 "Standby" 1 "SAE Reserved" 0 "Power On" ;
VAL_ 2633748222 SPNModifiedStatus 3 "Not available" 2 "SP's receive status could be modified as requested." 1 "SP's receive status was not requested to be modified." 0 "SP's receive status could not be modified" ;
VAL_ 2633748222 SPNSA 255 "The Configurable ECU will process the Configurable Receive SP from any source address on the port identified in SPN 8842." 254 "No source address has been configured for this Configurable Receive SP." ;
VAL_ 2633748222 PortCmdStatus 7 "Not available" 6 "SAE Reserved" 5 "SAE Reserved" 4 "SAE Reserved" 3 "SAE Reserved" 2 "No Configurable SPs exist for the port identified in SPN 8842." 1 "Negative Acknowledgment" 0 "Positive Acknowledgment" ;
VAL_ 2633748222 PortPendingChangesStatus 1 "Receive changes are pending for one or more supported SPs on the port identified in SPN 8842." 0 "No pending changes to the receive status for any supported SPs for the port identified in SPN 8842." ;
VAL_ 2633748222 Port 15 "SAE Reserved" 14 "SAE Reserved" 13 "SAE Reserved" 12 "SAE Reserved" 11 "SAE Reserved" 10 "Port 10" 9 "Port 9" 8 "Port 8" 7 "Port 7" 6 "Port 6" 5 "Port 5" 4 "Port 4" 3 "Port 3" 2 "Port 2" 1 "Port 1" 0 "Current port" ;
VAL_ 2566639102 PlungerFiringOrderSetting 15 "Not available" 14 "Error" 13 "Reserved" 12 "Reserved" 11 "Reserved" 10 "Reserved" 9 "Reserved" 8 "Reserved" 7 "Reserved" 6 "Reserved" 5 "Reserved" 4 "Reserved" 3 "Reserved" 2 "Reserved" 1 "Firing order 1-5-2-3-4" 0 "Firing order 1-2-3" ;
VAL_ 2566632190 DisPressCalSetPointStatus 3 "Not available" 2 "Error" 1 "OK" 0 "Not OK" ;
VAL_ 2566632190 DisPressCalSetPoint 15 "Not Available" 14 "Error" 13 "Reserved" 12 "Reset Calibration" 11 "Correction Point" 10 "End Point" 9 "Calibration Reference Point 9" 8 "Calibration Reference Point 8" 7 "Calibration Reference Point 7" 6 "Calibration Reference Point 6" 5 "Calibration Reference Point 5" 4 "Calibration Reference Point 4" 3 "Calibration Reference Point 3" 2 "Calibration Reference Point 2" 1 "Calibration Reference Point 1" 0 "Zero Point" ;
VAL_ 2566632190 SuctionPressCalSetPointStatus 3 "Not available" 2 "Error" 1 "OK" 0 "Not OK" ;
VAL_ 2566632190 SuctionPressCalSetPoint 15 "Not Available" 14 "Error" 13 "Reserved" 12 "Reset Calibration" 11 "Correction Point" 10 "End Point" 9 "Calibration Reference Point 9" 8 "Calibration Reference Point 8" 7 "Calibration Reference Point 7" 6 "Calibration Reference Point 6" 5 "Calibration Reference Point 5" 4 "Calibration Reference Point 4" 3 "Calibration Reference Point 3" 2 "Calibration Reference Point 2" 1 "Calibration Reference Point 1" 0 "Zero Point" ;
